VERSION "created by canmatrix"

NS_ :

BS_:

BU_: IPD

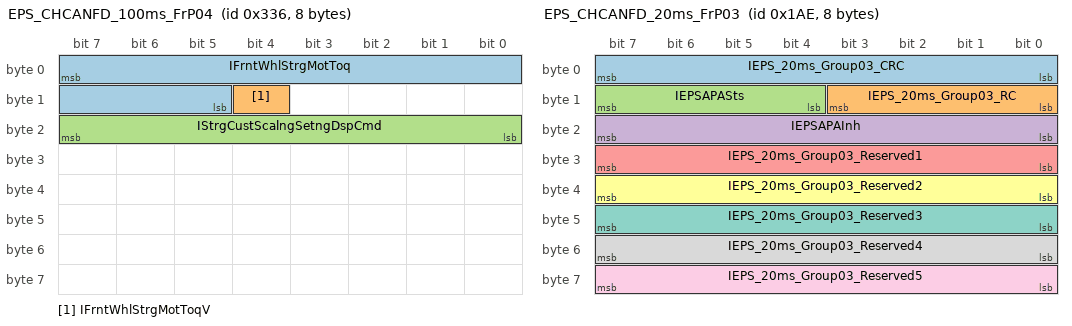
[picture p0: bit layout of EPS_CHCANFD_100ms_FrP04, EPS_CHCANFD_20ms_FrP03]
BO_ 822 EPS_CHCANFD_100ms_FrP04: 8 Vector__XXX
 SG_ IFrntWhlStrgMotToq : 7|11@0+ (0.01,-10.24) [-10.24|10.23] "Nm" IPD
 SG_ IFrntWhlStrgMotToqV : 12|1@0+ (1,0) [0|1] "null" IPD
 SG_ IStrgCustScalngSetngDspCmd : 23|8@0+ (1,0) [0|255] "percent" IPD

BO_ 430 EPS_CHCANFD_20ms_FrP03: 8 Vector__XXX
 SG_ IEPS_20ms_Group03_CRC : 7|8@0+ (1,0) [0|255] "null" IPD
 SG_ IEPS_20ms_Group03_RC : 11|4@0+ (1,0) [0|15] "null" IPD
 SG_ IEPSAPASts : 15|4@0+ (1,0) [0|15] "null" IPD
 SG_ IEPSAPAInh : 23|8@0+ (1,0) [0|255] "null" IPD
 SG_ IEPS_20ms_Group03_Reserved1 : 31|8@0+ (1,0) [0|255] "null" IPD
 SG_ IEPS_20ms_Group03_Reserved2 : 39|8@0+ (1,0) [0|255] "null" IPD
 SG_ IEPS_20ms_Group03_Reserved3 : 47|8@0+ (1,0) [0|255] "null" IPD
 SG_ IEPS_20ms_Group03_Reserved4 : 55|8@0+ (1,0) [0|255] "null" IPD
 SG_ IEPS_20ms_Group03_Reserved5 : 63|8@0+ (1,0) [0|255] "null" IPD

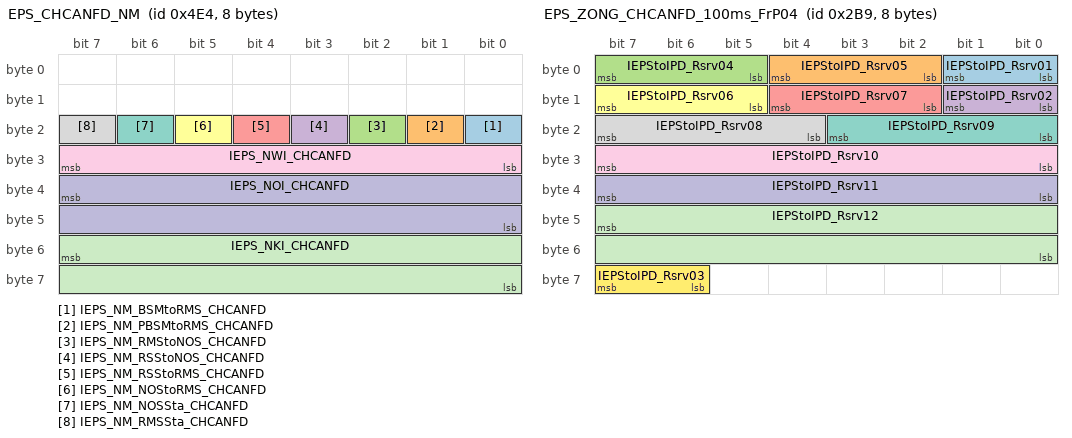
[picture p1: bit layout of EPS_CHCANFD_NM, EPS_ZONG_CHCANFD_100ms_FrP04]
BO_ 1252 EPS_CHCANFD_NM: 8 Vector__XXX
 SG_ IEPS_NM_BSMtoRMS_CHCANFD : 16|1@0+ (1,0) [0|1] "null" Vector__XXX
 SG_ IEPS_NM_PBSMtoRMS_CHCANFD : 17|1@0+ (1,0) [0|1] "null" Vector__XXX
 SG_ IEPS_NM_RMStoNOS_CHCANFD : 18|1@0+ (1,0) [0|1] "null" Vector__XXX
 SG_ IEPS_NM_RSStoNOS_CHCANFD : 19|1@0+ (1,0) [0|1] "null" Vector__XXX
 SG_ IEPS_NM_RSStoRMS_CHCANFD : 20|1@0+ (1,0) [0|1] "null" Vector__XXX
 SG_ IEPS_NM_NOStoRMS_CHCANFD : 21|1@0+ (1,0) [0|1] "null" Vector__XXX
 SG_ IEPS_NM_NOSSta_CHCANFD : 22|1@0+ (1,0) [0|1] "null" Vector__XXX
 SG_ IEPS_NM_RMSSta_CHCANFD : 23|1@0+ (1,0) [0|1] "null" Vector__XXX
 SG_ IEPS_NWI_CHCANFD : 31|8@0+ (1,0) [0|255] "null" Vector__XXX
 SG_ IEPS_NOI_CHCANFD : 39|16@0+ (1,0) [0|65535] "null" Vector__XXX
 SG_ IEPS_NKI_CHCANFD : 55|16@0+ (1,0) [0|65535] "null" IPD

BO_ 697 EPS_ZONG_CHCANFD_100ms_FrP04: 8 Vector__XXX
 SG_ IEPStoIPD_Rsrv01 : 1|2@0+ (1,0) [0|3] "null" IPD
 SG_ IEPStoIPD_Rsrv05 : 4|3@0+ (1,0) [0|7] "null" IPD
 SG_ IEPStoIPD_Rsrv04 : 7|3@0+ (1,0) [0|7] "null" IPD
 SG_ IEPStoIPD_Rsrv02 : 9|2@0+ (1,0) [0|3] "null" IPD
 SG_ IEPStoIPD_Rsrv07 : 12|3@0+ (1,0) [0|7] "null" IPD
 SG_ IEPStoIPD_Rsrv06 : 15|3@0+ (1,0) [0|7] "null" IPD
 SG_ IEPStoIPD_Rsrv09 : 19|4@0+ (1,0) [0|15] "null" IPD
 SG_ IEPStoIPD_Rsrv08 : 23|4@0+ (1,0) [0|15] "null" IPD
 SG_ IEPStoIPD_Rsrv10 : 31|8@0+ (1,0) [0|255] "null" IPD
 SG_ IEPStoIPD_Rsrv11 : 39|8@0+ (1,0) [0|255] "null" IPD
 SG_ IEPStoIPD_Rsrv12 : 47|16@0+ (1,0) [0|65535] "null" IPD
 SG_ IEPStoIPD_Rsrv03 : 63|2@0+ (1,0) [0|3] "null" IPD

BO_ 956 FVCM_BKPCANFD_100ms_FrP05: 64 IPD
 SG_ IPilotSysMsg : 15|4@0+ (1,0) [0|15] "null" Vector__XXX
 SG_ ILane0_C0 : 23|12@0+ (0.00390625,-8) [-8.00000000|7.99609375] "null" Vector__XXX
 SG_ ILane0_C1 : 27|12@0+ (0.00048828125,-1) [-1.00000000000|0.99951171875] "null" Vector__XXX
 SG_ ILane0_C2 : 47|12@0+ (0.000015259,-0.03124285) [-0.031242850|0.031242755] "null" Vector__XXX
 SG_ ILane0_C3 : 51|12@0+ (4.768E-007,-2.3842E-007) [-2.3842E-007|0.00195225758] "null" Vector__XXX
 SG_ ILane1_C0 : 71|12@0+ (0.00390625,-8) [-8.00000000|7.99609375] "null" Vector__XXX
 SG_ ILane1_C1 : 75|12@0+ (0.00048828125,-1) [-1.00000000000|0.99951171875] "null" Vector__XXX
 SG_ ILane1_C2 : 95|12@0+ (0.000015259,-0.03124285) [-0.031242850|0.031242755] "null" Vector__XXX
 SG_ ILane1_C3 : 99|12@0+ (4.768E-007,-2.3842E-007) [-2.3842E-007|0.00195225758] "null" Vector__XXX
 SG_ ILane0_ViewRangeStart : 215|8@0+ (0.25,0) [0.00|63.75] "null" Vector__XXX
 SG_ ILane1_ViewRangeStart : 223|8@0+ (0.25,0) [0.00|63.75] "null" Vector__XXX
 SG_ ILane0_ViewRangeEnd : 247|9@0+ (0.25,0) [0.00|127.75] "null" Vector__XXX
 SG_ ILane1_ViewRangeEnd : 248|9@0+ (0.25,0) [0.00|127.75] "null" Vector__XXX
 SG_ ILane0_ExistPrblty : 254|6@0+ (0.015625,0) [0.000000|0.984375] "null" Vector__XXX
 SG_ ILane1_ExistPrblty : 278|6@0+ (0.015625,0) [0.000000|0.984375] "null" Vector__XXX
 SG_ ILane0_ID : 295|4@0+ (1,0) [0|15] "null" Vector__XXX
 SG_ ILane1_ID : 303|4@0+ (1,0) [0|15] "null" Vector__XXX
 SG_ ITLRMsgReq : 321|2@0+ (1,0) [0|3] "null" Vector__XXX
 SG_ ILane0_location : 327|3@0+ (1,0) [0|7] "null" Vector__XXX
 SG_ ITLRSysSts : 329|2@0+ (1,0) [0|3] "null" Vector__XXX
 SG_ ILane1_location : 332|3@0+ (1,0) [0|7] "null" Vector__XXX
 SG_ ITrgtSpdSrcSts_IPD : 337|2@0+ (1,0) [0|3] "null" Vector__XXX
 SG_ ISLIFWrnngMdResp : 345|2@0+ (1,0) [0|3] "null" Vector__XXX
 SG_ ITLRWarning : 388|3@0+ (1,0) [0|7] "null" Vector__XXX
 SG_ ITLRMdSwDspCmd : 391|3@0+ (1,0) [0|7] "null" Vector__XXX
 SG_ ISpdLmtOfstSetResp : 399|6@0+ (1,-20) [-20|43] "null" Vector__XXX
 SG_ ISLIFAudWrnng_IPD : 472|1@0+ (1,0) [0|1] "null" Vector__XXX
 SG_ ISLIFUpdtIndResp_IPD : 473|1@0+ (1,0) [0|1] "null" Vector__XXX
 SG_ ISLIFUpdtInd_IPD : 500|1@0+ (1,0) [0|1] "null" Vector__XXX
 SG_ ICCSpdVcCmdCnfm : 503|3@0+ (1,0) [0|7] "null" Vector__XXX

BO_ 163 FVCM_BKPCANFD_10ms_FrP01: 12 IPD
 SG_ IFVCM_10ms_Group01_CRC : 7|8@0+ (1,0) [0|255] "null" Vector__XXX
 SG_ IFVCM_10ms_Group01_RC : 11|4@0+ (1,0) [0|15] "null" Vector__XXX
 SG_ ILKAReqToqSts : 13|2@0+ (1,0) [0|3] "null" Vector__XXX
 SG_ ILKAReqAngSts : 15|2@0+ (1,0) [0|3] "null" Vector__XXX
 SG_ ILKAReqAng : 23|16@0+ (0.005,-163) [-163.000|164.675] "Degree" Vector__XXX
 SG_ ILKAReqToq : 39|11@0+ (0.01,-10.24) [-10.24|10.23] "Nm" Vector__XXX
 SG_ IFVCM_10ms_Group01_Reserved1 : 44|5@0+ (1,0) [0|31] "null" Vector__XXX
 SG_ IFVCM_10ms_Group01_Reserved2 : 55|8@0+ (1,0) [0|255] "null" Vector__XXX
 SG_ IFVCM_10ms_Group01_Reserved3 : 63|8@0+ (1,0) [0|255] "null" Vector__XXX
 SG_ IFVCM_10ms_Group01_Reserved4 : 71|8@0+ (1,0) [0|255] "null" Vector__XXX
 SG_ IFVCM_10ms_Group01_Reserved5 : 79|8@0+ (1,0) [0|255] "null" Vector__XXX
 SG_ IFVCM_10ms_Group01_Reserved6 : 87|8@0+ (1,0) [0|255] "null" Vector__XXX
 SG_ IFVCM_10ms_Group01_Reserved7 : 95|8@0+ (1,0) [0|255] "null" Vector__XXX

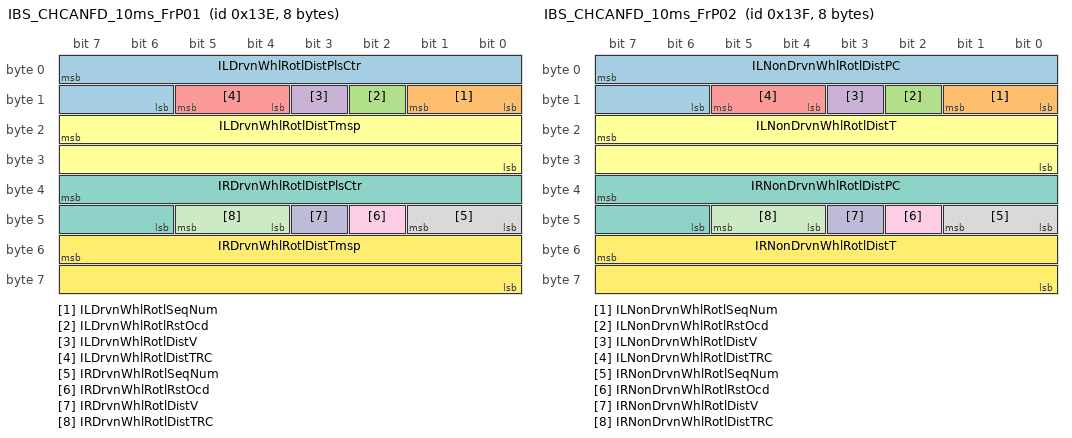
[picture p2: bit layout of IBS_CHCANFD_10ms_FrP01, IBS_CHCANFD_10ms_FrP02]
BO_ 318 IBS_CHCANFD_10ms_FrP01: 8 Vector__XXX
 SG_ ILDrvnWhlRotlDistPlsCtr : 7|10@0+ (1,0) [0|1023] "null" IPD
 SG_ ILDrvnWhlRotlSeqNum : 9|2@0+ (1,0) [0|3] "null" IPD
 SG_ ILDrvnWhlRotlRstOcd : 10|1@0+ (1,0) [0|1] "null" IPD
 SG_ ILDrvnWhlRotlDistV : 11|1@0+ (1,0) [0|1] "null" IPD
 SG_ ILDrvnWhlRotlDistTRC : 13|2@0+ (1,0) [0|3] "null" IPD
 SG_ ILDrvnWhlRotlDistTmsp : 23|16@0+ (1,0) [0|65535] "null" IPD
 SG_ IRDrvnWhlRotlDistPlsCtr : 39|10@0+ (1,0) [0|1023] "null" IPD
 SG_ IRDrvnWhlRotlSeqNum : 41|2@0+ (1,0) [0|3] "ms" IPD
 SG_ IRDrvnWhlRotlRstOcd : 42|1@0+ (1,0) [0|1] "null" IPD
 SG_ IRDrvnWhlRotlDistV : 43|1@0+ (1,0) [0|1] "null" IPD
 SG_ IRDrvnWhlRotlDistTRC : 45|2@0+ (1,0) [0|3] "ms" IPD
 SG_ IRDrvnWhlRotlDistTmsp : 55|16@0+ (1,0) [0|65535] "ms" IPD

BO_ 319 IBS_CHCANFD_10ms_FrP02: 8 Vector__XXX
 SG_ ILNonDrvnWhlRotlDistPC : 7|10@0+ (1,0) [0|1023] "null" IPD
 SG_ ILNonDrvnWhlRotlSeqNum : 9|2@0+ (1,0) [0|3] "null" IPD
 SG_ ILNonDrvnWhlRotlRstOcd : 10|1@0+ (1,0) [0|1] "null" IPD
 SG_ ILNonDrvnWhlRotlDistV : 11|1@0+ (1,0) [0|1] "null" IPD
 SG_ ILNonDrvnWhlRotlDistTRC : 13|2@0+ (1,0) [0|3] "null" IPD
 SG_ ILNonDrvnWhlRotlDistT : 23|16@0+ (1,0) [0|65535] "null" IPD
 SG_ IRNonDrvnWhlRotlDistPC : 39|10@0+ (1,0) [0|1023] "null" IPD
 SG_ IRNonDrvnWhlRotlSeqNum : 41|2@0+ (1,0) [0|3] "null" IPD
 SG_ IRNonDrvnWhlRotlRstOcd : 42|1@0+ (1,0) [0|1] "null" IPD
 SG_ IRNonDrvnWhlRotlDistV : 43|1@0+ (1,0) [0|1] "null" IPD
 SG_ IRNonDrvnWhlRotlDistTRC : 45|2@0+ (1,0) [0|3] "null" IPD
 SG_ IRNonDrvnWhlRotlDistT : 55|16@0+ (1,0) [0|65535] "null" IPD

BO_ 423 IBS_CHCANFD_20ms_FrP07: 8 Vector__XXX
 SG_ IIBS_20ms_Group07_CRC : 7|8@0+ (1,0) [0|255] "null" IPD
 SG_ IIBS_20ms_Group07_RC : 11|4@0+ (1,0) [0|15] "null" IPD
 SG_ IHDCSysSts : 14|3@0+ (1,0) [0|7] "null" IPD
 SG_ IABSIO : 15|1@0+ (1,0) [0|1] "null" IPD
 SG_ IVSESysA : 16|1@0+ (1,0) [0|1] "null" IPD
 SG_ IBrkSysYlwBrkTlltReq : 17|1@0+ (1,0) [0|1] "null" IPD
 SG_ IVSESts : 20|3@0+ (1,0) [0|7] "null" IPD
 SG_ IVSEMd : 23|3@0+ (1,0) [0|7] "null" IPD
 SG_ IMultColBrkEnbA : 24|1@0+ (1,0) [0|1] "null" IPD
 SG_ IEBDFaultSt : 25|1@0+ (1,0) [0|1] "null" IPD
 SG_ ITCSOpngSts : 28|3@0+ (1,0) [0|7] "null" IPD
 SG_ ITCSOpngMd : 31|3@0+ (1,0) [0|7] "null" IPD
 SG_ IBrkSysHillStAstAvlbl : 32|1@0+ (1,0) [0|1] "null" IPD
 SG_ IRgtvBrkFnFltSts : 33|1@0+ (1,0) [0|1] "null" IPD
 SG_ IMSRF : 34|1@0+ (1,0) [0|1] "null" IPD
 SG_ IAutoHoldSysSts : 36|2@0+ (1,0) [0|3] "null" IPD
 SG_ IAutoHoldMsg : 39|3@0+ (1,0) [0|7] "null" IPD
 SG_ IEBDA : 40|1@0+ (1,0) [0|1] "null" IPD
 SG_ IRgtvBrkFnSts : 41|1@0+ (1,0) [0|1] "null" IPD
 SG_ ITCSEnbd : 42|1@0+ (1,0) [0|1] "null" IPD
 SG_ IHBAActiveSt : 43|1@0+ (1,0) [0|1] "null" IPD
 SG_ ITCSA : 44|1@0+ (1,0) [0|1] "null" IPD
 SG_ IEnDragToqRducnA : 45|1@0+ (1,0) [0|1] "null" IPD
 SG_ IABSF : 46|1@0+ (1,0) [0|1] "null" IPD
 SG_ IABSA : 47|1@0+ (1,0) [0|1] "null" IPD
 SG_ IHBAValidSt : 48|1@0+ (1,0) [0|1] "null" IPD
 SG_ IMSRA : 49|1@0+ (1,0) [0|1] "null" IPD
 SG_ IEmgcBrkAV : 50|1@0+ (1,0) [0|1] "null" IPD
 SG_ IEmgcBrkA : 51|1@0+ (1,0) [0|1] "null" IPD
 SG_ IBrkSysRedBrkTlltReq : 52|1@0+ (1,0) [0|1] "null" IPD
 SG_ IBrkSysHillStAstSts : 55|3@0+ (1,0) [0|7] "null" IPD
 SG_ IAVHSigPdlSts : 57|2@0+ (1,0) [0|3] "null" IPD
 SG_ IAutoHoldMdSts : 59|2@0+ (1,0) [0|3] "null" IPD
 SG_ ISoftSpSysSts : 61|2@0+ (1,0) [0|3] "null" IPD
 SG_ IMulColBrkA : 62|1@0+ (1,0) [0|1] "null" IPD
 SG_ IMulColBrkAvlblySts : 63|1@0+ (1,0) [0|1] "null" IPD

BO_ 342 IBS_CHCANFD_20ms_FrP08: 8 Vector__XXX
 SG_ IIBS_20ms_Group08_CRC : 7|8@0+ (1,0) [0|255] "null" IPD
 SG_ IIBS_20ms_Group08_RC : 11|4@0+ (1,0) [0|15] "null" IPD
 SG_ IEPBSts : 13|2@0+ (1,0) [0|3] "null" IPD
 SG_ IEPBAppcnSts : 15|2@0+ (1,0) [0|3] "null" IPD
 SG_ IEPBCCCanclReqd : 16|1@0+ (1,0) [0|1] "null" IPD
 SG_ IEPBSysStsIndReq : 18|2@0+ (1,0) [0|3] "null" IPD
 SG_ IEPBSwSts : 20|2@0+ (1,0) [0|3] "null" IPD
 SG_ IEPBAvlblySts : 23|3@0+ (1,0) [0|7] "null" IPD
 SG_ IEPBSysAudWrnngReq : 25|2@0+ (1,0) [0|3] "null" IPD
 SG_ IEPBSwStsV : 26|1@0+ (1,0) [0|1] "null" IPD
 SG_ IEPBSysWrnngIndReq : 28|2@0+ (1,0) [0|3] "null" IPD
 SG_ IEPBSysDspMsgReq : 31|3@0+ (1,0) [0|7] "null" IPD
 SG_ IChSysTrBrkAxleToqVal : 37|14@0+ (2,0) [0|32766] "Nm" IPD
 SG_ IEPBAPAAvlbl : 38|1@0+ (1,0) [0|1] "null" IPD
 SG_ IEPBFlrSts : 39|1@0+ (1,0) [0|1] "null" IPD
 SG_ IChSysSecyBrkAxleToqVal : 53|14@0+ (2,0) [0|32766] "Nm" IPD
 SG_ IChSysSecyBrkAxleToqValV : 54|1@0+ (1,0) [0|1] "null" IPD
 SG_ IChSysTrBrkAxleToqValV : 55|1@0+ (1,0) [0|1] "null" IPD

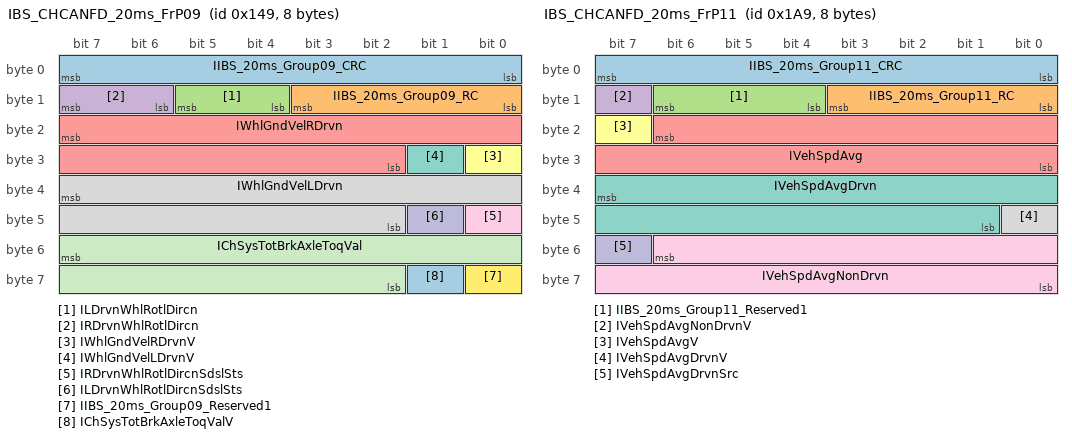
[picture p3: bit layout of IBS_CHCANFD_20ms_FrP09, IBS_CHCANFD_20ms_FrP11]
BO_ 329 IBS_CHCANFD_20ms_FrP09: 8 Vector__XXX
 SG_ IIBS_20ms_Group09_CRC : 7|8@0+ (1,0) [0|255] "ms" IPD
 SG_ IIBS_20ms_Group09_RC : 11|4@0+ (1,0) [0|15] "ms" IPD
 SG_ ILDrvnWhlRotlDircn : 13|2@0+ (1,0) [0|3] "null" IPD
 SG_ IRDrvnWhlRotlDircn : 15|2@0+ (1,0) [0|3] "null" IPD
 SG_ IWhlGndVelRDrvn : 23|14@0+ (0.03125,0) [0.00000|511.96875] "kph" IPD
 SG_ IWhlGndVelRDrvnV : 24|1@0+ (1,0) [0|1] "null" IPD
 SG_ IWhlGndVelLDrvnV : 25|1@0+ (1,0) [0|1] "null" IPD
 SG_ IWhlGndVelLDrvn : 39|14@0+ (0.03125,0) [0.00000|511.96875] "kph" IPD
 SG_ IRDrvnWhlRotlDircnSdslSts : 40|1@0+ (1,0) [0|1] "null" IPD
 SG_ ILDrvnWhlRotlDircnSdslSts : 41|1@0+ (1,0) [0|1] "null" IPD
 SG_ IChSysTotBrkAxleToqVal : 55|14@0+ (2,0) [0|32766] "Nm" IPD
 SG_ IIBS_20ms_Group09_Reserved1 : 56|1@0+ (1,0) [0|1] "null" IPD
 SG_ IChSysTotBrkAxleToqValV : 57|1@0+ (1,0) [0|1] "null" IPD

BO_ 425 IBS_CHCANFD_20ms_FrP11: 8 Vector__XXX
 SG_ IIBS_20ms_Group11_CRC : 7|8@0+ (1,0) [0|255] "null" IPD
 SG_ IIBS_20ms_Group11_RC : 11|4@0+ (1,0) [0|15] "null" IPD
 SG_ IIBS_20ms_Group11_Reserved1 : 14|3@0+ (1,0) [0|7] "null" IPD
 SG_ IVehSpdAvgNonDrvnV : 15|1@0+ (1,0) [0|1] "null" IPD
 SG_ IVehSpdAvg : 22|15@0+ (0.015625,0) [0.000000|511.984375] "km/h" IPD
 SG_ IVehSpdAvgV : 23|1@0+ (1,0) [0|1] "null" IPD
 SG_ IVehSpdAvgDrvn : 39|15@0+ (0.015625,0) [0.000000|511.984375] "km/h" IPD
 SG_ IVehSpdAvgDrvnV : 40|1@0+ (1,0) [0|1] "null" IPD
 SG_ IVehSpdAvgNonDrvn : 54|15@0+ (0.015625,0) [0.000000|511.984375] "km/h" IPD
 SG_ IVehSpdAvgDrvnSrc : 55|1@0+ (1,0) [0|1] "null" IPD

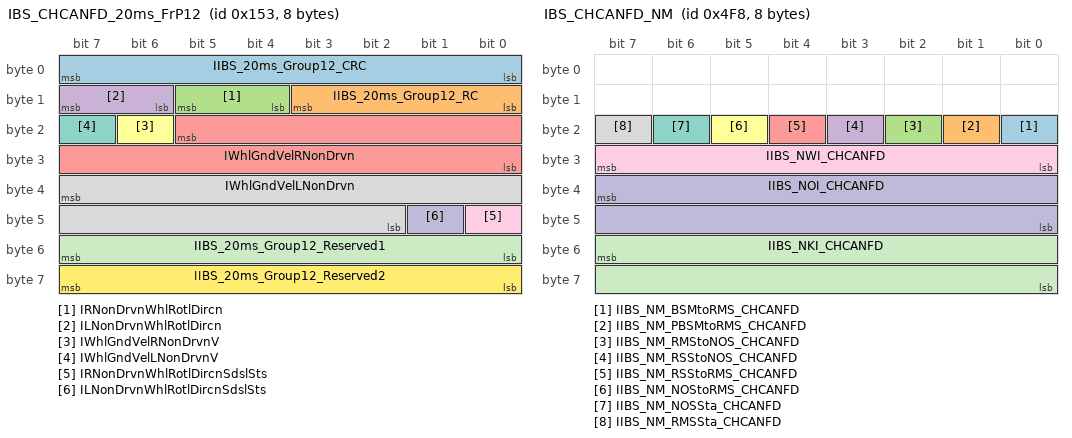
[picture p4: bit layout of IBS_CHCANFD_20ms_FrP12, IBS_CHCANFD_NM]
BO_ 339 IBS_CHCANFD_20ms_FrP12: 8 Vector__XXX
 SG_ IIBS_20ms_Group12_CRC : 7|8@0+ (1,0) [0|255] "ms" IPD
 SG_ IIBS_20ms_Group12_RC : 11|4@0+ (1,0) [0|15] "ms" IPD
 SG_ IRNonDrvnWhlRotlDircn : 13|2@0+ (1,0) [0|3] "null" IPD
 SG_ ILNonDrvnWhlRotlDircn : 15|2@0+ (1,0) [0|3] "null" IPD
 SG_ IWhlGndVelRNonDrvn : 21|14@0+ (0.03125,0) [0.00000|511.96875] "kph" IPD
 SG_ IWhlGndVelRNonDrvnV : 22|1@0+ (1,0) [0|1] "null" IPD
 SG_ IWhlGndVelLNonDrvnV : 23|1@0+ (1,0) [0|1] "null" IPD
 SG_ IWhlGndVelLNonDrvn : 39|14@0+ (0.03125,0) [0.00000|511.96875] "kph" IPD
 SG_ IRNonDrvnWhlRotlDircnSdslSts : 40|1@0+ (1,0) [0|1] "null" IPD
 SG_ ILNonDrvnWhlRotlDircnSdslSts : 41|1@0+ (1,0) [0|1] "null" IPD
 SG_ IIBS_20ms_Group12_Reserved1 : 55|8@0+ (1,0) [0|255] "null" IPD
 SG_ IIBS_20ms_Group12_Reserved2 : 63|8@0+ (1,0) [0|255] "null" IPD

BO_ 1688 IBS_CHCANFD_Event_FrS05: 8 Vector__XXX
 SG_ ISCSToIECUCtrlPotcl : 7|64@0+ (1,0) [0|18446744073709551615] "null" IPD

BO_ 1272 IBS_CHCANFD_NM: 8 Vector__XXX
 SG_ IIBS_NM_BSMtoRMS_CHCANFD : 16|1@0+ (1,0) [0|1] "null" Vector__XXX
 SG_ IIBS_NM_PBSMtoRMS_CHCANFD : 17|1@0+ (1,0) [0|1] "null" Vector__XXX
 SG_ IIBS_NM_RMStoNOS_CHCANFD : 18|1@0+ (1,0) [0|1] "null" Vector__XXX
 SG_ IIBS_NM_RSStoNOS_CHCANFD : 19|1@0+ (1,0) [0|1] "null" Vector__XXX
 SG_ IIBS_NM_RSStoRMS_CHCANFD : 20|1@0+ (1,0) [0|1] "null" Vector__XXX
 SG_ IIBS_NM_NOStoRMS_CHCANFD : 21|1@0+ (1,0) [0|1] "null" Vector__XXX
 SG_ IIBS_NM_NOSSta_CHCANFD : 22|1@0+ (1,0) [0|1] "null" Vector__XXX
 SG_ IIBS_NM_RMSSta_CHCANFD : 23|1@0+ (1,0) [0|1] "null" Vector__XXX
 SG_ IIBS_NWI_CHCANFD : 31|8@0+ (1,0) [0|255] "null" Vector__XXX
 SG_ IIBS_NOI_CHCANFD : 39|16@0+ (1,0) [0|65535] "null" Vector__XXX
 SG_ IIBS_NKI_CHCANFD : 55|16@0+ (1,0) [0|65535] "null" Vector__XXX

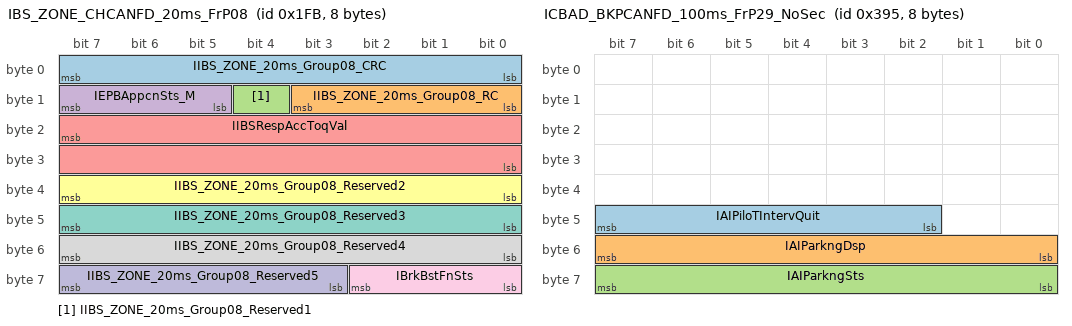
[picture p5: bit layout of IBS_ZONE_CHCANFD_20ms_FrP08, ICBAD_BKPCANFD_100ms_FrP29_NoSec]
BO_ 507 IBS_ZONE_CHCANFD_20ms_FrP08: 8 Vector__XXX
 SG_ IIBS_ZONE_20ms_Group08_CRC : 7|8@0+ (1,0) [0|255] "null" IPD
 SG_ IIBS_ZONE_20ms_Group08_RC : 11|4@0+ (1,0) [0|15] "null" IPD
 SG_ IIBS_ZONE_20ms_Group08_Reserved1 : 12|1@0+ (1,0) [0|1] "null" IPD
 SG_ IEPBAppcnSts_M : 15|3@0+ (1,0) [0|7] "null" IPD
 SG_ IIBSRespAccToqVal : 23|16@0+ (1,0) [0|65535] "Nm" IPD
 SG_ IIBS_ZONE_20ms_Group08_Reserved2 : 39|8@0+ (1,0) [0|255] "null" IPD
 SG_ IIBS_ZONE_20ms_Group08_Reserved3 : 47|8@0+ (1,0) [0|255] "null" IPD
 SG_ IIBS_ZONE_20ms_Group08_Reserved4 : 55|8@0+ (1,0) [0|255] "null" IPD
 SG_ IBrkBstFnSts : 58|3@0+ (1,0) [0|7] "null" IPD
 SG_ IIBS_ZONE_20ms_Group08_Reserved5 : 63|5@0+ (1,0) [0|31] "null" IPD

BO_ 917 ICBAD_BKPCANFD_100ms_FrP29_NoSec: 8 IPD
 SG_ IAIPiloTIntervQuit : 47|6@0+ (1,0) [0|63] "null" Vector__XXX
 SG_ IAIParkngDsp : 55|8@0+ (1,0) [0|255] "null" Vector__XXX
 SG_ IAIParkngSts : 63|8@0+ (1,0) [0|255] "null" Vector__XXX

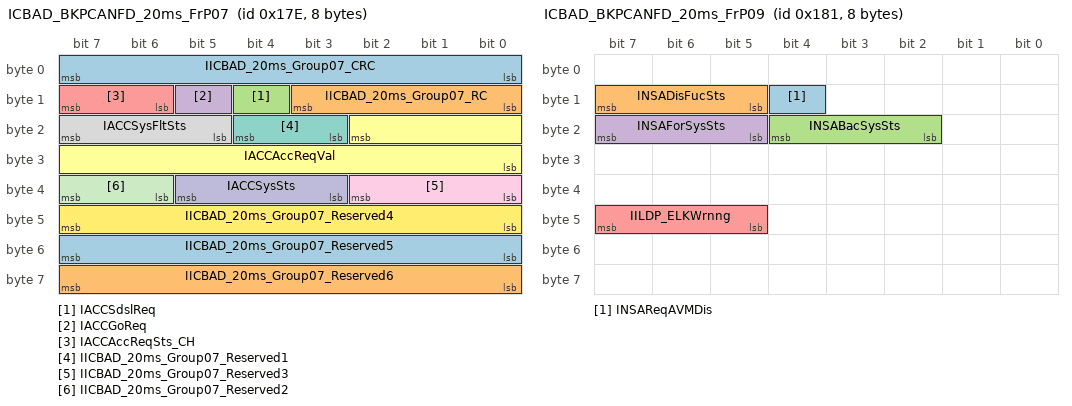
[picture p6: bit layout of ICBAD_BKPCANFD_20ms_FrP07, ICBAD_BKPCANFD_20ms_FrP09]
BO_ 382 ICBAD_BKPCANFD_20ms_FrP07: 8 IPD
 SG_ IICBAD_20ms_Group07_CRC : 7|8@0+ (1,0) [0|255] "null" Vector__XXX
 SG_ IICBAD_20ms_Group07_RC : 11|4@0+ (1,0) [0|15] "null" Vector__XXX
 SG_ IACCSdslReq : 12|1@0+ (1,0) [0|1] "null" Vector__XXX
 SG_ IACCGoReq : 13|1@0+ (1,0) [0|1] "null" Vector__XXX
 SG_ IACCAccReqSts_CH : 15|2@0+ (1,0) [0|3] "null" Vector__XXX
 SG_ IACCAccReqVal : 18|11@0+ (0.006,-10.278) [-10.278|2.004] "null" Vector__XXX
 SG_ IICBAD_20ms_Group07_Reserved1 : 20|2@0+ (1,0) [0|3] "null" Vector__XXX
 SG_ IACCSysFltSts : 23|3@0+ (1,0) [0|7] "null" Vector__XXX
 SG_ IICBAD_20ms_Group07_Reserved3 : 34|3@0+ (1,0) [0|7] "null" Vector__XXX
 SG_ IACCSysSts : 37|3@0+ (1,0) [0|7] "null" Vector__XXX
 SG_ IICBAD_20ms_Group07_Reserved2 : 39|2@0+ (1,0) [0|3] "null" Vector__XXX
 SG_ IICBAD_20ms_Group07_Reserved4 : 47|8@0+ (1,0) [0|255] "null" Vector__XXX
 SG_ IICBAD_20ms_Group07_Reserved5 : 55|8@0+ (1,0) [0|255] "null" Vector__XXX
 SG_ IICBAD_20ms_Group07_Reserved6 : 63|8@0+ (1,0) [0|255] "null" Vector__XXX

BO_ 385 ICBAD_BKPCANFD_20ms_FrP09: 8 IPD
 SG_ INSAReqAVMDis : 12|1@0+ (1,0) [0|1] "null" Vector__XXX
 SG_ INSADisFucSts : 15|3@0+ (1,0) [0|7] "null" Vector__XXX
 SG_ INSABacSysSts : 20|3@0+ (1,0) [0|7] "null" Vector__XXX
 SG_ INSAForSysSts : 23|3@0+ (1,0) [0|7] "null" Vector__XXX
 SG_ IILDP_ELKWrnng : 47|3@0+ (1,0) [0|7] "null" Vector__XXX

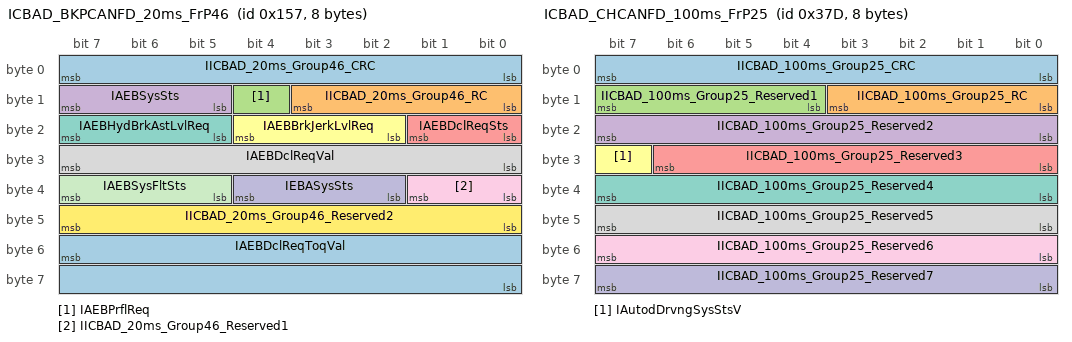
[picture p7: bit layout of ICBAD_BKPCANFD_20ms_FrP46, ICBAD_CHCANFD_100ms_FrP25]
BO_ 343 ICBAD_BKPCANFD_20ms_FrP46: 8 IPD
 SG_ IICBAD_20ms_Group46_CRC : 7|8@0+ (1,0) [0|255] "null" Vector__XXX
 SG_ IICBAD_20ms_Group46_RC : 11|4@0+ (1,0) [0|15] "null" Vector__XXX
 SG_ IAEBPrflReq : 12|1@0+ (1,0) [0|1] "null" Vector__XXX
 SG_ IAEBSysSts : 15|3@0+ (1,0) [0|7] "null" Vector__XXX
 SG_ IAEBDclReqSts : 17|2@0+ (1,0) [0|3] "null" Vector__XXX
 SG_ IAEBBrkJerkLvlReq : 20|3@0+ (1,0) [0|7] "null" Vector__XXX
 SG_ IAEBHydBrkAstLvlReq : 23|3@0+ (1,0) [0|7] "null" Vector__XXX
 SG_ IAEBDclReqVal : 31|8@0+ (0.1,-12.7) [-12.7|12.8] "m/s2" Vector__XXX
 SG_ IICBAD_20ms_Group46_Reserved1 : 33|2@0+ (1,0) [0|3] "null" Vector__XXX
 SG_ IEBASysSts : 36|3@0+ (1,0) [0|7] "null" Vector__XXX
 SG_ IAEBSysFltSts : 39|3@0+ (1,0) [0|7] "null" Vector__XXX
 SG_ IICBAD_20ms_Group46_Reserved2 : 47|8@0+ (1,0) [0|255] "null" Vector__XXX
 SG_ IAEBDclReqToqVal : 55|16@0+ (1,0) [0|65535] "Nm" Vector__XXX

BO_ 893 ICBAD_CHCANFD_100ms_FrP25: 8 IPD
 SG_ IICBAD_100ms_Group25_CRC : 7|8@0+ (1,0) [0|255] "null" Vector__XXX
 SG_ IICBAD_100ms_Group25_RC : 11|4@0+ (1,0) [0|15] "null" Vector__XXX
 SG_ IICBAD_100ms_Group25_Reserved1 : 15|4@0+ (1,0) [0|15] "null" Vector__XXX
 SG_ IICBAD_100ms_Group25_Reserved2 : 23|8@0+ (1,0) [0|255] "null" Vector__XXX
 SG_ IICBAD_100ms_Group25_Reserved3 : 30|7@0+ (1,0) [0|127] "null" Vector__XXX
 SG_ IAutodDrvngSysStsV : 31|1@0+ (1,0) [0|1] "null" Vector__XXX
 SG_ IICBAD_100ms_Group25_Reserved4 : 39|8@0+ (1,0) [0|255] "null" Vector__XXX
 SG_ IICBAD_100ms_Group25_Reserved5 : 47|8@0+ (1,0) [0|255] "null" Vector__XXX
 SG_ IICBAD_100ms_Group25_Reserved6 : 55|8@0+ (1,0) [0|255] "null" Vector__XXX
 SG_ IICBAD_100ms_Group25_Reserved7 : 63|8@0+ (1,0) [0|255] "null" Vector__XXX

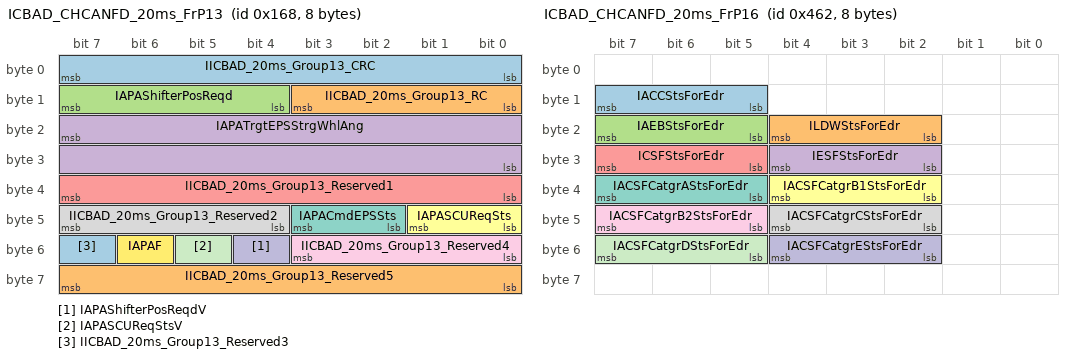
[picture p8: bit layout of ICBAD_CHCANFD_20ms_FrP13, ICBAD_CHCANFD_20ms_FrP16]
BO_ 360 ICBAD_CHCANFD_20ms_FrP13: 8 IPD
 SG_ IICBAD_20ms_Group13_CRC : 7|8@0+ (1,0) [0|255] "null" Vector__XXX
 SG_ IICBAD_20ms_Group13_RC : 11|4@0+ (1,0) [0|15] "null" Vector__XXX
 SG_ IAPAShifterPosReqd : 15|4@0+ (1,0) [0|15] "null" Vector__XXX
 SG_ IAPATrgtEPSStrgWhlAng : 23|16@0+ (0.0625,-2048) [-2048.0000|2047.9375] "null" Vector__XXX
 SG_ IICBAD_20ms_Group13_Reserved1 : 39|8@0+ (1,0) [0|255] "null" Vector__XXX
 SG_ IAPASCUReqSts : 41|2@0+ (1,0) [0|3] "null" Vector__XXX
 SG_ IAPACmdEPSSts : 43|2@0+ (1,0) [0|3] "null" Vector__XXX
 SG_ IICBAD_20ms_Group13_Reserved2 : 47|4@0+ (1,0) [0|15] "null" Vector__XXX
 SG_ IICBAD_20ms_Group13_Reserved4 : 51|4@0+ (1,0) [0|15] "null" Vector__XXX
 SG_ IAPAShifterPosReqdV : 52|1@0+ (1,0) [0|1] "null" Vector__XXX
 SG_ IAPASCUReqStsV : 53|1@0+ (1,0) [0|1] "null" Vector__XXX
 SG_ IAPAF : 54|1@0+ (1,0) [0|1] "null" Vector__XXX
 SG_ IICBAD_20ms_Group13_Reserved3 : 55|1@0+ (1,0) [0|1] "null" Vector__XXX
 SG_ IICBAD_20ms_Group13_Reserved5 : 63|8@0+ (1,0) [0|255] "null" Vector__XXX

BO_ 1122 ICBAD_CHCANFD_20ms_FrP16: 8 IPD
 SG_ IACCStsForEdr : 15|3@0+ (1,0) [0|7] "null" Vector__XXX
 SG_ ILDWStsForEdr : 20|3@0+ (1,0) [0|7] "null" Vector__XXX
 SG_ IAEBStsForEdr : 23|3@0+ (1,0) [0|7] "null" Vector__XXX
 SG_ IESFStsForEdr : 28|3@0+ (1,0) [0|7] "null" Vector__XXX
 SG_ ICSFStsForEdr : 31|3@0+ (1,0) [0|7] "null" Vector__XXX
 SG_ IACSFCatgrB1StsForEdr : 36|3@0+ (1,0) [0|7] "null" Vector__XXX
 SG_ IACSFCatgrAStsForEdr : 39|3@0+ (1,0) [0|7] "null" Vector__XXX
 SG_ IACSFCatgrCStsForEdr : 44|3@0+ (1,0) [0|7] "null" Vector__XXX
 SG_ IACSFCatgrB2StsForEdr : 47|3@0+ (1,0) [0|7] "null" Vector__XXX
 SG_ IACSFCatgrEStsForEdr : 52|3@0+ (1,0) [0|7] "null" Vector__XXX
 SG_ IACSFCatgrDStsForEdr : 55|3@0+ (1,0) [0|7] "null" Vector__XXX

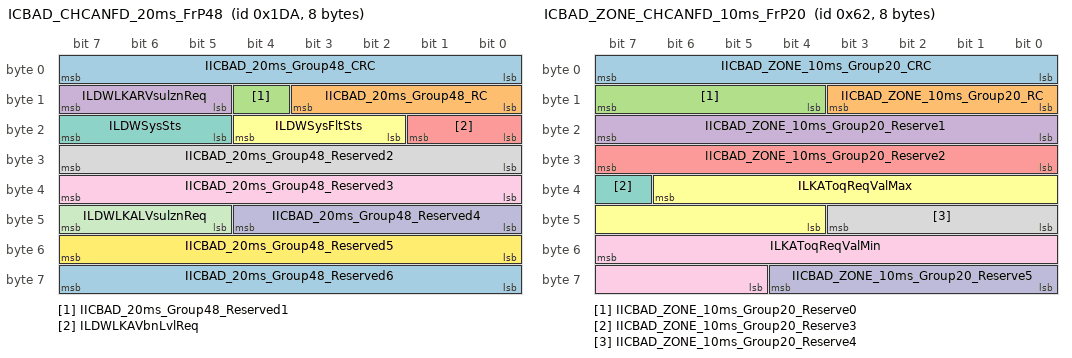
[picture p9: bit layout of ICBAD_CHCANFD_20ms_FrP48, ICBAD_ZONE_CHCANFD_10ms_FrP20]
BO_ 474 ICBAD_CHCANFD_20ms_FrP48: 8 IPD
 SG_ IICBAD_20ms_Group48_CRC : 7|8@0+ (1,0) [0|255] "null" Vector__XXX
 SG_ IICBAD_20ms_Group48_RC : 11|4@0+ (1,0) [0|15] "null" Vector__XXX
 SG_ IICBAD_20ms_Group48_Reserved1 : 12|1@0+ (1,0) [0|1] "null" Vector__XXX
 SG_ ILDWLKARVsulznReq : 15|3@0+ (1,0) [0|7] "null" Vector__XXX
 SG_ ILDWLKAVbnLvlReq : 17|2@0+ (1,0) [0|3] "null" Vector__XXX
 SG_ ILDWSysFltSts : 20|3@0+ (1,0) [0|7] "null" Vector__XXX
 SG_ ILDWSysSts : 23|3@0+ (1,0) [0|7] "null" Vector__XXX
 SG_ IICBAD_20ms_Group48_Reserved2 : 31|8@0+ (1,0) [0|255] "null" Vector__XXX
 SG_ IICBAD_20ms_Group48_Reserved3 : 39|8@0+ (1,0) [0|255] "null" Vector__XXX
 SG_ IICBAD_20ms_Group48_Reserved4 : 44|5@0+ (1,0) [0|31] "null" Vector__XXX
 SG_ ILDWLKALVsulznReq : 47|3@0+ (1,0) [0|7] "null" Vector__XXX
 SG_ IICBAD_20ms_Group48_Reserved5 : 55|8@0+ (1,0) [0|255] "null" Vector__XXX
 SG_ IICBAD_20ms_Group48_Reserved6 : 63|8@0+ (1,0) [0|255] "null" Vector__XXX

BO_ 520 ICBAD_RZCUCANFD_50ms_FrP21: 12 IPD
 SG_ IRPShockDistL : 23|10@0+ (0.02,0) [0.00|20.46] "null" Vector__XXX
 SG_ IRoadProfileShockLevelL : 29|4@0+ (1,0) [0|15] "null" Vector__XXX
 SG_ IRPShockDistR : 39|10@0+ (0.02,0) [0.00|20.46] "null" Vector__XXX
 SG_ IRoadProfileShockLevelR : 45|4@0+ (1,0) [0|15] "null" Vector__XXX
 SG_ IRoadProfileShockHeightL : 55|9@0- (0.002,0) [-0.512|0.510] "null" Vector__XXX
 SG_ IRoadProfileShockDetectedL : 62|1@0+ (1,0) [0|1] "null" Vector__XXX
 SG_ IRoadProfileShockHeightR : 71|9@0- (0.002,0) [-0.512|0.510] "null" Vector__XXX
 SG_ IRoadProfileShockDetectedR : 78|1@0+ (1,0) [0|1] "null" Vector__XXX
 SG_ IRoadProfileShockConfidenceL : 87|7@0+ (0.01,0) [0.00|1.27] "null" Vector__XXX
 SG_ IRoadProfileShockConfidenceR : 95|7@0+ (0.01,0) [0.00|1.27] "null" Vector__XXX

BO_ 98 ICBAD_ZONE_CHCANFD_10ms_FrP20: 8 IPD
 SG_ IICBAD_ZONE_10ms_Group20_CRC : 7|8@0+ (1,0) [0|255] "null" Vector__XXX
 SG_ IICBAD_ZONE_10ms_Group20_RC : 11|4@0+ (1,0) [0|15] "null" Vector__XXX
 SG_ IICBAD_ZONE_10ms_Group20_Reserve0 : 15|4@0+ (1,0) [0|15] "null" Vector__XXX
 SG_ IICBAD_ZONE_10ms_Group20_Reserve1 : 23|8@0+ (1,0) [0|255] "null" Vector__XXX
 SG_ IICBAD_ZONE_10ms_Group20_Reserve2 : 31|8@0+ (1,0) [0|255] "null" Vector__XXX
 SG_ ILKAToqReqValMax : 38|11@0+ (0.01,-10.24) [-10.24|10.23] "Nm" Vector__XXX
 SG_ IICBAD_ZONE_10ms_Group20_Reserve3 : 39|1@0+ (1,0) [0|1] "null" Vector__XXX
 SG_ IICBAD_ZONE_10ms_Group20_Reserve4 : 43|4@0+ (1,0) [0|15] "null" Vector__XXX
 SG_ ILKAToqReqValMin : 55|11@0+ (0.01,-10.24) [-10.24|10.23] "Nm" Vector__XXX
 SG_ IICBAD_ZONE_10ms_Group20_Reserve5 : 60|5@0+ (1,0) [0|31] "null" Vector__XXX

BO_ 502 IMCU_CHCANFD_20ms_FrP58: 16 Vector__XXX
 SG_ IIMCU_20ms_Group58_CRC : 7|8@0+ (1,0) [0|255] "null" IPD
 SG_ IIMCU_20ms_Group58_RC : 11|4@0+ (1,0) [0|15] "null" IPD
 SG_ ICldBdyAdjReq : 15|4@0+ (1,0) [0|15] "null" IPD
 SG_ IVMCExtrmOutSts : 17|2@0+ (1,0) [0|3] "null" IPD
 SG_ IVMCSusHghtLvlReqFA : 20|3@0+ (1,0) [0|7] "null" IPD
 SG_ IVMCASCActvnReq : 23|3@0+ (1,0) [0|7] "null" IPD
 SG_ IIMCU_20ms_Group58_Reserved11 : 24|1@0+ (1,0) [0|1] "null" IPD
 SG_ IVMCSusHghtLvlReqLSide : 28|4@0+ (1,0) [0|15] "null" IPD
 SG_ IVMCSusHghtLvlReqRA : 31|3@0+ (1,0) [0|7] "null" IPD
 SG_ IIMCU_20ms_Group58_Reserved2 : 32|1@0+ (1,0) [0|1] "null" IPD
 SG_ IVMCLvlCtrlReqdTrgtLvl : 36|4@0+ (1,0) [0|15] "null" IPD
 SG_ IIMCU_20ms_Group58_Reserved1 : 39|3@0+ (1,0) [0|7] "null" IPD
 SG_ IVMCSusHghtReqFR : 47|8@0+ (1,-127) [-127|128] "null" IPD
 SG_ IVMCSusHghtReqFL : 55|8@0+ (1,-127) [-127|128] "null" IPD
 SG_ IVMCSusHghtReqRR : 63|8@0+ (1,-127) [-127|128] "null" IPD
 SG_ IVMCSusHghtReqRL : 71|8@0+ (1,-127) [-127|128] "null" IPD
 SG_ IVMCSusHghtLvlReqRSide : 75|4@0+ (1,0) [0|15] "null" IPD
 SG_ IAddlVolmVlvReq : 79|4@0+ (1,0) [0|15] "null" IPD
 SG_ IIMCU_20ms_Group58_Reserved4 : 87|8@0+ (1,0) [0|255] "null" IPD
 SG_ IIMCU_20ms_Group58_Reserved5 : 95|8@0+ (1,0) [0|255] "null" IPD
 SG_ IIMCU_20ms_Group58_Reserved6 : 103|8@0+ (1,0) [0|255] "null" IPD
 SG_ IIMCU_20ms_Group58_Reserved7 : 111|8@0+ (1,0) [0|255] "null" IPD
 SG_ IIMCU_20ms_Group58_Reserved8 : 119|8@0+ (1,0) [0|255] "null" IPD
 SG_ IIMCU_20ms_Group58_Reserved9 : 127|8@0+ (1,0) [0|255] "null" IPD

CM_ BU_ IPD "Tbox->IBox->iCD->IAM(20200706)
DRE ->20200915->20201126
-";

BA_DEF_ BO_ "FrameTriggeringName" STRING;
BA_DEF_ BO_ "GenMsgCycleTime" INT 0 65535;
BA_DEF_ BO_ "GenMsgDelayTime" INT 0 65535;
BA_DEF_ BO_ "GenMsgSendType" ENUM  "cyclicX","spontanX","cyclicIfActiveX","spontanWithDelay","cyclicAndSpontanX","cyclicAndSpontanWithDelay","spontanWithRepitition","cyclicIfActiveAndSpontanWD","cyclicIfActiveFast","cyclicWithRepeatOnDemand","none";
BA_DEF_ BO_ "GenMsgStartValue" STRING;
BA_DEF_ BO_ "PduName" STRING;
BA_DEF_ BO_ "SystemMessageLongSymbol" STRING;
BA_DEF_ BO_ "VFrameFormat" ENUM  "StandardCAN","ExtendedCAN","reserved","reserved","reserved","reserved","reserved","reserved","reserved","reserved","reserved","reserved","reserved","reserved","StandardCAN_FD","ExtendedCAN_FD";
BA_DEF_ SG_ "CompuMethodName" STRING;
BA_DEF_ SG_ "GenSigStartValue" FLOAT 0 100000000000;
BA_DEF_ SG_ "ISignalName" STRING;
BA_DEF_ SG_ "LongName" STRING;
BA_DEF_ SG_ "SysSignalName" STRING;
BA_DEF_ SG_ "SystemSignalLongSymbol" STRING;
BA_DEF_ BU_ "NWM-Knoten" ENUM  "nein","ja";
BA_DEF_ BU_ "NWM-Stationsadresse" HEX 0 63;
BA_DEF_  "BusType" STRING;
BA_ "NWM-Knoten" BU_ IPD 0;
BA_ "NWM-Stationsadresse" BU_ IPD 0;

BA_ "BusType"   "CAN FD";

BA_ "FrameTriggeringName" BO_ 822 "EPS_CHCANFD_100ms_FrP04";
BA_ "GenMsgCycleTime" BO_ 822 100;
BA_ "GenMsgSendType" BO_ 822 0;
BA_ "GenMsgStartValue" BO_ 822 "8010000000000000";
BA_ "PduName" BO_ 822 "EPS_100ms_PDU04";
BA_ "VFrameFormat" BO_ 822 14;
BA_ "FrameTriggeringName" BO_ 430 "EPS_CHCANFD_20ms_FrP03";
BA_ "GenMsgCycleTime" BO_ 430 20;
BA_ "GenMsgSendType" BO_ 430 0;
BA_ "GenMsgStartValue" BO_ 430 "007000ffffffffff";
BA_ "PduName" BO_ 430 "EPS_20ms_PDU03";
BA_ "VFrameFormat" BO_ 430 14;
BA_ "FrameTriggeringName" BO_ 1252 "EPS_CHCANFD_NM";
BA_ "GenMsgSendType" BO_ 1252 1;
BA_ "GenMsgStartValue" BO_ 1252 "0000000000000000";
BA_ "PduName" BO_ 1252 "NmPDU_CHCANFD_EPS";
BA_ "VFrameFormat" BO_ 1252 14;
BA_ "FrameTriggeringName" BO_ 697 "EPS_ZONG_CHCANFD_100ms_FrP04";
BA_ "GenMsgCycleTime" BO_ 697 100;
BA_ "GenMsgSendType" BO_ 697 0;
BA_ "GenMsgStartValue" BO_ 697 "0000000000000000";
BA_ "PduName" BO_ 697 "EPS_ZONE_100ms_PDU04";
BA_ "VFrameFormat" BO_ 697 14;
BA_ "FrameTriggeringName" BO_ 956 "FVCM_BKPCANFD_100ms_FrP05";
BA_ "GenMsgCycleTime" BO_ 956 100;
BA_ "GenMsgSendType" BO_ 956 0;
BA_ "GenMsgStartValue" BO_ 956 "00000000000000000000000000000000000000000000000000000000000000000000000000000000000000000000000000500000000000000000000000000000";
BA_ "PduName" BO_ 956 "FVCM_100ms_PDU05";
BA_ "VFrameFormat" BO_ 956 14;
BA_ "FrameTriggeringName" BO_ 163 "FVCM_BKPCANFD_10ms_FrP01";
BA_ "GenMsgCycleTime" BO_ 163 10;
BA_ "GenMsgSendType" BO_ 163 0;
BA_ "GenMsgStartValue" BO_ 163 "00007f58801fffffffffffff";
BA_ "PduName" BO_ 163 "FVCM_10ms_PDU01";
BA_ "VFrameFormat" BO_ 163 14;
BA_ "FrameTriggeringName" BO_ 318 "IBS_CHCANFD_10ms_FrP01";
BA_ "GenMsgCycleTime" BO_ 318 10;
BA_ "GenMsgSendType" BO_ 318 0;
BA_ "GenMsgStartValue" BO_ 318 "0000000000000000";
BA_ "PduName" BO_ 318 "IBS_10ms_PDU01";
BA_ "VFrameFormat" BO_ 318 14;
BA_ "FrameTriggeringName" BO_ 319 "IBS_CHCANFD_10ms_FrP02";
BA_ "GenMsgCycleTime" BO_ 319 10;
BA_ "GenMsgSendType" BO_ 319 0;
BA_ "GenMsgStartValue" BO_ 319 "0000000000000000";
BA_ "PduName" BO_ 319 "IBS_10ms_PDU02";
BA_ "VFrameFormat" BO_ 319 14;
BA_ "FrameTriggeringName" BO_ 423 "IBS_CHCANFD_20ms_FrP07";
BA_ "GenMsgCycleTime" BO_ 423 20;
BA_ "GenMsgSendType" BO_ 423 0;
BA_ "GenMsgStartValue" BO_ 423 "0000000000010200";
BA_ "PduName" BO_ 423 "IBS_20ms_PDU07";
BA_ "VFrameFormat" BO_ 423 14;
BA_ "FrameTriggeringName" BO_ 342 "IBS_CHCANFD_20ms_FrP08";
BA_ "GenMsgCycleTime" BO_ 342 20;
BA_ "GenMsgSendType" BO_ 342 0;
BA_ "GenMsgStartValue" BO_ 342 "0000000000000000";
BA_ "PduName" BO_ 342 "IBS_20ms_PDU08";
BA_ "VFrameFormat" BO_ 342 14;
BA_ "FrameTriggeringName" BO_ 329 "IBS_CHCANFD_20ms_FrP09";
BA_ "GenMsgCycleTime" BO_ 329 20;
BA_ "GenMsgSendType" BO_ 329 0;
BA_ "GenMsgStartValue" BO_ 329 "00f0000300000001";
BA_ "PduName" BO_ 329 "IBS_20ms_PDU09";
BA_ "VFrameFormat" BO_ 329 14;
BA_ "FrameTriggeringName" BO_ 425 "IBS_CHCANFD_20ms_FrP11";
BA_ "GenMsgCycleTime" BO_ 425 20;
BA_ "GenMsgSendType" BO_ 425 0;
BA_ "GenMsgStartValue" BO_ 425 "0070000100000000";
BA_ "PduName" BO_ 425 "IBS_20ms_PDU11";
BA_ "VFrameFormat" BO_ 425 14;
BA_ "FrameTriggeringName" BO_ 339 "IBS_CHCANFD_20ms_FrP12";
BA_ "GenMsgCycleTime" BO_ 339 20;
BA_ "GenMsgSendType" BO_ 339 0;
BA_ "GenMsgStartValue" BO_ 339 "00f0c0000000ffff";
BA_ "PduName" BO_ 339 "IBS_20ms_PDU12";
BA_ "VFrameFormat" BO_ 339 14;
BA_ "FrameTriggeringName" BO_ 1688 "IBS_CHCANFD_Event_FrS05";
BA_ "GenMsgDelayTime" BO_ 1688 100;
BA_ "GenMsgSendType" BO_ 1688 1;
BA_ "GenMsgStartValue" BO_ 1688 "0000000000000000";
BA_ "PduName" BO_ 1688 "IBS_Sporadic_PDU05";
BA_ "VFrameFormat" BO_ 1688 14;
BA_ "FrameTriggeringName" BO_ 1272 "IBS_CHCANFD_NM";
BA_ "GenMsgSendType" BO_ 1272 1;
BA_ "GenMsgStartValue" BO_ 1272 "0000000000000000";
BA_ "PduName" BO_ 1272 "NmPDU_CHCANFD_IBS";
BA_ "VFrameFormat" BO_ 1272 14;
BA_ "FrameTriggeringName" BO_ 507 "IBS_ZONE_CHCANFD_20ms_FrP08";
BA_ "GenMsgCycleTime" BO_ 507 20;
BA_ "GenMsgSendType" BO_ 507 0;
BA_ "GenMsgStartValue" BO_ 507 "00500000fffffff8";
BA_ "PduName" BO_ 507 "IBS_ZONE_20ms_PDU08";
BA_ "VFrameFormat" BO_ 507 14;
BA_ "FrameTriggeringName" BO_ 917 "ICBAD_BKPCANFD_100ms_FrP29_NoSecOC";
BA_ "GenMsgCycleTime" BO_ 917 100;
BA_ "GenMsgSendType" BO_ 917 0;
BA_ "GenMsgStartValue" BO_ 917 "0000000000000000";
BA_ "PduName" BO_ 917 "ICBAD_100ms_PDU29";
BA_ "SystemMessageLongSymbol" BO_ 917 "ICBAD_BKPCANFD_100ms_FrP29_NoSecOC";
BA_ "VFrameFormat" BO_ 917 14;
BA_ "FrameTriggeringName" BO_ 382 "ICBAD_BKPCANFD_20ms_FrP07";
BA_ "GenMsgCycleTime" BO_ 382 20;
BA_ "GenMsgSendType" BO_ 382 0;
BA_ "GenMsgStartValue" BO_ 382 "00001eb1c7ffffff";
BA_ "PduName" BO_ 382 "ICBAD_20ms_PDU07";
BA_ "VFrameFormat" BO_ 382 14;
BA_ "FrameTriggeringName" BO_ 385 "ICBAD_BKPCANFD_20ms_FrP09";
BA_ "GenMsgCycleTime" BO_ 385 20;
BA_ "GenMsgSendType" BO_ 385 0;
BA_ "GenMsgStartValue" BO_ 385 "0000000000000000";
BA_ "PduName" BO_ 385 "ICBAD_20ms_PDU09";
BA_ "VFrameFormat" BO_ 385 14;
BA_ "FrameTriggeringName" BO_ 343 "ICBAD_BKPCANFD_20ms_FrP46";
BA_ "GenMsgCycleTime" BO_ 343 20;
BA_ "GenMsgSendType" BO_ 343 0;
BA_ "GenMsgStartValue" BO_ 343 "0020007f03ff0000";
BA_ "PduName" BO_ 343 "ICBAD_20ms_PDU46";
BA_ "VFrameFormat" BO_ 343 14;
BA_ "FrameTriggeringName" BO_ 893 "ICBAD_CHCANFD_100ms_FrP25";
BA_ "GenMsgCycleTime" BO_ 893 100;
BA_ "GenMsgSendType" BO_ 893 0;
BA_ "GenMsgStartValue" BO_ 893 "00f0ff7fffffffff";
BA_ "PduName" BO_ 893 "ICBAD_100ms_PDU25";
BA_ "VFrameFormat" BO_ 893 14;
BA_ "FrameTriggeringName" BO_ 360 "ICBAD_CHCANFD_20ms_FrP13";
BA_ "GenMsgCycleTime" BO_ 360 20;
BA_ "GenMsgSendType" BO_ 360 0;
BA_ "GenMsgStartValue" BO_ 360 "00008000fff08fff";
BA_ "PduName" BO_ 360 "ICBAD_20ms_PDU13";
BA_ "VFrameFormat" BO_ 360 14;
BA_ "FrameTriggeringName" BO_ 1122 "ICBAD_CHCANFD_20ms_FrP16";
BA_ "GenMsgCycleTime" BO_ 1122 20;
BA_ "GenMsgSendType" BO_ 1122 0;
BA_ "GenMsgStartValue" BO_ 1122 "0000000000000000";
BA_ "PduName" BO_ 1122 "ICBAD_20ms_PDU16";
BA_ "VFrameFormat" BO_ 1122 14;
BA_ "FrameTriggeringName" BO_ 474 "ICBAD_CHCANFD_20ms_FrP48";
BA_ "GenMsgCycleTime" BO_ 474 20;
BA_ "GenMsgSendType" BO_ 474 0;
BA_ "GenMsgStartValue" BO_ 474 "001000ffff1fffff";
BA_ "PduName" BO_ 474 "ICBAD_20ms_PDU48";
BA_ "VFrameFormat" BO_ 474 14;
BA_ "FrameTriggeringName" BO_ 520 "ICBAD_RZCUCANFD_50ms_FrP21";
BA_ "GenMsgCycleTime" BO_ 520 50;
BA_ "GenMsgSendType" BO_ 520 0;
BA_ "GenMsgStartValue" BO_ 520 "000000000000000000000000";
BA_ "PduName" BO_ 520 "ICBAD_50ms_PDU21";
BA_ "VFrameFormat" BO_ 520 14;
BA_ "FrameTriggeringName" BO_ 98 "ICBAD_ZONE_CHCANFD_10ms_FrP20";
BA_ "GenMsgCycleTime" BO_ 98 10;
BA_ "GenMsgSendType" BO_ 98 0;
BA_ "GenMsgStartValue" BO_ 98 "00f0ffffc00f801f";
BA_ "PduName" BO_ 98 "ICBAD_ZONE_10ms_PDU20";
BA_ "VFrameFormat" BO_ 98 14;
BA_ "FrameTriggeringName" BO_ 502 "IMCU_CHCANFD_20ms_FrP58";
BA_ "GenMsgCycleTime" BO_ 502 20;
BA_ "GenMsgSendType" BO_ 502 0;
BA_ "GenMsgStartValue" BO_ 502 "00000301e30000000000ffffffffffff";
BA_ "PduName" BO_ 502 "IMCU_20ms_PDU58";
BA_ "VFrameFormat" BO_ 502 14;

BA_ "CompuMethodName" SG_ 822 IFrntWhlStrgMotToq "FrntWhlStrgMotToq";
BA_ "ISignalName" SG_ 822 IFrntWhlStrgMotToq "IFrntWhlStrgMotToq";
BA_ "LongName" SG_ 822 IFrntWhlStrgMotToq "Front Wheel Steering Motor Torque";
BA_ "SysSignalName" SG_ 822 IFrntWhlStrgMotToq "FrntWhlStrgMotToq";
BA_ "CompuMethodName" SG_ 822 IFrntWhlStrgMotToqV "FrntWhlStrgMotToqV";
BA_ "GenSigStartValue" SG_ 822 IFrntWhlStrgMotToqV 1;
BA_ "ISignalName" SG_ 822 IFrntWhlStrgMotToqV "IFrntWhlStrgMotToqV";
BA_ "LongName" SG_ 822 IFrntWhlStrgMotToqV "Front Wheel Steering Motor Torque Validity";
BA_ "SysSignalName" SG_ 822 IFrntWhlStrgMotToqV "FrntWhlStrgMotToqV";
BA_ "CompuMethodName" SG_ 822 IStrgCustScalngSetngDspCmd "StrgCustScalngSetngDspCmd";
BA_ "ISignalName" SG_ 822 IStrgCustScalngSetngDspCmd "IStrgCustScalngSetngDspCmd";
BA_ "LongName" SG_ 822 IStrgCustScalngSetngDspCmd "Steering Custom Scaling Setting Display Command";
BA_ "SysSignalName" SG_ 822 IStrgCustScalngSetngDspCmd "StrgCustScalngSetngDspCmd";
BA_ "CompuMethodName" SG_ 430 IEPS_20ms_Group03_CRC "EPS_20ms_Group03_CRC";
BA_ "ISignalName" SG_ 430 IEPS_20ms_Group03_CRC "IEPS_20ms_Group03_CRC";
BA_ "SysSignalName" SG_ 430 IEPS_20ms_Group03_CRC "EPS_20ms_Group03_CRC";
BA_ "CompuMethodName" SG_ 430 IEPS_20ms_Group03_RC "EPS_20ms_Group03_RC";
BA_ "ISignalName" SG_ 430 IEPS_20ms_Group03_RC "IEPS_20ms_Group03_RC";
BA_ "SysSignalName" SG_ 430 IEPS_20ms_Group03_RC "EPS_20ms_Group03_RC";
BA_ "CompuMethodName" SG_ 430 IEPSAPASts "EPSAPASts";
BA_ "GenSigStartValue" SG_ 430 IEPSAPASts 7;
BA_ "ISignalName" SG_ 430 IEPSAPASts "IEPSAPASts";
BA_ "LongName" SG_ 430 IEPSAPASts "Electric Power Steering Advanced Park Assist Status";
BA_ "SysSignalName" SG_ 430 IEPSAPASts "EPSAPASts";
BA_ "CompuMethodName" SG_ 430 IEPSAPAInh "EPSAPAInh";
BA_ "ISignalName" SG_ 430 IEPSAPAInh "IEPSAPAInh";
BA_ "LongName" SG_ 430 IEPSAPAInh "Electric Power Steering Advanced Park Assist Inhibit";
BA_ "SysSignalName" SG_ 430 IEPSAPAInh "EPSAPAInh";
BA_ "CompuMethodName" SG_ 430 IEPS_20ms_Group03_Reserved1 "EPS_20ms_Group03_Reserved1";
BA_ "GenSigStartValue" SG_ 430 IEPS_20ms_Group03_Reserved1 255;
BA_ "ISignalName" SG_ 430 IEPS_20ms_Group03_Reserved1 "IEPS_20ms_Group03_Reserved1";
BA_ "SysSignalName" SG_ 430 IEPS_20ms_Group03_Reserved1 "EPS_20ms_Group03_Reserved1";
BA_ "CompuMethodName" SG_ 430 IEPS_20ms_Group03_Reserved2 "EPS_20ms_Group03_Reserved2";
BA_ "GenSigStartValue" SG_ 430 IEPS_20ms_Group03_Reserved2 255;
BA_ "ISignalName" SG_ 430 IEPS_20ms_Group03_Reserved2 "IEPS_20ms_Group03_Reserved2";
BA_ "SysSignalName" SG_ 430 IEPS_20ms_Group03_Reserved2 "EPS_20ms_Group03_Reserved2";
BA_ "CompuMethodName" SG_ 430 IEPS_20ms_Group03_Reserved3 "EPS_20ms_Group03_Reserved3";
BA_ "GenSigStartValue" SG_ 430 IEPS_20ms_Group03_Reserved3 255;
BA_ "ISignalName" SG_ 430 IEPS_20ms_Group03_Reserved3 "IEPS_20ms_Group03_Reserved3";
BA_ "SysSignalName" SG_ 430 IEPS_20ms_Group03_Reserved3 "EPS_20ms_Group03_Reserved3";
BA_ "CompuMethodName" SG_ 430 IEPS_20ms_Group03_Reserved4 "EPS_20ms_Group03_Reserved4";
BA_ "GenSigStartValue" SG_ 430 IEPS_20ms_Group03_Reserved4 255;
BA_ "ISignalName" SG_ 430 IEPS_20ms_Group03_Reserved4 "IEPS_20ms_Group03_Reserved4";
BA_ "SysSignalName" SG_ 430 IEPS_20ms_Group03_Reserved4 "EPS_20ms_Group03_Reserved4";
BA_ "CompuMethodName" SG_ 430 IEPS_20ms_Group03_Reserved5 "EPS_20ms_Group03_Reserved5";
BA_ "GenSigStartValue" SG_ 430 IEPS_20ms_Group03_Reserved5 255;
BA_ "ISignalName" SG_ 430 IEPS_20ms_Group03_Reserved5 "IEPS_20ms_Group03_Reserved5";
BA_ "SysSignalName" SG_ 430 IEPS_20ms_Group03_Reserved5 "EPS_20ms_Group03_Reserved5";
BA_ "CompuMethodName" SG_ 1252 IEPS_NM_BSMtoRMS_CHCANFD "EPS_NM_BSMtoRMS_CHCANFD";
BA_ "ISignalName" SG_ 1252 IEPS_NM_BSMtoRMS_CHCANFD "IEPS_NM_BSMtoRMS_CHCANFD";
BA_ "LongName" SG_ 1252 IEPS_NM_BSMtoRMS_CHCANFD "EPS NM BSMtoRMS CHCANFD";
BA_ "SysSignalName" SG_ 1252 IEPS_NM_BSMtoRMS_CHCANFD "EPS_NM_BSMtoRMS_CHCANFD";
BA_ "CompuMethodName" SG_ 1252 IEPS_NM_PBSMtoRMS_CHCANFD "EPS_NM_PBSMtoRMS_CHCANFD";
BA_ "ISignalName" SG_ 1252 IEPS_NM_PBSMtoRMS_CHCANFD "IEPS_NM_PBSMtoRMS_CHCANFD";
BA_ "LongName" SG_ 1252 IEPS_NM_PBSMtoRMS_CHCANFD "EPS NM PBSMtoRMS CHCANFD";
BA_ "SysSignalName" SG_ 1252 IEPS_NM_PBSMtoRMS_CHCANFD "EPS_NM_PBSMtoRMS_CHCANFD";
BA_ "CompuMethodName" SG_ 1252 IEPS_NM_RMStoNOS_CHCANFD "EPS_NM_RMStoNOS_CHCANFD";
BA_ "ISignalName" SG_ 1252 IEPS_NM_RMStoNOS_CHCANFD "IEPS_NM_RMStoNOS_CHCANFD";
BA_ "LongName" SG_ 1252 IEPS_NM_RMStoNOS_CHCANFD "EPS NM RMStoNOS CHCANFD";
BA_ "SysSignalName" SG_ 1252 IEPS_NM_RMStoNOS_CHCANFD "EPS_NM_RMStoNOS_CHCANFD";
BA_ "CompuMethodName" SG_ 1252 IEPS_NM_RSStoNOS_CHCANFD "EPS_NM_RSStoNOS_CHCANFD";
BA_ "ISignalName" SG_ 1252 IEPS_NM_RSStoNOS_CHCANFD "IEPS_NM_RSStoNOS_CHCANFD";
BA_ "LongName" SG_ 1252 IEPS_NM_RSStoNOS_CHCANFD "EPS NM RSStoNOS CHCANFD";
BA_ "SysSignalName" SG_ 1252 IEPS_NM_RSStoNOS_CHCANFD "EPS_NM_RSStoNOS_CHCANFD";
BA_ "CompuMethodName" SG_ 1252 IEPS_NM_RSStoRMS_CHCANFD "EPS_NM_RSStoRMS_CHCANFD";
BA_ "ISignalName" SG_ 1252 IEPS_NM_RSStoRMS_CHCANFD "IEPS_NM_RSStoRMS_CHCANFD";
BA_ "LongName" SG_ 1252 IEPS_NM_RSStoRMS_CHCANFD "EPS NM RSStoRMS CHCANFD";
BA_ "SysSignalName" SG_ 1252 IEPS_NM_RSStoRMS_CHCANFD "EPS_NM_RSStoRMS_CHCANFD";
BA_ "CompuMethodName" SG_ 1252 IEPS_NM_NOStoRMS_CHCANFD "EPS_NM_NOStoRMS_CHCANFD";
BA_ "ISignalName" SG_ 1252 IEPS_NM_NOStoRMS_CHCANFD "IEPS_NM_NOStoRMS_CHCANFD";
BA_ "LongName" SG_ 1252 IEPS_NM_NOStoRMS_CHCANFD "EPS NM NOStoRMS CHCANFD";
BA_ "SysSignalName" SG_ 1252 IEPS_NM_NOStoRMS_CHCANFD "EPS_NM_NOStoRMS_CHCANFD";
BA_ "CompuMethodName" SG_ 1252 IEPS_NM_NOSSta_CHCANFD "EPS_NM_NOSSta_CHCANFD";
BA_ "ISignalName" SG_ 1252 IEPS_NM_NOSSta_CHCANFD "IEPS_NM_NOSSta_CHCANFD";
BA_ "LongName" SG_ 1252 IEPS_NM_NOSSta_CHCANFD "EPS NM NOSSta CHCANFD";
BA_ "SysSignalName" SG_ 1252 IEPS_NM_NOSSta_CHCANFD "EPS_NM_NOSSta_CHCANFD";
BA_ "CompuMethodName" SG_ 1252 IEPS_NM_RMSSta_CHCANFD "EPS_NM_RMSSta_CHCANFD";
BA_ "ISignalName" SG_ 1252 IEPS_NM_RMSSta_CHCANFD "IEPS_NM_RMSSta_CHCANFD";
BA_ "LongName" SG_ 1252 IEPS_NM_RMSSta_CHCANFD "EPS NM RMSSta CHCANFD";
BA_ "SysSignalName" SG_ 1252 IEPS_NM_RMSSta_CHCANFD "EPS_NM_RMSSta_CHCANFD";
BA_ "CompuMethodName" SG_ 1252 IEPS_NWI_CHCANFD "EPS_NWI_CHCANFD";
BA_ "ISignalName" SG_ 1252 IEPS_NWI_CHCANFD "IEPS_NWI_CHCANFD";
BA_ "LongName" SG_ 1252 IEPS_NWI_CHCANFD "EPS CHCANFD Network Wakeup Indication";
BA_ "SysSignalName" SG_ 1252 IEPS_NWI_CHCANFD "EPS_NWI_CHCANFD";
BA_ "CompuMethodName" SG_ 1252 IEPS_NOI_CHCANFD "EPS_NOI_CHCANFD";
BA_ "ISignalName" SG_ 1252 IEPS_NOI_CHCANFD "IEPS_NOI_CHCANFD";
BA_ "LongName" SG_ 1252 IEPS_NOI_CHCANFD "EPS CHCANFD Network Operation Indication";
BA_ "SysSignalName" SG_ 1252 IEPS_NOI_CHCANFD "EPS_NOI_CHCANFD";
BA_ "CompuMethodName" SG_ 1252 IEPS_NKI_CHCANFD "EPS_NKI_CHCANFD";
BA_ "ISignalName" SG_ 1252 IEPS_NKI_CHCANFD "IEPS_NKI_CHCANFD";
BA_ "LongName" SG_ 1252 IEPS_NKI_CHCANFD "EPS CHCANFD Network Keep Indication";
BA_ "SysSignalName" SG_ 1252 IEPS_NKI_CHCANFD "EPS_NKI_CHCANFD";
BA_ "CompuMethodName" SG_ 697 IEPStoIPD_Rsrv01 "EPStoIPD_Rsrv01";
BA_ "ISignalName" SG_ 697 IEPStoIPD_Rsrv01 "IEPStoIPD_Rsrv01";
BA_ "LongName" SG_ 697 IEPStoIPD_Rsrv01 "EPS_to_IPD_Reserved01";
BA_ "SysSignalName" SG_ 697 IEPStoIPD_Rsrv01 "EPStoIPD_Rsrv01";
BA_ "CompuMethodName" SG_ 697 IEPStoIPD_Rsrv05 "EPStoIPD_Rsrv05";
BA_ "ISignalName" SG_ 697 IEPStoIPD_Rsrv05 "IEPStoIPD_Rsrv05";
BA_ "LongName" SG_ 697 IEPStoIPD_Rsrv05 "EPS_to_IPD_Reserved05";
BA_ "SysSignalName" SG_ 697 IEPStoIPD_Rsrv05 "EPStoIPD_Rsrv05";
BA_ "CompuMethodName" SG_ 697 IEPStoIPD_Rsrv04 "EPStoIPD_Rsrv04";
BA_ "ISignalName" SG_ 697 IEPStoIPD_Rsrv04 "IEPStoIPD_Rsrv04";
BA_ "LongName" SG_ 697 IEPStoIPD_Rsrv04 "EPS_to_IPD_Reserved04";
BA_ "SysSignalName" SG_ 697 IEPStoIPD_Rsrv04 "EPStoIPD_Rsrv04";
BA_ "CompuMethodName" SG_ 697 IEPStoIPD_Rsrv02 "EPStoIPD_Rsrv02";
BA_ "ISignalName" SG_ 697 IEPStoIPD_Rsrv02 "IEPStoIPD_Rsrv02";
BA_ "LongName" SG_ 697 IEPStoIPD_Rsrv02 "EPS_to_IPD_Reserved02";
BA_ "SysSignalName" SG_ 697 IEPStoIPD_Rsrv02 "EPStoIPD_Rsrv02";
BA_ "CompuMethodName" SG_ 697 IEPStoIPD_Rsrv07 "EPStoIPD_Rsrv07";
BA_ "ISignalName" SG_ 697 IEPStoIPD_Rsrv07 "IEPStoIPD_Rsrv07";
BA_ "LongName" SG_ 697 IEPStoIPD_Rsrv07 "EPS_to_IPD_Reserved07";
BA_ "SysSignalName" SG_ 697 IEPStoIPD_Rsrv07 "EPStoIPD_Rsrv07";
BA_ "CompuMethodName" SG_ 697 IEPStoIPD_Rsrv06 "EPStoIPD_Rsrv06";
BA_ "ISignalName" SG_ 697 IEPStoIPD_Rsrv06 "IEPStoIPD_Rsrv06";
BA_ "LongName" SG_ 697 IEPStoIPD_Rsrv06 "EPS_to_IPD_Reserved06";
BA_ "SysSignalName" SG_ 697 IEPStoIPD_Rsrv06 "EPStoIPD_Rsrv06";
BA_ "CompuMethodName" SG_ 697 IEPStoIPD_Rsrv09 "EPStoIPD_Rsrv09";
BA_ "ISignalName" SG_ 697 IEPStoIPD_Rsrv09 "IEPStoIPD_Rsrv09";
BA_ "LongName" SG_ 697 IEPStoIPD_Rsrv09 "EPS_to_IPD_Reserved09";
BA_ "SysSignalName" SG_ 697 IEPStoIPD_Rsrv09 "EPStoIPD_Rsrv09";
BA_ "CompuMethodName" SG_ 697 IEPStoIPD_Rsrv08 "EPStoIPD_Rsrv08";
BA_ "ISignalName" SG_ 697 IEPStoIPD_Rsrv08 "IEPStoIPD_Rsrv08";
BA_ "LongName" SG_ 697 IEPStoIPD_Rsrv08 "EPS_to_IPD_Reserved08";
BA_ "SysSignalName" SG_ 697 IEPStoIPD_Rsrv08 "EPStoIPD_Rsrv08";
BA_ "CompuMethodName" SG_ 697 IEPStoIPD_Rsrv10 "EPStoIPD_Rsrv10";
BA_ "ISignalName" SG_ 697 IEPStoIPD_Rsrv10 "IEPStoIPD_Rsrv10";
BA_ "LongName" SG_ 697 IEPStoIPD_Rsrv10 "EPS_to_IPD_Reserved10";
BA_ "SysSignalName" SG_ 697 IEPStoIPD_Rsrv10 "EPStoIPD_Rsrv10";
BA_ "CompuMethodName" SG_ 697 IEPStoIPD_Rsrv11 "EPStoIPD_Rsrv11";
BA_ "ISignalName" SG_ 697 IEPStoIPD_Rsrv11 "IEPStoIPD_Rsrv11";
BA_ "LongName" SG_ 697 IEPStoIPD_Rsrv11 "EPS_to_IPD_Reserved11";
BA_ "SysSignalName" SG_ 697 IEPStoIPD_Rsrv11 "EPStoIPD_Rsrv11";
BA_ "CompuMethodName" SG_ 697 IEPStoIPD_Rsrv12 "EPStoIPD_Rsrv12";
BA_ "ISignalName" SG_ 697 IEPStoIPD_Rsrv12 "IEPStoIPD_Rsrv12";
BA_ "LongName" SG_ 697 IEPStoIPD_Rsrv12 "EPS_to_IPD_Reserved12";
BA_ "SysSignalName" SG_ 697 IEPStoIPD_Rsrv12 "EPStoIPD_Rsrv12";
BA_ "CompuMethodName" SG_ 697 IEPStoIPD_Rsrv03 "EPStoIPD_Rsrv03";
BA_ "ISignalName" SG_ 697 IEPStoIPD_Rsrv03 "IEPStoIPD_Rsrv03";
BA_ "LongName" SG_ 697 IEPStoIPD_Rsrv03 "EPS_to_IPD_Reserved03";
BA_ "SysSignalName" SG_ 697 IEPStoIPD_Rsrv03 "EPStoIPD_Rsrv03";
BA_ "CompuMethodName" SG_ 956 IPilotSysMsg "PilotSysMsg";
BA_ "ISignalName" SG_ 956 IPilotSysMsg "IPilotSysMsg";
BA_ "LongName" SG_ 956 IPilotSysMsg "Pilot System Message";
BA_ "SysSignalName" SG_ 956 IPilotSysMsg "PilotSysMsg";
BA_ "CompuMethodName" SG_ 956 ILane0_C0 "Lane0_C0";
BA_ "ISignalName" SG_ 956 ILane0_C0 "ILane0_C0";
BA_ "LongName" SG_ 956 ILane0_C0 "Lane_0_Curve_Parameter_C0";
BA_ "SysSignalName" SG_ 956 ILane0_C0 "Lane0_C0";
BA_ "CompuMethodName" SG_ 956 ILane0_C1 "Lane0_C1";
BA_ "ISignalName" SG_ 956 ILane0_C1 "ILane0_C1";
BA_ "LongName" SG_ 956 ILane0_C1 "Lane_0_Curve_Parameter_C1";
BA_ "SysSignalName" SG_ 956 ILane0_C1 "Lane0_C1";
BA_ "CompuMethodName" SG_ 956 ILane0_C2 "Lane0_C2";
BA_ "ISignalName" SG_ 956 ILane0_C2 "ILane0_C2";
BA_ "LongName" SG_ 956 ILane0_C2 "Lane_0_Curve_Parameter_C2";
BA_ "SysSignalName" SG_ 956 ILane0_C2 "Lane0_C2";
BA_ "CompuMethodName" SG_ 956 ILane0_C3 "Lane0_C3";
BA_ "ISignalName" SG_ 956 ILane0_C3 "ILane0_C3";
BA_ "LongName" SG_ 956 ILane0_C3 "Lane_0_Curve_Parameter_C3";
BA_ "SysSignalName" SG_ 956 ILane0_C3 "Lane0_C3";
BA_ "CompuMethodName" SG_ 956 ILane1_C0 "Lane1_C0";
BA_ "ISignalName" SG_ 956 ILane1_C0 "ILane1_C0";
BA_ "LongName" SG_ 956 ILane1_C0 "Lane_1_Curve_Parameter_C0";
BA_ "SysSignalName" SG_ 956 ILane1_C0 "Lane1_C0";
BA_ "CompuMethodName" SG_ 956 ILane1_C1 "Lane1_C1";
BA_ "ISignalName" SG_ 956 ILane1_C1 "ILane1_C1";
BA_ "LongName" SG_ 956 ILane1_C1 "Lane_1_Curve_Parameter_C1";
BA_ "SysSignalName" SG_ 956 ILane1_C1 "Lane1_C1";
BA_ "CompuMethodName" SG_ 956 ILane1_C2 "Lane1_C2";
BA_ "ISignalName" SG_ 956 ILane1_C2 "ILane1_C2";
BA_ "LongName" SG_ 956 ILane1_C2 "Lane_1_Curve_Parameter_C2";
BA_ "SysSignalName" SG_ 956 ILane1_C2 "Lane1_C2";
BA_ "CompuMethodName" SG_ 956 ILane1_C3 "Lane1_C3";
BA_ "ISignalName" SG_ 956 ILane1_C3 "ILane1_C3";
BA_ "LongName" SG_ 956 ILane1_C3 "Lane_1_Curve_Parameter_C3";
BA_ "SysSignalName" SG_ 956 ILane1_C3 "Lane1_C3";
BA_ "CompuMethodName" SG_ 956 ILane0_ViewRangeStart "Lane0_ViewRangeStart";
BA_ "ISignalName" SG_ 956 ILane0_ViewRangeStart "ILane0_ViewRangeStart";
BA_ "LongName" SG_ 956 ILane0_ViewRangeStart "Lane_0_Curve_Longitudinal_Distance_Start";
BA_ "SysSignalName" SG_ 956 ILane0_ViewRangeStart "Lane0_ViewRangeStart";
BA_ "CompuMethodName" SG_ 956 ILane1_ViewRangeStart "Lane1_ViewRangeStart";
BA_ "ISignalName" SG_ 956 ILane1_ViewRangeStart "ILane1_ViewRangeStart";
BA_ "LongName" SG_ 956 ILane1_ViewRangeStart "Lane_1_Curve_Longitudinal_Distance_Start";
BA_ "SysSignalName" SG_ 956 ILane1_ViewRangeStart "Lane1_ViewRangeStart";
BA_ "CompuMethodName" SG_ 956 ILane0_ViewRangeEnd "Lane0_ViewRangeEnd";
BA_ "ISignalName" SG_ 956 ILane0_ViewRangeEnd "ILane0_ViewRangeEnd";
BA_ "LongName" SG_ 956 ILane0_ViewRangeEnd "Lane_0_Curve_Longitudinal_Distance_Stop";
BA_ "SysSignalName" SG_ 956 ILane0_ViewRangeEnd "Lane0_ViewRangeEnd";
BA_ "CompuMethodName" SG_ 956 ILane1_ViewRangeEnd "Lane1_ViewRangeEnd";
BA_ "ISignalName" SG_ 956 ILane1_ViewRangeEnd "ILane1_ViewRangeEnd";
BA_ "LongName" SG_ 956 ILane1_ViewRangeEnd "Lane_1_Curve_Longitudinal_Distance_Stop";
BA_ "SysSignalName" SG_ 956 ILane1_ViewRangeEnd "Lane1_ViewRangeEnd";
BA_ "CompuMethodName" SG_ 956 ILane0_ExistPrblty "Lane0_ExistPrblty";
BA_ "ISignalName" SG_ 956 ILane0_ExistPrblty "ILane0_ExistPrblty";
BA_ "LongName" SG_ 956 ILane0_ExistPrblty "Lane_0_Exist_Probability";
BA_ "SysSignalName" SG_ 956 ILane0_ExistPrblty "Lane0_ExistPrblty";
BA_ "CompuMethodName" SG_ 956 ILane1_ExistPrblty "Lane1_ExistPrblty";
BA_ "ISignalName" SG_ 956 ILane1_ExistPrblty "ILane1_ExistPrblty";
BA_ "LongName" SG_ 956 ILane1_ExistPrblty "Lane_1_Exist_Probability";
BA_ "SysSignalName" SG_ 956 ILane1_ExistPrblty "Lane1_ExistPrblty";
BA_ "CompuMethodName" SG_ 956 ILane0_ID "Lane0_ID";
BA_ "ISignalName" SG_ 956 ILane0_ID "ILane0_ID";
BA_ "LongName" SG_ 956 ILane0_ID "Lane_0_Identifier";
BA_ "SysSignalName" SG_ 956 ILane0_ID "Lane0_ID";
BA_ "CompuMethodName" SG_ 956 ILane1_ID "Lane1_ID";
BA_ "ISignalName" SG_ 956 ILane1_ID "ILane1_ID";
BA_ "LongName" SG_ 956 ILane1_ID "Lane_1_Identifier";
BA_ "SysSignalName" SG_ 956 ILane1_ID "Lane1_ID";
BA_ "CompuMethodName" SG_ 956 ITLRMsgReq "TLRMsgReq";
BA_ "ISignalName" SG_ 956 ITLRMsgReq "ITLRMsgReq";
BA_ "LongName" SG_ 956 ITLRMsgReq "Traffic_lights_recognition_Message_Request";
BA_ "SysSignalName" SG_ 956 ITLRMsgReq "TLRMsgReq";
BA_ "CompuMethodName" SG_ 956 ILane0_location "Lane0_location";
BA_ "ISignalName" SG_ 956 ILane0_location "ILane0_location";
BA_ "LongName" SG_ 956 ILane0_location "Lane_0_Position";
BA_ "SysSignalName" SG_ 956 ILane0_location "Lane0_location";
BA_ "CompuMethodName" SG_ 956 ITLRSysSts "TLRSysSts";
BA_ "ISignalName" SG_ 956 ITLRSysSts "ITLRSysSts";
BA_ "LongName" SG_ 956 ITLRSysSts "Traffic_lights_recognition_System_Status";
BA_ "SysSignalName" SG_ 956 ITLRSysSts "TLRSysSts";
BA_ "CompuMethodName" SG_ 956 ILane1_location "Lane1_location";
BA_ "ISignalName" SG_ 956 ILane1_location "ILane1_location";
BA_ "LongName" SG_ 956 ILane1_location "Lane_1_Position";
BA_ "SysSignalName" SG_ 956 ILane1_location "Lane1_location";
BA_ "CompuMethodName" SG_ 956 ITrgtSpdSrcSts_IPD "TrgtSpdSrcSts_IPD";
BA_ "ISignalName" SG_ 956 ITrgtSpdSrcSts_IPD "ITrgtSpdSrcSts_IPD";
BA_ "LongName" SG_ 956 ITrgtSpdSrcSts_IPD "Target Speed Source Status";
BA_ "SysSignalName" SG_ 956 ITrgtSpdSrcSts_IPD "TrgtSpdSrcSts_IPD";
BA_ "CompuMethodName" SG_ 956 ISLIFWrnngMdResp "SLIFWrnngMdResp";
BA_ "ISignalName" SG_ 956 ISLIFWrnngMdResp "ISLIFWrnngMdResp";
BA_ "LongName" SG_ 956 ISLIFWrnngMdResp "Speed Limit Information Function Warning Mode Response";
BA_ "SysSignalName" SG_ 956 ISLIFWrnngMdResp "SLIFWrnngMdResp";
BA_ "CompuMethodName" SG_ 956 ITLRWarning "TLRWarning";
BA_ "ISignalName" SG_ 956 ITLRWarning "ITLRWarning";
BA_ "LongName" SG_ 956 ITLRWarning "Traffic_lights_recognition_Warning";
BA_ "SysSignalName" SG_ 956 ITLRWarning "TLRWarning";
BA_ "CompuMethodName" SG_ 956 ITLRMdSwDspCmd "TLRMdSwDspCmd";
BA_ "ISignalName" SG_ 956 ITLRMdSwDspCmd "ITLRMdSwDspCmd";
BA_ "LongName" SG_ 956 ITLRMdSwDspCmd "Traffic_lights_recognition_Mode_Switch_Display_Command";
BA_ "SysSignalName" SG_ 956 ITLRMdSwDspCmd "TLRMdSwDspCmd";
BA_ "CompuMethodName" SG_ 956 ISpdLmtOfstSetResp "SpdLmtOfstSetResp";
BA_ "GenSigStartValue" SG_ 956 ISpdLmtOfstSetResp 20;
BA_ "ISignalName" SG_ 956 ISpdLmtOfstSetResp "ISpdLmtOfstSetResp";
BA_ "LongName" SG_ 956 ISpdLmtOfstSetResp "Speed Limit Offset Set Response";
BA_ "SysSignalName" SG_ 956 ISpdLmtOfstSetResp "SpdLmtOfstSetResp";
BA_ "CompuMethodName" SG_ 956 ISLIFAudWrnng_IPD "SLIFAudWrnng_IPD";
BA_ "ISignalName" SG_ 956 ISLIFAudWrnng_IPD "ISLIFAudWrnng_IPD";
BA_ "LongName" SG_ 956 ISLIFAudWrnng_IPD "Speed Limit Information Function Audible Warning";
BA_ "SysSignalName" SG_ 956 ISLIFAudWrnng_IPD "SLIFAudWrnng_IPD";
BA_ "CompuMethodName" SG_ 956 ISLIFUpdtIndResp_IPD "SLIFUpdtIndResp_IPD";
BA_ "ISignalName" SG_ 956 ISLIFUpdtIndResp_IPD "ISLIFUpdtIndResp_IPD";
BA_ "LongName" SG_ 956 ISLIFUpdtIndResp_IPD "Speed Limit Information Function Update Indication Response";
BA_ "SysSignalName" SG_ 956 ISLIFUpdtIndResp_IPD "SLIFUpdtIndResp_IPD";
BA_ "CompuMethodName" SG_ 956 ISLIFUpdtInd_IPD "SLIFUpdtInd_IPD";
BA_ "ISignalName" SG_ 956 ISLIFUpdtInd_IPD "ISLIFUpdtInd_IPD";
BA_ "LongName" SG_ 956 ISLIFUpdtInd_IPD "Speed Limit Information Function Update Indication";
BA_ "SysSignalName" SG_ 956 ISLIFUpdtInd_IPD "SLIFUpdtInd_IPD";
BA_ "CompuMethodName" SG_ 956 ICCSpdVcCmdCnfm "CCSpdVcCmdCnfm";
BA_ "ISignalName" SG_ 956 ICCSpdVcCmdCnfm "ICCSpdVcCmdCnfm";
BA_ "LongName" SG_ 956 ICCSpdVcCmdCnfm "Cruise_Control_Speed_Voice_Command_Confirm";
BA_ "SysSignalName" SG_ 956 ICCSpdVcCmdCnfm "CCSpdVcCmdCnfm";
BA_ "CompuMethodName" SG_ 163 IFVCM_10ms_Group01_CRC "FVCM_10ms_Group01_CRC";
BA_ "ISignalName" SG_ 163 IFVCM_10ms_Group01_CRC "IFVCM_10ms_Group01_CRC";
BA_ "SysSignalName" SG_ 163 IFVCM_10ms_Group01_CRC "FVCM_10ms_Group01_CRC";
BA_ "CompuMethodName" SG_ 163 IFVCM_10ms_Group01_RC "FVCM_10ms_Group01_RC";
BA_ "ISignalName" SG_ 163 IFVCM_10ms_Group01_RC "IFVCM_10ms_Group01_RC";
BA_ "SysSignalName" SG_ 163 IFVCM_10ms_Group01_RC "FVCM_10ms_Group01_RC";
BA_ "CompuMethodName" SG_ 163 ILKAReqToqSts "LKAReqToqSts";
BA_ "ISignalName" SG_ 163 ILKAReqToqSts "ILKAReqToqSts";
BA_ "LongName" SG_ 163 ILKAReqToqSts "Lane_Keeping_Assist_Required_Torque_Status";
BA_ "SysSignalName" SG_ 163 ILKAReqToqSts "LKAReqToqSts";
BA_ "CompuMethodName" SG_ 163 ILKAReqAngSts "LKAReqAngSts";
BA_ "ISignalName" SG_ 163 ILKAReqAngSts "ILKAReqAngSts";
BA_ "LongName" SG_ 163 ILKAReqAngSts "Lane_Keeping_Assist_Required_Angle_Status";
BA_ "SysSignalName" SG_ 163 ILKAReqAngSts "LKAReqAngSts";
BA_ "CompuMethodName" SG_ 163 ILKAReqAng "LKAReqAng";
BA_ "GenSigStartValue" SG_ 163 ILKAReqAng 32600;
BA_ "ISignalName" SG_ 163 ILKAReqAng "ILKAReqAng";
BA_ "LongName" SG_ 163 ILKAReqAng "Lane_Keeping_Assist_Required_Angle";
BA_ "SysSignalName" SG_ 163 ILKAReqAng "LKAReqAng";
BA_ "CompuMethodName" SG_ 163 ILKAReqToq "LKAReqToq";
BA_ "GenSigStartValue" SG_ 163 ILKAReqToq 1024;
BA_ "ISignalName" SG_ 163 ILKAReqToq "ILKAReqToq";
BA_ "LongName" SG_ 163 ILKAReqToq "Lane_Keeping_Assist_Required_Torque";
BA_ "SysSignalName" SG_ 163 ILKAReqToq "LKAReqToq";
BA_ "CompuMethodName" SG_ 163 IFVCM_10ms_Group01_Reserved1 "FVCM_10ms_Group01_Reserved1";
BA_ "GenSigStartValue" SG_ 163 IFVCM_10ms_Group01_Reserved1 31;
BA_ "ISignalName" SG_ 163 IFVCM_10ms_Group01_Reserved1 "IFVCM_10ms_Group01_Reserved1";
BA_ "SysSignalName" SG_ 163 IFVCM_10ms_Group01_Reserved1 "FVCM_10ms_Group01_Reserved1";
BA_ "CompuMethodName" SG_ 163 IFVCM_10ms_Group01_Reserved2 "FVCM_10ms_Group01_Reserved2";
BA_ "GenSigStartValue" SG_ 163 IFVCM_10ms_Group01_Reserved2 255;
BA_ "ISignalName" SG_ 163 IFVCM_10ms_Group01_Reserved2 "IFVCM_10ms_Group01_Reserved2";
BA_ "SysSignalName" SG_ 163 IFVCM_10ms_Group01_Reserved2 "FVCM_10ms_Group01_Reserved2";
BA_ "CompuMethodName" SG_ 163 IFVCM_10ms_Group01_Reserved3 "FVCM_10ms_Group01_Reserved3";
BA_ "GenSigStartValue" SG_ 163 IFVCM_10ms_Group01_Reserved3 255;
BA_ "ISignalName" SG_ 163 IFVCM_10ms_Group01_Reserved3 "IFVCM_10ms_Group01_Reserved3";
BA_ "SysSignalName" SG_ 163 IFVCM_10ms_Group01_Reserved3 "FVCM_10ms_Group01_Reserved3";
BA_ "CompuMethodName" SG_ 163 IFVCM_10ms_Group01_Reserved4 "FVCM_10ms_Group01_Reserved4";
BA_ "GenSigStartValue" SG_ 163 IFVCM_10ms_Group01_Reserved4 255;
BA_ "ISignalName" SG_ 163 IFVCM_10ms_Group01_Reserved4 "IFVCM_10ms_Group01_Reserved4";
BA_ "SysSignalName" SG_ 163 IFVCM_10ms_Group01_Reserved4 "FVCM_10ms_Group01_Reserved4";
BA_ "CompuMethodName" SG_ 163 IFVCM_10ms_Group01_Reserved5 "FVCM_10ms_Group01_Reserved5";
BA_ "GenSigStartValue" SG_ 163 IFVCM_10ms_Group01_Reserved5 255;
BA_ "ISignalName" SG_ 163 IFVCM_10ms_Group01_Reserved5 "IFVCM_10ms_Group01_Reserved5";
BA_ "SysSignalName" SG_ 163 IFVCM_10ms_Group01_Reserved5 "FVCM_10ms_Group01_Reserved5";
BA_ "CompuMethodName" SG_ 163 IFVCM_10ms_Group01_Reserved6 "FVCM_10ms_Group01_Reserved6";
BA_ "GenSigStartValue" SG_ 163 IFVCM_10ms_Group01_Reserved6 255;
BA_ "ISignalName" SG_ 163 IFVCM_10ms_Group01_Reserved6 "IFVCM_10ms_Group01_Reserved6";
BA_ "SysSignalName" SG_ 163 IFVCM_10ms_Group01_Reserved6 "FVCM_10ms_Group01_Reserved6";
BA_ "CompuMethodName" SG_ 163 IFVCM_10ms_Group01_Reserved7 "FVCM_10ms_Group01_Reserved7";
BA_ "GenSigStartValue" SG_ 163 IFVCM_10ms_Group01_Reserved7 255;
BA_ "ISignalName" SG_ 163 IFVCM_10ms_Group01_Reserved7 "IFVCM_10ms_Group01_Reserved7";
BA_ "SysSignalName" SG_ 163 IFVCM_10ms_Group01_Reserved7 "FVCM_10ms_Group01_Reserved7";
BA_ "CompuMethodName" SG_ 318 ILDrvnWhlRotlDistPlsCtr "LDrvnWhlRotlDistPlsCtr";
BA_ "ISignalName" SG_ 318 ILDrvnWhlRotlDistPlsCtr "ILDrvnWhlRotlDistPlsCtr";
BA_ "LongName" SG_ 318 ILDrvnWhlRotlDistPlsCtr "Left Driven Wheel Rotational Distance Pulse Counter";
BA_ "SysSignalName" SG_ 318 ILDrvnWhlRotlDistPlsCtr "LDrvnWhlRotlDistPlsCtr";
BA_ "CompuMethodName" SG_ 318 ILDrvnWhlRotlSeqNum "LDrvnWhlRotlSeqNum";
BA_ "ISignalName" SG_ 318 ILDrvnWhlRotlSeqNum "ILDrvnWhlRotlSeqNum";
BA_ "LongName" SG_ 318 ILDrvnWhlRotlSeqNum "Left Driven Wheel Rotational Sequence Number";
BA_ "SysSignalName" SG_ 318 ILDrvnWhlRotlSeqNum "LDrvnWhlRotlSeqNum";
BA_ "CompuMethodName" SG_ 318 ILDrvnWhlRotlRstOcd "LDrvnWhlRotlRstOcd";
BA_ "ISignalName" SG_ 318 ILDrvnWhlRotlRstOcd "ILDrvnWhlRotlRstOcd";
BA_ "LongName" SG_ 318 ILDrvnWhlRotlRstOcd "Left Driven Wheel Rotational Reset Occurred";
BA_ "SysSignalName" SG_ 318 ILDrvnWhlRotlRstOcd "LDrvnWhlRotlRstOcd";
BA_ "CompuMethodName" SG_ 318 ILDrvnWhlRotlDistV "LDrvnWhlRotlDistV";
BA_ "ISignalName" SG_ 318 ILDrvnWhlRotlDistV "ILDrvnWhlRotlDistV";
BA_ "LongName" SG_ 318 ILDrvnWhlRotlDistV "Left Driven Wheel Rotational Distance Validity";
BA_ "SysSignalName" SG_ 318 ILDrvnWhlRotlDistV "LDrvnWhlRotlDistV";
BA_ "CompuMethodName" SG_ 318 ILDrvnWhlRotlDistTRC "LDrvnWhlRotlDistTRC";
BA_ "ISignalName" SG_ 318 ILDrvnWhlRotlDistTRC "ILDrvnWhlRotlDistTRC";
BA_ "LongName" SG_ 318 ILDrvnWhlRotlDistTRC "Left Driven Wheel Rotational Distance Timestamp Rollover Counter";
BA_ "SysSignalName" SG_ 318 ILDrvnWhlRotlDistTRC "LDrvnWhlRotlDistTRC";
BA_ "CompuMethodName" SG_ 318 ILDrvnWhlRotlDistTmsp "LDrvnWhlRotlDistTmsp";
BA_ "ISignalName" SG_ 318 ILDrvnWhlRotlDistTmsp "ILDrvnWhlRotlDistTmsp";
BA_ "LongName" SG_ 318 ILDrvnWhlRotlDistTmsp "Left Driven Wheel Rotational Distance Timestamp";
BA_ "SysSignalName" SG_ 318 ILDrvnWhlRotlDistTmsp "LDrvnWhlRotlDistTmsp";
BA_ "CompuMethodName" SG_ 318 IRDrvnWhlRotlDistPlsCtr "RDrvnWhlRotlDistPlsCtr";
BA_ "ISignalName" SG_ 318 IRDrvnWhlRotlDistPlsCtr "IRDrvnWhlRotlDistPlsCtr";
BA_ "LongName" SG_ 318 IRDrvnWhlRotlDistPlsCtr "Right Driven Wheel Rotational Distance Pulse Counter";
BA_ "SysSignalName" SG_ 318 IRDrvnWhlRotlDistPlsCtr "RDrvnWhlRotlDistPlsCtr";
BA_ "CompuMethodName" SG_ 318 IRDrvnWhlRotlSeqNum "RDrvnWhlRotlSeqNum";
BA_ "ISignalName" SG_ 318 IRDrvnWhlRotlSeqNum "IRDrvnWhlRotlSeqNum";
BA_ "LongName" SG_ 318 IRDrvnWhlRotlSeqNum "Right Driven Wheel Rotational Sequence Number";
BA_ "SysSignalName" SG_ 318 IRDrvnWhlRotlSeqNum "RDrvnWhlRotlSeqNum";
BA_ "CompuMethodName" SG_ 318 IRDrvnWhlRotlRstOcd "RDrvnWhlRotlRstOcd";
BA_ "ISignalName" SG_ 318 IRDrvnWhlRotlRstOcd "IRDrvnWhlRotlRstOcd";
BA_ "LongName" SG_ 318 IRDrvnWhlRotlRstOcd "Right Driven Wheel Rotational Reset Occurred";
BA_ "SysSignalName" SG_ 318 IRDrvnWhlRotlRstOcd "RDrvnWhlRotlRstOcd";
BA_ "CompuMethodName" SG_ 318 IRDrvnWhlRotlDistV "RDrvnWhlRotlDistV";
BA_ "ISignalName" SG_ 318 IRDrvnWhlRotlDistV "IRDrvnWhlRotlDistV";
BA_ "LongName" SG_ 318 IRDrvnWhlRotlDistV "Right Driven Wheel Rotational Distance Validity";
BA_ "SysSignalName" SG_ 318 IRDrvnWhlRotlDistV "RDrvnWhlRotlDistV";
BA_ "CompuMethodName" SG_ 318 IRDrvnWhlRotlDistTRC "RDrvnWhlRotlDistTRC";
BA_ "ISignalName" SG_ 318 IRDrvnWhlRotlDistTRC "IRDrvnWhlRotlDistTRC";
BA_ "LongName" SG_ 318 IRDrvnWhlRotlDistTRC "Right Driven Wheel Rotational Distance Timestamp Rollover Counter";
BA_ "SysSignalName" SG_ 318 IRDrvnWhlRotlDistTRC "RDrvnWhlRotlDistTRC";
BA_ "CompuMethodName" SG_ 318 IRDrvnWhlRotlDistTmsp "RDrvnWhlRotlDistTmsp";
BA_ "ISignalName" SG_ 318 IRDrvnWhlRotlDistTmsp "IRDrvnWhlRotlDistTmsp";
BA_ "LongName" SG_ 318 IRDrvnWhlRotlDistTmsp "Right Driven Wheel Rotational Distance Timestamp";
BA_ "SysSignalName" SG_ 318 IRDrvnWhlRotlDistTmsp "RDrvnWhlRotlDistTmsp";
BA_ "CompuMethodName" SG_ 319 ILNonDrvnWhlRotlDistPC "LNonDrvnWhlRotlDistPC";
BA_ "ISignalName" SG_ 319 ILNonDrvnWhlRotlDistPC "ILNonDrvnWhlRotlDistPC";
BA_ "LongName" SG_ 319 ILNonDrvnWhlRotlDistPC "Left Non Driven Wheel Rotational Distance Pulse Counter";
BA_ "SysSignalName" SG_ 319 ILNonDrvnWhlRotlDistPC "LNonDrvnWhlRotlDistPC";
BA_ "CompuMethodName" SG_ 319 ILNonDrvnWhlRotlSeqNum "LNonDrvnWhlRotlSeqNum";
BA_ "ISignalName" SG_ 319 ILNonDrvnWhlRotlSeqNum "ILNonDrvnWhlRotlSeqNum";
BA_ "LongName" SG_ 319 ILNonDrvnWhlRotlSeqNum "Left Non Driven Wheel Rotational Sequence Number";
BA_ "SysSignalName" SG_ 319 ILNonDrvnWhlRotlSeqNum "LNonDrvnWhlRotlSeqNum";
BA_ "CompuMethodName" SG_ 319 ILNonDrvnWhlRotlRstOcd "LNonDrvnWhlRotlRstOcd";
BA_ "ISignalName" SG_ 319 ILNonDrvnWhlRotlRstOcd "ILNonDrvnWhlRotlRstOcd";
BA_ "LongName" SG_ 319 ILNonDrvnWhlRotlRstOcd "Left Non Driven Wheel Rotational Reset Occurred";
BA_ "SysSignalName" SG_ 319 ILNonDrvnWhlRotlRstOcd "LNonDrvnWhlRotlRstOcd";
BA_ "CompuMethodName" SG_ 319 ILNonDrvnWhlRotlDistV "LNonDrvnWhlRotlDistV";
BA_ "ISignalName" SG_ 319 ILNonDrvnWhlRotlDistV "ILNonDrvnWhlRotlDistV";
BA_ "LongName" SG_ 319 ILNonDrvnWhlRotlDistV "Left Non Driven Wheel Rotational Distance Validity";
BA_ "SysSignalName" SG_ 319 ILNonDrvnWhlRotlDistV "LNonDrvnWhlRotlDistV";
BA_ "CompuMethodName" SG_ 319 ILNonDrvnWhlRotlDistTRC "LNonDrvnWhlRotlDistTRC";
BA_ "ISignalName" SG_ 319 ILNonDrvnWhlRotlDistTRC "ILNonDrvnWhlRotlDistTRC";
BA_ "LongName" SG_ 319 ILNonDrvnWhlRotlDistTRC "Left Non Driven Wheel Rotational Distance Timestamp Rollover Counter";
BA_ "SysSignalName" SG_ 319 ILNonDrvnWhlRotlDistTRC "LNonDrvnWhlRotlDistTRC";
BA_ "CompuMethodName" SG_ 319 ILNonDrvnWhlRotlDistT "LNonDrvnWhlRotlDistT";
BA_ "ISignalName" SG_ 319 ILNonDrvnWhlRotlDistT "ILNonDrvnWhlRotlDistT";
BA_ "LongName" SG_ 319 ILNonDrvnWhlRotlDistT "Left Non Driven Wheel Rotational Distance Timestamp";
BA_ "SysSignalName" SG_ 319 ILNonDrvnWhlRotlDistT "LNonDrvnWhlRotlDistT";
BA_ "CompuMethodName" SG_ 319 IRNonDrvnWhlRotlDistPC "RNonDrvnWhlRotlDistPC";
BA_ "ISignalName" SG_ 319 IRNonDrvnWhlRotlDistPC "IRNonDrvnWhlRotlDistPC";
BA_ "LongName" SG_ 319 IRNonDrvnWhlRotlDistPC "Right Non Driven Wheel Rotational Distance Pulse Counter";
BA_ "SysSignalName" SG_ 319 IRNonDrvnWhlRotlDistPC "RNonDrvnWhlRotlDistPC";
BA_ "CompuMethodName" SG_ 319 IRNonDrvnWhlRotlSeqNum "RNonDrvnWhlRotlSeqNum";
BA_ "ISignalName" SG_ 319 IRNonDrvnWhlRotlSeqNum "IRNonDrvnWhlRotlSeqNum";
BA_ "LongName" SG_ 319 IRNonDrvnWhlRotlSeqNum "Right Non Driven Wheel Rotational Sequence Number";
BA_ "SysSignalName" SG_ 319 IRNonDrvnWhlRotlSeqNum "RNonDrvnWhlRotlSeqNum";
BA_ "CompuMethodName" SG_ 319 IRNonDrvnWhlRotlRstOcd "RNonDrvnWhlRotlRstOcd";
BA_ "ISignalName" SG_ 319 IRNonDrvnWhlRotlRstOcd "IRNonDrvnWhlRotlRstOcd";
BA_ "LongName" SG_ 319 IRNonDrvnWhlRotlRstOcd "Right Non Driven Wheel Rotational Reset Occurred";
BA_ "SysSignalName" SG_ 319 IRNonDrvnWhlRotlRstOcd "RNonDrvnWhlRotlRstOcd";
BA_ "CompuMethodName" SG_ 319 IRNonDrvnWhlRotlDistV "RNonDrvnWhlRotlDistV";
BA_ "ISignalName" SG_ 319 IRNonDrvnWhlRotlDistV "IRNonDrvnWhlRotlDistV";
BA_ "LongName" SG_ 319 IRNonDrvnWhlRotlDistV "Right Non Driven Wheel Rotational Distance Validity";
BA_ "SysSignalName" SG_ 319 IRNonDrvnWhlRotlDistV "RNonDrvnWhlRotlDistV";
BA_ "CompuMethodName" SG_ 319 IRNonDrvnWhlRotlDistTRC "RNonDrvnWhlRotlDistTRC";
BA_ "ISignalName" SG_ 319 IRNonDrvnWhlRotlDistTRC "IRNonDrvnWhlRotlDistTRC";
BA_ "LongName" SG_ 319 IRNonDrvnWhlRotlDistTRC "Right Non Driven Wheel Rotational Distance Timestamp Rollover Counter";
BA_ "SysSignalName" SG_ 319 IRNonDrvnWhlRotlDistTRC "RNonDrvnWhlRotlDistTRC";
BA_ "CompuMethodName" SG_ 319 IRNonDrvnWhlRotlDistT "RNonDrvnWhlRotlDistT";
BA_ "ISignalName" SG_ 319 IRNonDrvnWhlRotlDistT "IRNonDrvnWhlRotlDistT";
BA_ "LongName" SG_ 319 IRNonDrvnWhlRotlDistT "Right Non Driven Wheel Rotational Distance Timestamp";
BA_ "SysSignalName" SG_ 319 IRNonDrvnWhlRotlDistT "RNonDrvnWhlRotlDistT";
BA_ "CompuMethodName" SG_ 423 IIBS_20ms_Group07_CRC "IBS_20ms_Group07_CRC";
BA_ "ISignalName" SG_ 423 IIBS_20ms_Group07_CRC "IIBS_20ms_Group07_CRC";
BA_ "LongName" SG_ 423 IIBS_20ms_Group07_CRC "IBS_20ms_Group07 Checksum";
BA_ "SysSignalName" SG_ 423 IIBS_20ms_Group07_CRC "IBS_20ms_Group07_CRC";
BA_ "CompuMethodName" SG_ 423 IIBS_20ms_Group07_RC "IBS_20ms_Group07_RC";
BA_ "ISignalName" SG_ 423 IIBS_20ms_Group07_RC "IIBS_20ms_Group07_RC";
BA_ "LongName" SG_ 423 IIBS_20ms_Group07_RC "IBS_20ms_Group07 Alive Rolling Counter";
BA_ "SysSignalName" SG_ 423 IIBS_20ms_Group07_RC "IBS_20ms_Group07_RC";
BA_ "CompuMethodName" SG_ 423 IHDCSysSts "HDCSysSts";
BA_ "ISignalName" SG_ 423 IHDCSysSts "IHDCSysSts";
BA_ "LongName" SG_ 423 IHDCSysSts "Hill Descent Control System Status";
BA_ "SysSignalName" SG_ 423 IHDCSysSts "HDCSysSts";
BA_ "CompuMethodName" SG_ 423 IABSIO "ABSIO";
BA_ "ISignalName" SG_ 423 IABSIO "IABSIO";
BA_ "LongName" SG_ 423 IABSIO "Antilock Brake System Indication On";
BA_ "SysSignalName" SG_ 423 IABSIO "ABSIO";
BA_ "CompuMethodName" SG_ 423 IVSESysA "VSESysA";
BA_ "ISignalName" SG_ 423 IVSESysA "IVSESysA";
BA_ "LongName" SG_ 423 IVSESysA "Vehicle Stability Enhancement System Active";
BA_ "SysSignalName" SG_ 423 IVSESysA "VSESysA";
BA_ "CompuMethodName" SG_ 423 IBrkSysYlwBrkTlltReq "BrkSysYlwBrkTlltReq";
BA_ "ISignalName" SG_ 423 IBrkSysYlwBrkTlltReq "IBrkSysYlwBrkTlltReq";
BA_ "LongName" SG_ 423 IBrkSysYlwBrkTlltReq "Brake System Yellow Brake Telltale Request";
BA_ "SysSignalName" SG_ 423 IBrkSysYlwBrkTlltReq "BrkSysYlwBrkTlltReq";
BA_ "CompuMethodName" SG_ 423 IVSESts "VSESts";
BA_ "ISignalName" SG_ 423 IVSESts "IVSESts";
BA_ "LongName" SG_ 423 IVSESts "Vehicle Stability Enhancement Status";
BA_ "SysSignalName" SG_ 423 IVSESts "VSESts";
BA_ "CompuMethodName" SG_ 423 IVSEMd "VSEMd";
BA_ "ISignalName" SG_ 423 IVSEMd "IVSEMd";
BA_ "LongName" SG_ 423 IVSEMd "Vehicle Stability Enhancement Mode";
BA_ "SysSignalName" SG_ 423 IVSEMd "VSEMd";
BA_ "CompuMethodName" SG_ 423 IMultColBrkEnbA "MultColBrkEnbA";
BA_ "ISignalName" SG_ 423 IMultColBrkEnbA "IMultColBrkEnbA";
BA_ "LongName" SG_ 423 IMultColBrkEnbA "Multiturn Collision Brake Enable Active";
BA_ "SysSignalName" SG_ 423 IMultColBrkEnbA "MultColBrkEnbA";
BA_ "CompuMethodName" SG_ 423 IEBDFaultSt "EBDFaultSt";
BA_ "ISignalName" SG_ 423 IEBDFaultSt "IEBDFaultSt";
BA_ "LongName" SG_ 423 IEBDFaultSt "Electronic Brake Distribution Fault Status";
BA_ "SysSignalName" SG_ 423 IEBDFaultSt "EBDFaultSt";
BA_ "CompuMethodName" SG_ 423 ITCSOpngSts "TCSOpngSts";
BA_ "ISignalName" SG_ 423 ITCSOpngSts "ITCSOpngSts";
BA_ "LongName" SG_ 423 ITCSOpngSts "Traction Control System Operating Status";
BA_ "SysSignalName" SG_ 423 ITCSOpngSts "TCSOpngSts";
BA_ "CompuMethodName" SG_ 423 ITCSOpngMd "TCSOpngMd";
BA_ "ISignalName" SG_ 423 ITCSOpngMd "ITCSOpngMd";
BA_ "LongName" SG_ 423 ITCSOpngMd "Traction Control System Operating Mode";
BA_ "SysSignalName" SG_ 423 ITCSOpngMd "TCSOpngMd";
BA_ "CompuMethodName" SG_ 423 IBrkSysHillStAstAvlbl "BrkSysHillStAstAvlbl";
BA_ "ISignalName" SG_ 423 IBrkSysHillStAstAvlbl "IBrkSysHillStAstAvlbl";
BA_ "LongName" SG_ 423 IBrkSysHillStAstAvlbl "Brake System Hill Start Assist Available";
BA_ "SysSignalName" SG_ 423 IBrkSysHillStAstAvlbl "BrkSysHillStAstAvlbl";
BA_ "CompuMethodName" SG_ 423 IRgtvBrkFnFltSts "RgtvBrkFnFltSts";
BA_ "ISignalName" SG_ 423 IRgtvBrkFnFltSts "IRgtvBrkFnFltSts";
BA_ "LongName" SG_ 423 IRgtvBrkFnFltSts "Regenerative Brake Function Fault Status";
BA_ "SysSignalName" SG_ 423 IRgtvBrkFnFltSts "RgtvBrkFnFltSts";
BA_ "CompuMethodName" SG_ 423 IMSRF "MSRF";
BA_ "ISignalName" SG_ 423 IMSRF "IMSRF";
BA_ "LongName" SG_ 423 IMSRF "Motor Slide Retainer Fault";
BA_ "SysSignalName" SG_ 423 IMSRF "MSRF";
BA_ "CompuMethodName" SG_ 423 IAutoHoldSysSts "AutoHoldSysSts";
BA_ "ISignalName" SG_ 423 IAutoHoldSysSts "IAutoHoldSysSts";
BA_ "LongName" SG_ 423 IAutoHoldSysSts "Auto Hold System Status";
BA_ "SysSignalName" SG_ 423 IAutoHoldSysSts "AutoHoldSysSts";
BA_ "CompuMethodName" SG_ 423 IAutoHoldMsg "AutoHoldMsg";
BA_ "ISignalName" SG_ 423 IAutoHoldMsg "IAutoHoldMsg";
BA_ "LongName" SG_ 423 IAutoHoldMsg "Auto Hold Message";
BA_ "SysSignalName" SG_ 423 IAutoHoldMsg "AutoHoldMsg";
BA_ "CompuMethodName" SG_ 423 IEBDA "EBDA";
BA_ "GenSigStartValue" SG_ 423 IEBDA 1;
BA_ "ISignalName" SG_ 423 IEBDA "IEBDA";
BA_ "LongName" SG_ 423 IEBDA "Electronic Brake Distribution Active";
BA_ "SysSignalName" SG_ 423 IEBDA "EBDA";
BA_ "CompuMethodName" SG_ 423 IRgtvBrkFnSts "RgtvBrkFnSts";
BA_ "ISignalName" SG_ 423 IRgtvBrkFnSts "IRgtvBrkFnSts";
BA_ "LongName" SG_ 423 IRgtvBrkFnSts "Regenerative Brake Function Status";
BA_ "SysSignalName" SG_ 423 IRgtvBrkFnSts "RgtvBrkFnSts";
BA_ "CompuMethodName" SG_ 423 ITCSEnbd "TCSEnbd";
BA_ "ISignalName" SG_ 423 ITCSEnbd "ITCSEnbd";
BA_ "LongName" SG_ 423 ITCSEnbd "Traction Control System Enabled";
BA_ "SysSignalName" SG_ 423 ITCSEnbd "TCSEnbd";
BA_ "CompuMethodName" SG_ 423 IHBAActiveSt "HBAActiveSt";
BA_ "ISignalName" SG_ 423 IHBAActiveSt "IHBAActiveSt";
BA_ "LongName" SG_ 423 IHBAActiveSt "Hydraulic Brake Assist Active Status";
BA_ "SysSignalName" SG_ 423 IHBAActiveSt "HBAActiveSt";
BA_ "CompuMethodName" SG_ 423 ITCSA "TCSA";
BA_ "ISignalName" SG_ 423 ITCSA "ITCSA";
BA_ "LongName" SG_ 423 ITCSA "Traction Control System Active";
BA_ "SysSignalName" SG_ 423 ITCSA "TCSA";
BA_ "CompuMethodName" SG_ 423 IEnDragToqRducnA "EnDragToqRducnA";
BA_ "ISignalName" SG_ 423 IEnDragToqRducnA "IEnDragToqRducnA";
BA_ "LongName" SG_ 423 IEnDragToqRducnA "Engine Drag Torque Reduction Active";
BA_ "SysSignalName" SG_ 423 IEnDragToqRducnA "EnDragToqRducnA";
BA_ "CompuMethodName" SG_ 423 IABSF "ABSF";
BA_ "ISignalName" SG_ 423 IABSF "IABSF";
BA_ "LongName" SG_ 423 IABSF "Antilock Brake System Fault";
BA_ "SysSignalName" SG_ 423 IABSF "ABSF";
BA_ "CompuMethodName" SG_ 423 IABSA "ABSA";
BA_ "ISignalName" SG_ 423 IABSA "IABSA";
BA_ "LongName" SG_ 423 IABSA "Antilock Brake System Active";
BA_ "SysSignalName" SG_ 423 IABSA "ABSA";
BA_ "CompuMethodName" SG_ 423 IHBAValidSt "HBAValidSt";
BA_ "ISignalName" SG_ 423 IHBAValidSt "IHBAValidSt";
BA_ "LongName" SG_ 423 IHBAValidSt "Hydraulic Brake Assist Validity Status";
BA_ "SysSignalName" SG_ 423 IHBAValidSt "HBAValidSt";
BA_ "CompuMethodName" SG_ 423 IMSRA "MSRA";
BA_ "GenSigStartValue" SG_ 423 IMSRA 1;
BA_ "ISignalName" SG_ 423 IMSRA "IMSRA";
BA_ "LongName" SG_ 423 IMSRA "Motor Slide Retainer Active";
BA_ "SysSignalName" SG_ 423 IMSRA "MSRA";
BA_ "CompuMethodName" SG_ 423 IEmgcBrkAV "EmgcBrkAV";
BA_ "ISignalName" SG_ 423 IEmgcBrkAV "IEmgcBrkAV";
BA_ "LongName" SG_ 423 IEmgcBrkAV "Emergency Brake Active Validity";
BA_ "SysSignalName" SG_ 423 IEmgcBrkAV "EmgcBrkAV";
BA_ "CompuMethodName" SG_ 423 IEmgcBrkA "EmgcBrkA";
BA_ "ISignalName" SG_ 423 IEmgcBrkA "IEmgcBrkA";
BA_ "LongName" SG_ 423 IEmgcBrkA "Emergency Brake Active";
BA_ "SysSignalName" SG_ 423 IEmgcBrkA "EmgcBrkA";
BA_ "CompuMethodName" SG_ 423 IBrkSysRedBrkTlltReq "BrkSysRedBrkTlltReq";
BA_ "ISignalName" SG_ 423 IBrkSysRedBrkTlltReq "IBrkSysRedBrkTlltReq";
BA_ "LongName" SG_ 423 IBrkSysRedBrkTlltReq "Brake System Red Brake Telltale Request";
BA_ "SysSignalName" SG_ 423 IBrkSysRedBrkTlltReq "BrkSysRedBrkTlltReq";
BA_ "CompuMethodName" SG_ 423 IBrkSysHillStAstSts "BrkSysHillStAstSts";
BA_ "ISignalName" SG_ 423 IBrkSysHillStAstSts "IBrkSysHillStAstSts";
BA_ "LongName" SG_ 423 IBrkSysHillStAstSts "Brake System Hill Start Assist Status";
BA_ "SysSignalName" SG_ 423 IBrkSysHillStAstSts "BrkSysHillStAstSts";
BA_ "CompuMethodName" SG_ 423 IAVHSigPdlSts "AVHSigPdlSts";
BA_ "ISignalName" SG_ 423 IAVHSigPdlSts "IAVHSigPdlSts";
BA_ "LongName" SG_ 423 IAVHSigPdlSts "AVH Signal Pedal Status";
BA_ "SysSignalName" SG_ 423 IAVHSigPdlSts "AVHSigPdlSts";
BA_ "CompuMethodName" SG_ 423 IAutoHoldMdSts "AutoHoldMdSts";
BA_ "ISignalName" SG_ 423 IAutoHoldMdSts "IAutoHoldMdSts";
BA_ "LongName" SG_ 423 IAutoHoldMdSts "Auto Hold Mode Status";
BA_ "SysSignalName" SG_ 423 IAutoHoldMdSts "AutoHoldMdSts";
BA_ "CompuMethodName" SG_ 423 ISoftSpSysSts "SoftSpSysSts";
BA_ "ISignalName" SG_ 423 ISoftSpSysSts "ISoftSpSysSts";
BA_ "LongName" SG_ 423 ISoftSpSysSts "Soft Stop System Status";
BA_ "SysSignalName" SG_ 423 ISoftSpSysSts "SoftSpSysSts";
BA_ "CompuMethodName" SG_ 423 IMulColBrkA "MulColBrkA";
BA_ "ISignalName" SG_ 423 IMulColBrkA "IMulColBrkA";
BA_ "LongName" SG_ 423 IMulColBrkA "Multi Collision Brake Active";
BA_ "SysSignalName" SG_ 423 IMulColBrkA "MulColBrkA";
BA_ "CompuMethodName" SG_ 423 IMulColBrkAvlblySts "MulColBrkAvlblySts";
BA_ "ISignalName" SG_ 423 IMulColBrkAvlblySts "IMulColBrkAvlblySts";
BA_ "LongName" SG_ 423 IMulColBrkAvlblySts "Multi Collision Brake Availability Status";
BA_ "SysSignalName" SG_ 423 IMulColBrkAvlblySts "MulColBrkAvlblySts";
BA_ "CompuMethodName" SG_ 342 IIBS_20ms_Group08_CRC "IBS_20ms_Group08_CRC";
BA_ "ISignalName" SG_ 342 IIBS_20ms_Group08_CRC "IIBS_20ms_Group08_CRC";
BA_ "LongName" SG_ 342 IIBS_20ms_Group08_CRC "Electric Park Brake Application Status Cyclic Redundancy Check";
BA_ "SysSignalName" SG_ 342 IIBS_20ms_Group08_CRC "IBS_20ms_Group08_CRC";
BA_ "CompuMethodName" SG_ 342 IIBS_20ms_Group08_RC "IBS_20ms_Group08_RC";
BA_ "ISignalName" SG_ 342 IIBS_20ms_Group08_RC "IIBS_20ms_Group08_RC";
BA_ "LongName" SG_ 342 IIBS_20ms_Group08_RC "Electric Park Brake Application Status Rolling Count";
BA_ "SysSignalName" SG_ 342 IIBS_20ms_Group08_RC "IBS_20ms_Group08_RC";
BA_ "CompuMethodName" SG_ 342 IEPBSts "EPBSts";
BA_ "ISignalName" SG_ 342 IEPBSts "IEPBSts";
BA_ "LongName" SG_ 342 IEPBSts "Electric Park Brake Status";
BA_ "SysSignalName" SG_ 342 IEPBSts "EPBSts";
BA_ "CompuMethodName" SG_ 342 IEPBAppcnSts "EPBAppcnSts";
BA_ "ISignalName" SG_ 342 IEPBAppcnSts "IEPBAppcnSts";
BA_ "LongName" SG_ 342 IEPBAppcnSts "Electric Park Brake Application Status";
BA_ "SysSignalName" SG_ 342 IEPBAppcnSts "EPBAppcnSts";
BA_ "CompuMethodName" SG_ 342 IEPBCCCanclReqd "EPBCCCanclReqd";
BA_ "ISignalName" SG_ 342 IEPBCCCanclReqd "IEPBCCCanclReqd";
BA_ "LongName" SG_ 342 IEPBCCCanclReqd "Electric Park Brake Cruise Control Cancel Requested";
BA_ "SysSignalName" SG_ 342 IEPBCCCanclReqd "EPBCCCanclReqd";
BA_ "CompuMethodName" SG_ 342 IEPBSysStsIndReq "EPBSysStsIndReq";
BA_ "ISignalName" SG_ 342 IEPBSysStsIndReq "IEPBSysStsIndReq";
BA_ "LongName" SG_ 342 IEPBSysStsIndReq "Electric Park Brake System Status Indication Request";
BA_ "SysSignalName" SG_ 342 IEPBSysStsIndReq "EPBSysStsIndReq";
BA_ "CompuMethodName" SG_ 342 IEPBSwSts "EPBSwSts";
BA_ "ISignalName" SG_ 342 IEPBSwSts "IEPBSwSts";
BA_ "LongName" SG_ 342 IEPBSwSts "Electric Park Brake Switch Status";
BA_ "SysSignalName" SG_ 342 IEPBSwSts "EPBSwSts";
BA_ "CompuMethodName" SG_ 342 IEPBAvlblySts "EPBAvlblySts";
BA_ "ISignalName" SG_ 342 IEPBAvlblySts "IEPBAvlblySts";
BA_ "LongName" SG_ 342 IEPBAvlblySts "Electric Park Brake Availability Status";
BA_ "SysSignalName" SG_ 342 IEPBAvlblySts "EPBAvlblySts";
BA_ "CompuMethodName" SG_ 342 IEPBSysAudWrnngReq "EPBSysAudWrnngReq";
BA_ "ISignalName" SG_ 342 IEPBSysAudWrnngReq "IEPBSysAudWrnngReq";
BA_ "LongName" SG_ 342 IEPBSysAudWrnngReq "Electric Park Brake System Audible Warning Request";
BA_ "SysSignalName" SG_ 342 IEPBSysAudWrnngReq "EPBSysAudWrnngReq";
BA_ "CompuMethodName" SG_ 342 IEPBSwStsV "EPBSwStsV";
BA_ "ISignalName" SG_ 342 IEPBSwStsV "IEPBSwStsV";
BA_ "LongName" SG_ 342 IEPBSwStsV "Electric Park Brake Switch Status Validity";
BA_ "SysSignalName" SG_ 342 IEPBSwStsV "EPBSwStsV";
BA_ "CompuMethodName" SG_ 342 IEPBSysWrnngIndReq "EPBSysWrnngIndReq";
BA_ "ISignalName" SG_ 342 IEPBSysWrnngIndReq "IEPBSysWrnngIndReq";
BA_ "LongName" SG_ 342 IEPBSysWrnngIndReq "Electric Park Brake System Warning Indication Request";
BA_ "SysSignalName" SG_ 342 IEPBSysWrnngIndReq "EPBSysWrnngIndReq";
BA_ "CompuMethodName" SG_ 342 IEPBSysDspMsgReq "EPBSysDspMsgReq";
BA_ "ISignalName" SG_ 342 IEPBSysDspMsgReq "IEPBSysDspMsgReq";
BA_ "LongName" SG_ 342 IEPBSysDspMsgReq "Electric Park Brake System Display Message Request";
BA_ "SysSignalName" SG_ 342 IEPBSysDspMsgReq "EPBSysDspMsgReq";
BA_ "CompuMethodName" SG_ 342 IChSysTrBrkAxleToqVal "ChSysTrBrkAxleToqVal";
BA_ "ISignalName" SG_ 342 IChSysTrBrkAxleToqVal "IChSysTrBrkAxleToqVal";
BA_ "LongName" SG_ 342 IChSysTrBrkAxleToqVal "Chassis System transmission Brake Axle Torque Value";
BA_ "SysSignalName" SG_ 342 IChSysTrBrkAxleToqVal "ChSysTrBrkAxleToqVal";
BA_ "CompuMethodName" SG_ 342 IEPBAPAAvlbl "EPBAPAAvlbl";
BA_ "ISignalName" SG_ 342 IEPBAPAAvlbl "IEPBAPAAvlbl";
BA_ "LongName" SG_ 342 IEPBAPAAvlbl "Electric Park Brake Auto Parking Assist Available";
BA_ "SysSignalName" SG_ 342 IEPBAPAAvlbl "EPBAPAAvlbl";
BA_ "CompuMethodName" SG_ 342 IEPBFlrSts "EPBFlrSts";
BA_ "ISignalName" SG_ 342 IEPBFlrSts "IEPBFlrSts";
BA_ "LongName" SG_ 342 IEPBFlrSts "Electric Park Brake Failure Status";
BA_ "SysSignalName" SG_ 342 IEPBFlrSts "EPBFlrSts";
BA_ "CompuMethodName" SG_ 342 IChSysSecyBrkAxleToqVal "ChSysSecyBrkAxleToqVal";
BA_ "ISignalName" SG_ 342 IChSysSecyBrkAxleToqVal "IChSysSecyBrkAxleToqVal";
BA_ "LongName" SG_ 342 IChSysSecyBrkAxleToqVal "Chassis System Secondly Brake Axle Torque Value";
BA_ "SysSignalName" SG_ 342 IChSysSecyBrkAxleToqVal "ChSysSecyBrkAxleToqVal";
BA_ "CompuMethodName" SG_ 342 IChSysSecyBrkAxleToqValV "ChSysSecyBrkAxleToqValV";
BA_ "ISignalName" SG_ 342 IChSysSecyBrkAxleToqValV "IChSysSecyBrkAxleToqValV";
BA_ "LongName" SG_ 342 IChSysSecyBrkAxleToqValV "Chassis System Secondly Brake Axle Torque Value Valid";
BA_ "SysSignalName" SG_ 342 IChSysSecyBrkAxleToqValV "ChSysSecyBrkAxleToqValV";
BA_ "CompuMethodName" SG_ 342 IChSysTrBrkAxleToqValV "ChSysTrBrkAxleToqValV";
BA_ "ISignalName" SG_ 342 IChSysTrBrkAxleToqValV "IChSysTrBrkAxleToqValV";
BA_ "LongName" SG_ 342 IChSysTrBrkAxleToqValV "Chassis System transmission Brake Axle Torque Value Valid";
BA_ "SysSignalName" SG_ 342 IChSysTrBrkAxleToqValV "ChSysTrBrkAxleToqValV";
BA_ "CompuMethodName" SG_ 329 IIBS_20ms_Group09_CRC "IBS_20ms_Group09_CRC";
BA_ "ISignalName" SG_ 329 IIBS_20ms_Group09_CRC "IIBS_20ms_Group09_CRC";
BA_ "LongName" SG_ 329 IIBS_20ms_Group09_CRC "Wheel Ground Velocity Right Driven Cyclic Redundancy Check";
BA_ "SysSignalName" SG_ 329 IIBS_20ms_Group09_CRC "IBS_20ms_Group09_CRC";
BA_ "CompuMethodName" SG_ 329 IIBS_20ms_Group09_RC "IBS_20ms_Group09_RC";
BA_ "ISignalName" SG_ 329 IIBS_20ms_Group09_RC "IIBS_20ms_Group09_RC";
BA_ "LongName" SG_ 329 IIBS_20ms_Group09_RC "Wheel Ground Velocity Right Driven Rolling Count";
BA_ "SysSignalName" SG_ 329 IIBS_20ms_Group09_RC "IBS_20ms_Group09_RC";
BA_ "CompuMethodName" SG_ 329 ILDrvnWhlRotlDircn "LDrvnWhlRotlDircn";
BA_ "GenSigStartValue" SG_ 329 ILDrvnWhlRotlDircn 3;
BA_ "ISignalName" SG_ 329 ILDrvnWhlRotlDircn "ILDrvnWhlRotlDircn";
BA_ "LongName" SG_ 329 ILDrvnWhlRotlDircn "Left Driven Wheel Rotational Direction";
BA_ "SysSignalName" SG_ 329 ILDrvnWhlRotlDircn "LDrvnWhlRotlDircn";
BA_ "CompuMethodName" SG_ 329 IRDrvnWhlRotlDircn "RDrvnWhlRotlDircn";
BA_ "GenSigStartValue" SG_ 329 IRDrvnWhlRotlDircn 3;
BA_ "ISignalName" SG_ 329 IRDrvnWhlRotlDircn "IRDrvnWhlRotlDircn";
BA_ "LongName" SG_ 329 IRDrvnWhlRotlDircn "Right Driven Wheel Rotational Direction";
BA_ "SysSignalName" SG_ 329 IRDrvnWhlRotlDircn "RDrvnWhlRotlDircn";
BA_ "CompuMethodName" SG_ 329 IWhlGndVelRDrvn "WhlGndVelRDrvn";
BA_ "ISignalName" SG_ 329 IWhlGndVelRDrvn "IWhlGndVelRDrvn";
BA_ "LongName" SG_ 329 IWhlGndVelRDrvn "Wheel Ground Velocity Right Driven";
BA_ "SysSignalName" SG_ 329 IWhlGndVelRDrvn "WhlGndVelRDrvn";
BA_ "CompuMethodName" SG_ 329 IWhlGndVelRDrvnV "WhlGndVelRDrvnV";
BA_ "GenSigStartValue" SG_ 329 IWhlGndVelRDrvnV 1;
BA_ "ISignalName" SG_ 329 IWhlGndVelRDrvnV "IWhlGndVelRDrvnV";
BA_ "LongName" SG_ 329 IWhlGndVelRDrvnV "Wheel Ground Velocity Right Driven Validity";
BA_ "SysSignalName" SG_ 329 IWhlGndVelRDrvnV "WhlGndVelRDrvnV";
BA_ "CompuMethodName" SG_ 329 IWhlGndVelLDrvnV "WhlGndVelLDrvnV";
BA_ "GenSigStartValue" SG_ 329 IWhlGndVelLDrvnV 1;
BA_ "ISignalName" SG_ 329 IWhlGndVelLDrvnV "IWhlGndVelLDrvnV";
BA_ "LongName" SG_ 329 IWhlGndVelLDrvnV "Wheel Ground Velocity Left Driven Validity";
BA_ "SysSignalName" SG_ 329 IWhlGndVelLDrvnV "WhlGndVelLDrvnV";
BA_ "CompuMethodName" SG_ 329 IWhlGndVelLDrvn "WhlGndVelLDrvn";
BA_ "ISignalName" SG_ 329 IWhlGndVelLDrvn "IWhlGndVelLDrvn";
BA_ "LongName" SG_ 329 IWhlGndVelLDrvn "Wheel Ground Velocity Left Driven";
BA_ "SysSignalName" SG_ 329 IWhlGndVelLDrvn "WhlGndVelLDrvn";
BA_ "CompuMethodName" SG_ 329 IRDrvnWhlRotlDircnSdslSts "RDrvnWhlRotlDircnSdslSts";
BA_ "ISignalName" SG_ 329 IRDrvnWhlRotlDircnSdslSts "IRDrvnWhlRotlDircnSdslSts";
BA_ "LongName" SG_ 329 IRDrvnWhlRotlDircnSdslSts "Right Driven Wheel Rotational Direction Standstill Status";
BA_ "SysSignalName" SG_ 329 IRDrvnWhlRotlDircnSdslSts "RDrvnWhlRotlDircnSdslSts";
BA_ "CompuMethodName" SG_ 329 ILDrvnWhlRotlDircnSdslSts "LDrvnWhlRotlDircnSdslSts";
BA_ "ISignalName" SG_ 329 ILDrvnWhlRotlDircnSdslSts "ILDrvnWhlRotlDircnSdslSts";
BA_ "LongName" SG_ 329 ILDrvnWhlRotlDircnSdslSts "Left Driven Wheel Rotational Direction Standstill Status";
BA_ "SysSignalName" SG_ 329 ILDrvnWhlRotlDircnSdslSts "LDrvnWhlRotlDircnSdslSts";
BA_ "CompuMethodName" SG_ 329 IChSysTotBrkAxleToqVal "ChSysTotBrkAxleToqVal";
BA_ "ISignalName" SG_ 329 IChSysTotBrkAxleToqVal "IChSysTotBrkAxleToqVal";
BA_ "LongName" SG_ 329 IChSysTotBrkAxleToqVal "Chassis System Total Brake Axle Torque Value";
BA_ "SysSignalName" SG_ 329 IChSysTotBrkAxleToqVal "ChSysTotBrkAxleToqVal";
BA_ "CompuMethodName" SG_ 329 IIBS_20ms_Group09_Reserved1 "IBS_20ms_Group09_Reserved1";
BA_ "GenSigStartValue" SG_ 329 IIBS_20ms_Group09_Reserved1 1;
BA_ "ISignalName" SG_ 329 IIBS_20ms_Group09_Reserved1 "IIBS_20ms_Group09_Reserved1";
BA_ "SysSignalName" SG_ 329 IIBS_20ms_Group09_Reserved1 "IBS_20ms_Group09_Reserved1";
BA_ "CompuMethodName" SG_ 329 IChSysTotBrkAxleToqValV "ChSysTotBrkAxleToqValV";
BA_ "ISignalName" SG_ 329 IChSysTotBrkAxleToqValV "IChSysTotBrkAxleToqValV";
BA_ "LongName" SG_ 329 IChSysTotBrkAxleToqValV "Chassis System Total Brake Axle Torque Value Valid";
BA_ "SysSignalName" SG_ 329 IChSysTotBrkAxleToqValV "ChSysTotBrkAxleToqValV";
BA_ "CompuMethodName" SG_ 425 IIBS_20ms_Group11_CRC "IBS_20ms_Group11_CRC";
BA_ "ISignalName" SG_ 425 IIBS_20ms_Group11_CRC "IIBS_20ms_Group11_CRC";
BA_ "LongName" SG_ 425 IIBS_20ms_Group11_CRC "Vehicle Speed Average Cyclic Redundancy Check";
BA_ "SysSignalName" SG_ 425 IIBS_20ms_Group11_CRC "IBS_20ms_Group11_CRC";
BA_ "CompuMethodName" SG_ 425 IIBS_20ms_Group11_RC "IBS_20ms_Group11_RC";
BA_ "ISignalName" SG_ 425 IIBS_20ms_Group11_RC "IIBS_20ms_Group11_RC";
BA_ "LongName" SG_ 425 IIBS_20ms_Group11_RC "Vehicle Speed Average Alive Rolling Count";
BA_ "SysSignalName" SG_ 425 IIBS_20ms_Group11_RC "IBS_20ms_Group11_RC";
BA_ "CompuMethodName" SG_ 425 IIBS_20ms_Group11_Reserved1 "IBS_20ms_Group11_Reserved1";
BA_ "GenSigStartValue" SG_ 425 IIBS_20ms_Group11_Reserved1 7;
BA_ "ISignalName" SG_ 425 IIBS_20ms_Group11_Reserved1 "IIBS_20ms_Group11_Reserved1";
BA_ "SysSignalName" SG_ 425 IIBS_20ms_Group11_Reserved1 "IBS_20ms_Group11_Reserved1";
BA_ "CompuMethodName" SG_ 425 IVehSpdAvgNonDrvnV "VehSpdAvgNonDrvnV";
BA_ "ISignalName" SG_ 425 IVehSpdAvgNonDrvnV "IVehSpdAvgNonDrvnV";
BA_ "LongName" SG_ 425 IVehSpdAvgNonDrvnV "Vehicle Speed Average Non Driven Validity";
BA_ "SysSignalName" SG_ 425 IVehSpdAvgNonDrvnV "VehSpdAvgNonDrvnV";
BA_ "CompuMethodName" SG_ 425 IVehSpdAvg "VehSpdAvg";
BA_ "GenSigStartValue" SG_ 425 IVehSpdAvg 1;
BA_ "ISignalName" SG_ 425 IVehSpdAvg "IVehSpdAvg";
BA_ "LongName" SG_ 425 IVehSpdAvg "Vehicle Speed Average";
BA_ "SysSignalName" SG_ 425 IVehSpdAvg "VehSpdAvg";
BA_ "CompuMethodName" SG_ 425 IVehSpdAvgV "VehSpdAvgV";
BA_ "ISignalName" SG_ 425 IVehSpdAvgV "IVehSpdAvgV";
BA_ "LongName" SG_ 425 IVehSpdAvgV "Vehicle Speed Average Validity";
BA_ "SysSignalName" SG_ 425 IVehSpdAvgV "VehSpdAvgV";
BA_ "CompuMethodName" SG_ 425 IVehSpdAvgDrvn "VehSpdAvgDrvn";
BA_ "ISignalName" SG_ 425 IVehSpdAvgDrvn "IVehSpdAvgDrvn";
BA_ "LongName" SG_ 425 IVehSpdAvgDrvn "Vehicle Speed Average Driven";
BA_ "SysSignalName" SG_ 425 IVehSpdAvgDrvn "VehSpdAvgDrvn";
BA_ "CompuMethodName" SG_ 425 IVehSpdAvgDrvnV "VehSpdAvgDrvnV";
BA_ "ISignalName" SG_ 425 IVehSpdAvgDrvnV "IVehSpdAvgDrvnV";
BA_ "LongName" SG_ 425 IVehSpdAvgDrvnV "Vehicle Speed Average Driven Validity";
BA_ "SysSignalName" SG_ 425 IVehSpdAvgDrvnV "VehSpdAvgDrvnV";
BA_ "CompuMethodName" SG_ 425 IVehSpdAvgNonDrvn "VehSpdAvgNonDrvn";
BA_ "ISignalName" SG_ 425 IVehSpdAvgNonDrvn "IVehSpdAvgNonDrvn";
BA_ "LongName" SG_ 425 IVehSpdAvgNonDrvn "Vehicle Speed Average Non Driven";
BA_ "SysSignalName" SG_ 425 IVehSpdAvgNonDrvn "VehSpdAvgNonDrvn";
BA_ "CompuMethodName" SG_ 425 IVehSpdAvgDrvnSrc "VehSpdAvgDrvnSrc";
BA_ "ISignalName" SG_ 425 IVehSpdAvgDrvnSrc "IVehSpdAvgDrvnSrc";
BA_ "LongName" SG_ 425 IVehSpdAvgDrvnSrc "Vehicle Speed Average Driven Source";
BA_ "SysSignalName" SG_ 425 IVehSpdAvgDrvnSrc "VehSpdAvgDrvnSrc";
BA_ "CompuMethodName" SG_ 339 IIBS_20ms_Group12_CRC "IBS_20ms_Group12_CRC";
BA_ "ISignalName" SG_ 339 IIBS_20ms_Group12_CRC "IIBS_20ms_Group12_CRC";
BA_ "LongName" SG_ 339 IIBS_20ms_Group12_CRC "Wheel Ground Velocity Left Non Driven Cyclic Redundancy Check";
BA_ "SysSignalName" SG_ 339 IIBS_20ms_Group12_CRC "IBS_20ms_Group12_CRC";
BA_ "CompuMethodName" SG_ 339 IIBS_20ms_Group12_RC "IBS_20ms_Group12_RC";
BA_ "ISignalName" SG_ 339 IIBS_20ms_Group12_RC "IIBS_20ms_Group12_RC";
BA_ "LongName" SG_ 339 IIBS_20ms_Group12_RC "Wheel Ground Velocity Left Non Driven Rolling Count";
BA_ "SysSignalName" SG_ 339 IIBS_20ms_Group12_RC "IBS_20ms_Group12_RC";
BA_ "CompuMethodName" SG_ 339 IRNonDrvnWhlRotlDircn "RNonDrvnWhlRotlDircn";
BA_ "GenSigStartValue" SG_ 339 IRNonDrvnWhlRotlDircn 3;
BA_ "ISignalName" SG_ 339 IRNonDrvnWhlRotlDircn "IRNonDrvnWhlRotlDircn";
BA_ "LongName" SG_ 339 IRNonDrvnWhlRotlDircn "Right Non Driven Wheel Rotational Direction";
BA_ "SysSignalName" SG_ 339 IRNonDrvnWhlRotlDircn "RNonDrvnWhlRotlDircn";
BA_ "CompuMethodName" SG_ 339 ILNonDrvnWhlRotlDircn "LNonDrvnWhlRotlDircn";
BA_ "GenSigStartValue" SG_ 339 ILNonDrvnWhlRotlDircn 3;
BA_ "ISignalName" SG_ 339 ILNonDrvnWhlRotlDircn "ILNonDrvnWhlRotlDircn";
BA_ "LongName" SG_ 339 ILNonDrvnWhlRotlDircn "Left Non Driven Wheel Rotational Direction";
BA_ "SysSignalName" SG_ 339 ILNonDrvnWhlRotlDircn "LNonDrvnWhlRotlDircn";
BA_ "CompuMethodName" SG_ 339 IWhlGndVelRNonDrvn "WhlGndVelRNonDrvn";
BA_ "ISignalName" SG_ 339 IWhlGndVelRNonDrvn "IWhlGndVelRNonDrvn";
BA_ "LongName" SG_ 339 IWhlGndVelRNonDrvn "Wheel Ground Velocity Right Non Driven";
BA_ "SysSignalName" SG_ 339 IWhlGndVelRNonDrvn "WhlGndVelRNonDrvn";
BA_ "CompuMethodName" SG_ 339 IWhlGndVelRNonDrvnV "WhlGndVelRNonDrvnV";
BA_ "GenSigStartValue" SG_ 339 IWhlGndVelRNonDrvnV 1;
BA_ "ISignalName" SG_ 339 IWhlGndVelRNonDrvnV "IWhlGndVelRNonDrvnV";
BA_ "LongName" SG_ 339 IWhlGndVelRNonDrvnV "Wheel Ground Velocity Right Non Driven Validity";
BA_ "SysSignalName" SG_ 339 IWhlGndVelRNonDrvnV "WhlGndVelRNonDrvnV";
BA_ "CompuMethodName" SG_ 339 IWhlGndVelLNonDrvnV "WhlGndVelLNonDrvnV";
BA_ "GenSigStartValue" SG_ 339 IWhlGndVelLNonDrvnV 1;
BA_ "ISignalName" SG_ 339 IWhlGndVelLNonDrvnV "IWhlGndVelLNonDrvnV";
BA_ "LongName" SG_ 339 IWhlGndVelLNonDrvnV "Wheel Ground Velocity Left Non Driven Validity";
BA_ "SysSignalName" SG_ 339 IWhlGndVelLNonDrvnV "WhlGndVelLNonDrvnV";
BA_ "CompuMethodName" SG_ 339 IWhlGndVelLNonDrvn "WhlGndVelLNonDrvn";
BA_ "ISignalName" SG_ 339 IWhlGndVelLNonDrvn "IWhlGndVelLNonDrvn";
BA_ "LongName" SG_ 339 IWhlGndVelLNonDrvn "Wheel Ground Velocity Left Non Driven";
BA_ "SysSignalName" SG_ 339 IWhlGndVelLNonDrvn "WhlGndVelLNonDrvn";
BA_ "CompuMethodName" SG_ 339 IRNonDrvnWhlRotlDircnSdslSts "RNonDrvnWhlRotlDircnSdslSts";
BA_ "ISignalName" SG_ 339 IRNonDrvnWhlRotlDircnSdslSts "IRNonDrvnWhlRotlDircnSdslSts";
BA_ "LongName" SG_ 339 IRNonDrvnWhlRotlDircnSdslSts "Right Non Driven Wheel Rotational Direction Standstill Status";
BA_ "SysSignalName" SG_ 339 IRNonDrvnWhlRotlDircnSdslSts "RNonDrvnWhlRotlDircnSdslSts";
BA_ "CompuMethodName" SG_ 339 ILNonDrvnWhlRotlDircnSdslSts "LNonDrvnWhlRotlDircnSdslSts";
BA_ "ISignalName" SG_ 339 ILNonDrvnWhlRotlDircnSdslSts "ILNonDrvnWhlRotlDircnSdslSts";
BA_ "LongName" SG_ 339 ILNonDrvnWhlRotlDircnSdslSts "Left Non Driven Wheel Rotational Direction Standstill Status";
BA_ "SysSignalName" SG_ 339 ILNonDrvnWhlRotlDircnSdslSts "LNonDrvnWhlRotlDircnSdslSts";
BA_ "CompuMethodName" SG_ 339 IIBS_20ms_Group12_Reserved1 "IBS_20ms_Group12_Reserved1";
BA_ "GenSigStartValue" SG_ 339 IIBS_20ms_Group12_Reserved1 255;
BA_ "ISignalName" SG_ 339 IIBS_20ms_Group12_Reserved1 "IIBS_20ms_Group12_Reserved1";
BA_ "SysSignalName" SG_ 339 IIBS_20ms_Group12_Reserved1 "IBS_20ms_Group12_Reserved1";
BA_ "CompuMethodName" SG_ 339 IIBS_20ms_Group12_Reserved2 "IBS_20ms_Group12_Reserved2";
BA_ "GenSigStartValue" SG_ 339 IIBS_20ms_Group12_Reserved2 255;
BA_ "ISignalName" SG_ 339 IIBS_20ms_Group12_Reserved2 "IIBS_20ms_Group12_Reserved2";
BA_ "SysSignalName" SG_ 339 IIBS_20ms_Group12_Reserved2 "IBS_20ms_Group12_Reserved2";
BA_ "CompuMethodName" SG_ 1688 ISCSToIECUCtrlPotcl "SCSToIECUCtrlPotcl";
BA_ "ISignalName" SG_ 1688 ISCSToIECUCtrlPotcl "ISCSToIECUCtrlPotcl";
BA_ "LongName" SG_ 1688 ISCSToIECUCtrlPotcl "Stability_Control_System_To_Intelligent_Electric_Control_Unit_Control_Protocol";
BA_ "SysSignalName" SG_ 1688 ISCSToIECUCtrlPotcl "SCSToIECUCtrlPotcl";
BA_ "CompuMethodName" SG_ 1272 IIBS_NM_BSMtoRMS_CHCANFD "IBS_NM_BSMtoRMS_CHCANFD";
BA_ "ISignalName" SG_ 1272 IIBS_NM_BSMtoRMS_CHCANFD "IIBS_NM_BSMtoRMS_CHCANFD";
BA_ "LongName" SG_ 1272 IIBS_NM_BSMtoRMS_CHCANFD "IBS NM BSMtoRMS CHCANFD";
BA_ "SysSignalName" SG_ 1272 IIBS_NM_BSMtoRMS_CHCANFD "IBS_NM_BSMtoRMS_CHCANFD";
BA_ "CompuMethodName" SG_ 1272 IIBS_NM_PBSMtoRMS_CHCANFD "IBS_NM_PBSMtoRMS_CHCANFD";
BA_ "ISignalName" SG_ 1272 IIBS_NM_PBSMtoRMS_CHCANFD "IIBS_NM_PBSMtoRMS_CHCANFD";
BA_ "LongName" SG_ 1272 IIBS_NM_PBSMtoRMS_CHCANFD "IBS NM PBSMtoRMS CHCANFD";
BA_ "SysSignalName" SG_ 1272 IIBS_NM_PBSMtoRMS_CHCANFD "IBS_NM_PBSMtoRMS_CHCANFD";
BA_ "CompuMethodName" SG_ 1272 IIBS_NM_RMStoNOS_CHCANFD "IBS_NM_RMStoNOS_CHCANFD";
BA_ "ISignalName" SG_ 1272 IIBS_NM_RMStoNOS_CHCANFD "IIBS_NM_RMStoNOS_CHCANFD";
BA_ "LongName" SG_ 1272 IIBS_NM_RMStoNOS_CHCANFD "IBS NM RMStoNOS CHCANFD";
BA_ "SysSignalName" SG_ 1272 IIBS_NM_RMStoNOS_CHCANFD "IBS_NM_RMStoNOS_CHCANFD";
BA_ "CompuMethodName" SG_ 1272 IIBS_NM_RSStoNOS_CHCANFD "IBS_NM_RSStoNOS_CHCANFD";
BA_ "ISignalName" SG_ 1272 IIBS_NM_RSStoNOS_CHCANFD "IIBS_NM_RSStoNOS_CHCANFD";
BA_ "LongName" SG_ 1272 IIBS_NM_RSStoNOS_CHCANFD "IBS NM RSStoNOS CHCANFD";
BA_ "SysSignalName" SG_ 1272 IIBS_NM_RSStoNOS_CHCANFD "IBS_NM_RSStoNOS_CHCANFD";
BA_ "CompuMethodName" SG_ 1272 IIBS_NM_RSStoRMS_CHCANFD "IBS_NM_RSStoRMS_CHCANFD";
BA_ "ISignalName" SG_ 1272 IIBS_NM_RSStoRMS_CHCANFD "IIBS_NM_RSStoRMS_CHCANFD";
BA_ "LongName" SG_ 1272 IIBS_NM_RSStoRMS_CHCANFD "IBS NM RSStoRMS CHCANFD";
BA_ "SysSignalName" SG_ 1272 IIBS_NM_RSStoRMS_CHCANFD "IBS_NM_RSStoRMS_CHCANFD";
BA_ "CompuMethodName" SG_ 1272 IIBS_NM_NOStoRMS_CHCANFD "IBS_NM_NOStoRMS_CHCANFD";
BA_ "ISignalName" SG_ 1272 IIBS_NM_NOStoRMS_CHCANFD "IIBS_NM_NOStoRMS_CHCANFD";
BA_ "LongName" SG_ 1272 IIBS_NM_NOStoRMS_CHCANFD "IBS NM NOStoRMS CHCANFD";
BA_ "SysSignalName" SG_ 1272 IIBS_NM_NOStoRMS_CHCANFD "IBS_NM_NOStoRMS_CHCANFD";
BA_ "CompuMethodName" SG_ 1272 IIBS_NM_NOSSta_CHCANFD "IBS_NM_NOSSta_CHCANFD";
BA_ "ISignalName" SG_ 1272 IIBS_NM_NOSSta_CHCANFD "IIBS_NM_NOSSta_CHCANFD";
BA_ "LongName" SG_ 1272 IIBS_NM_NOSSta_CHCANFD "IBS NM NOSSta CHCANFD";
BA_ "SysSignalName" SG_ 1272 IIBS_NM_NOSSta_CHCANFD "IBS_NM_NOSSta_CHCANFD";
BA_ "CompuMethodName" SG_ 1272 IIBS_NM_RMSSta_CHCANFD "IBS_NM_RMSSta_CHCANFD";
BA_ "ISignalName" SG_ 1272 IIBS_NM_RMSSta_CHCANFD "IIBS_NM_RMSSta_CHCANFD";
BA_ "LongName" SG_ 1272 IIBS_NM_RMSSta_CHCANFD "IBS NM RMSSta CHCANFD";
BA_ "SysSignalName" SG_ 1272 IIBS_NM_RMSSta_CHCANFD "IBS_NM_RMSSta_CHCANFD";
BA_ "CompuMethodName" SG_ 1272 IIBS_NWI_CHCANFD "IBS_NWI_CHCANFD";
BA_ "ISignalName" SG_ 1272 IIBS_NWI_CHCANFD "IIBS_NWI_CHCANFD";
BA_ "LongName" SG_ 1272 IIBS_NWI_CHCANFD "IBS CHCANFD Network Wakeup Indication";
BA_ "SysSignalName" SG_ 1272 IIBS_NWI_CHCANFD "IBS_NWI_CHCANFD";
BA_ "CompuMethodName" SG_ 1272 IIBS_NOI_CHCANFD "IBS_NOI_CHCANFD";
BA_ "ISignalName" SG_ 1272 IIBS_NOI_CHCANFD "IIBS_NOI_CHCANFD";
BA_ "LongName" SG_ 1272 IIBS_NOI_CHCANFD "IBS CHCANFD Network Operation Indication";
BA_ "SysSignalName" SG_ 1272 IIBS_NOI_CHCANFD "IBS_NOI_CHCANFD";
BA_ "CompuMethodName" SG_ 1272 IIBS_NKI_CHCANFD "IBS_NKI_CHCANFD";
BA_ "ISignalName" SG_ 1272 IIBS_NKI_CHCANFD "IIBS_NKI_CHCANFD";
BA_ "LongName" SG_ 1272 IIBS_NKI_CHCANFD "IBS CHCANFD Network Keep Indication";
BA_ "SysSignalName" SG_ 1272 IIBS_NKI_CHCANFD "IBS_NKI_CHCANFD";
BA_ "CompuMethodName" SG_ 507 IIBS_ZONE_20ms_Group08_CRC "IBS_ZONE_20ms_Group08_CRC";
BA_ "ISignalName" SG_ 507 IIBS_ZONE_20ms_Group08_CRC "IIBS_ZONE_20ms_Group08_CRC";
BA_ "SysSignalName" SG_ 507 IIBS_ZONE_20ms_Group08_CRC "IBS_ZONE_20ms_Group08_CRC";
BA_ "CompuMethodName" SG_ 507 IIBS_ZONE_20ms_Group08_RC "IBS_ZONE_20ms_Group08_RC";
BA_ "ISignalName" SG_ 507 IIBS_ZONE_20ms_Group08_RC "IIBS_ZONE_20ms_Group08_RC";
BA_ "SysSignalName" SG_ 507 IIBS_ZONE_20ms_Group08_RC "IBS_ZONE_20ms_Group08_RC";
BA_ "CompuMethodName" SG_ 507 IIBS_ZONE_20ms_Group08_Reserved1 "IBS_ZONE_20ms_Group08_Reserved1";
BA_ "GenSigStartValue" SG_ 507 IIBS_ZONE_20ms_Group08_Reserved1 1;
BA_ "ISignalName" SG_ 507 IIBS_ZONE_20ms_Group08_Reserved1 "IIBS_ZONE_20ms_Group08_Reserved1";
BA_ "SysSignalName" SG_ 507 IIBS_ZONE_20ms_Group08_Reserved1 "IBS_ZONE_20ms_Group08_Reserved1";
BA_ "CompuMethodName" SG_ 507 IEPBAppcnSts_M "EPBAppcnSts_M";
BA_ "GenSigStartValue" SG_ 507 IEPBAppcnSts_M 2;
BA_ "ISignalName" SG_ 507 IEPBAppcnSts_M "IEPBAppcnSts_M";
BA_ "LongName" SG_ 507 IEPBAppcnSts_M "Electric Park Brake Application Status Master";
BA_ "SysSignalName" SG_ 507 IEPBAppcnSts_M "EPBAppcnSts_M";
BA_ "CompuMethodName" SG_ 507 IIBSRespAccToqVal "IBSRespAccToqVal";
BA_ "ISignalName" SG_ 507 IIBSRespAccToqVal "IIBSRespAccToqVal";
BA_ "LongName" SG_ 507 IIBSRespAccToqVal "IBS Response Acceleration Request Torque Value";
BA_ "SysSignalName" SG_ 507 IIBSRespAccToqVal "IBSRespAccToqVal";
BA_ "CompuMethodName" SG_ 507 IIBS_ZONE_20ms_Group08_Reserved2 "IBS_ZONE_20ms_Group08_Reserved2";
BA_ "GenSigStartValue" SG_ 507 IIBS_ZONE_20ms_Group08_Reserved2 255;
BA_ "ISignalName" SG_ 507 IIBS_ZONE_20ms_Group08_Reserved2 "IIBS_ZONE_20ms_Group08_Reserved2";
BA_ "SysSignalName" SG_ 507 IIBS_ZONE_20ms_Group08_Reserved2 "IBS_ZONE_20ms_Group08_Reserved2";
BA_ "CompuMethodName" SG_ 507 IIBS_ZONE_20ms_Group08_Reserved3 "IBS_ZONE_20ms_Group08_Reserved3";
BA_ "GenSigStartValue" SG_ 507 IIBS_ZONE_20ms_Group08_Reserved3 255;
BA_ "ISignalName" SG_ 507 IIBS_ZONE_20ms_Group08_Reserved3 "IIBS_ZONE_20ms_Group08_Reserved3";
BA_ "SysSignalName" SG_ 507 IIBS_ZONE_20ms_Group08_Reserved3 "IBS_ZONE_20ms_Group08_Reserved3";
BA_ "CompuMethodName" SG_ 507 IIBS_ZONE_20ms_Group08_Reserved4 "IBS_ZONE_20ms_Group08_Reserved4";
BA_ "GenSigStartValue" SG_ 507 IIBS_ZONE_20ms_Group08_Reserved4 255;
BA_ "ISignalName" SG_ 507 IIBS_ZONE_20ms_Group08_Reserved4 "IIBS_ZONE_20ms_Group08_Reserved4";
BA_ "SysSignalName" SG_ 507 IIBS_ZONE_20ms_Group08_Reserved4 "IBS_ZONE_20ms_Group08_Reserved4";
BA_ "CompuMethodName" SG_ 507 IBrkBstFnSts "BrkBstFnSts";
BA_ "ISignalName" SG_ 507 IBrkBstFnSts "IBrkBstFnSts";
BA_ "LongName" SG_ 507 IBrkBstFnSts "Brake Boost Function Status";
BA_ "SysSignalName" SG_ 507 IBrkBstFnSts "BrkBstFnSts";
BA_ "CompuMethodName" SG_ 507 IIBS_ZONE_20ms_Group08_Reserved5 "IBS_ZONE_20ms_Group08_Reserved5";
BA_ "GenSigStartValue" SG_ 507 IIBS_ZONE_20ms_Group08_Reserved5 31;
BA_ "ISignalName" SG_ 507 IIBS_ZONE_20ms_Group08_Reserved5 "IIBS_ZONE_20ms_Group08_Reserved5";
BA_ "SysSignalName" SG_ 507 IIBS_ZONE_20ms_Group08_Reserved5 "IBS_ZONE_20ms_Group08_Reserved5";
BA_ "CompuMethodName" SG_ 917 IAIPiloTIntervQuit "AIPiloTIntervQuit";
BA_ "ISignalName" SG_ 917 IAIPiloTIntervQuit "IAIPiloTIntervQuit";
BA_ "LongName" SG_ 917 IAIPiloTIntervQuit "Ai Pilot Intervene Quit";
BA_ "SysSignalName" SG_ 917 IAIPiloTIntervQuit "AIPiloTIntervQuit";
BA_ "CompuMethodName" SG_ 917 IAIParkngDsp "AIParkngDsp";
BA_ "ISignalName" SG_ 917 IAIParkngDsp "IAIParkngDsp";
BA_ "LongName" SG_ 917 IAIParkngDsp "Ai Parking Display";
BA_ "SysSignalName" SG_ 917 IAIParkngDsp "AIParkngDsp";
BA_ "CompuMethodName" SG_ 917 IAIParkngSts "AIParkngSts";
BA_ "ISignalName" SG_ 917 IAIParkngSts "IAIParkngSts";
BA_ "LongName" SG_ 917 IAIParkngSts "Ai Parking Status";
BA_ "SysSignalName" SG_ 917 IAIParkngSts "AIParkngSts";
BA_ "CompuMethodName" SG_ 382 IICBAD_20ms_Group07_CRC "ICBAD_20ms_Group07_CRC";
BA_ "ISignalName" SG_ 382 IICBAD_20ms_Group07_CRC "IICBAD_20ms_Group07_CRC";
BA_ "SysSignalName" SG_ 382 IICBAD_20ms_Group07_CRC "ICBAD_20ms_Group07_CRC";
BA_ "CompuMethodName" SG_ 382 IICBAD_20ms_Group07_RC "ICBAD_20ms_Group07_RC";
BA_ "ISignalName" SG_ 382 IICBAD_20ms_Group07_RC "IICBAD_20ms_Group07_RC";
BA_ "SysSignalName" SG_ 382 IICBAD_20ms_Group07_RC "ICBAD_20ms_Group07_RC";
BA_ "CompuMethodName" SG_ 382 IACCSdslReq "ACCSdslReq";
BA_ "ISignalName" SG_ 382 IACCSdslReq "IACCSdslReq";
BA_ "LongName" SG_ 382 IACCSdslReq "Adaptive Cruise Control Standstill Request";
BA_ "SysSignalName" SG_ 382 IACCSdslReq "ACCSdslReq";
BA_ "CompuMethodName" SG_ 382 IACCGoReq "ACCGoReq";
BA_ "ISignalName" SG_ 382 IACCGoReq "IACCGoReq";
BA_ "LongName" SG_ 382 IACCGoReq "Adaptive Cruise Control Go Request";
BA_ "SysSignalName" SG_ 382 IACCGoReq "ACCGoReq";
BA_ "CompuMethodName" SG_ 382 IACCAccReqSts_CH "ACCAccReqSts_CH";
BA_ "ISignalName" SG_ 382 IACCAccReqSts_CH "IACCAccReqSts_CH";
BA_ "LongName" SG_ 382 IACCAccReqSts_CH "Adaptive Cruise Control Acceleration Request Status";
BA_ "SysSignalName" SG_ 382 IACCAccReqSts_CH "ACCAccReqSts_CH";
BA_ "CompuMethodName" SG_ 382 IACCAccReqVal "ACCAccReqVal";
BA_ "GenSigStartValue" SG_ 382 IACCAccReqVal 1713;
BA_ "ISignalName" SG_ 382 IACCAccReqVal "IACCAccReqVal";
BA_ "LongName" SG_ 382 IACCAccReqVal "Adaptive Cruise Control Acceleration Request Value";
BA_ "SysSignalName" SG_ 382 IACCAccReqVal "ACCAccReqVal";
BA_ "CompuMethodName" SG_ 382 IICBAD_20ms_Group07_Reserved1 "ICBAD_20ms_Group07_Reserved1";
BA_ "GenSigStartValue" SG_ 382 IICBAD_20ms_Group07_Reserved1 3;
BA_ "ISignalName" SG_ 382 IICBAD_20ms_Group07_Reserved1 "IICBAD_20ms_Group07_Reserved1";
BA_ "SysSignalName" SG_ 382 IICBAD_20ms_Group07_Reserved1 "ICBAD_20ms_Group07_Reserved1";
BA_ "CompuMethodName" SG_ 382 IACCSysFltSts "ACCSysFltSts";
BA_ "ISignalName" SG_ 382 IACCSysFltSts "IACCSysFltSts";
BA_ "LongName" SG_ 382 IACCSysFltSts "Adaptive Cruise Control System Fault Status";
BA_ "SysSignalName" SG_ 382 IACCSysFltSts "ACCSysFltSts";
BA_ "CompuMethodName" SG_ 382 IICBAD_20ms_Group07_Reserved3 "ICBAD_20ms_Group07_Reserved3";
BA_ "GenSigStartValue" SG_ 382 IICBAD_20ms_Group07_Reserved3 7;
BA_ "ISignalName" SG_ 382 IICBAD_20ms_Group07_Reserved3 "IICBAD_20ms_Group07_Reserved3";
BA_ "SysSignalName" SG_ 382 IICBAD_20ms_Group07_Reserved3 "ICBAD_20ms_Group07_Reserved3";
BA_ "CompuMethodName" SG_ 382 IACCSysSts "ACCSysSts";
BA_ "ISignalName" SG_ 382 IACCSysSts "IACCSysSts";
BA_ "LongName" SG_ 382 IACCSysSts "Adaptive Cruise Control System Status";
BA_ "SysSignalName" SG_ 382 IACCSysSts "ACCSysSts";
BA_ "CompuMethodName" SG_ 382 IICBAD_20ms_Group07_Reserved2 "ICBAD_20ms_Group07_Reserved2";
BA_ "GenSigStartValue" SG_ 382 IICBAD_20ms_Group07_Reserved2 3;
BA_ "ISignalName" SG_ 382 IICBAD_20ms_Group07_Reserved2 "IICBAD_20ms_Group07_Reserved2";
BA_ "SysSignalName" SG_ 382 IICBAD_20ms_Group07_Reserved2 "ICBAD_20ms_Group07_Reserved2";
BA_ "CompuMethodName" SG_ 382 IICBAD_20ms_Group07_Reserved4 "ICBAD_20ms_Group07_Reserved4";
BA_ "GenSigStartValue" SG_ 382 IICBAD_20ms_Group07_Reserved4 255;
BA_ "ISignalName" SG_ 382 IICBAD_20ms_Group07_Reserved4 "IICBAD_20ms_Group07_Reserved4";
BA_ "SysSignalName" SG_ 382 IICBAD_20ms_Group07_Reserved4 "ICBAD_20ms_Group07_Reserved4";
BA_ "CompuMethodName" SG_ 382 IICBAD_20ms_Group07_Reserved5 "ICBAD_20ms_Group07_Reserved5";
BA_ "GenSigStartValue" SG_ 382 IICBAD_20ms_Group07_Reserved5 255;
BA_ "ISignalName" SG_ 382 IICBAD_20ms_Group07_Reserved5 "IICBAD_20ms_Group07_Reserved5";
BA_ "SysSignalName" SG_ 382 IICBAD_20ms_Group07_Reserved5 "ICBAD_20ms_Group07_Reserved5";
BA_ "CompuMethodName" SG_ 382 IICBAD_20ms_Group07_Reserved6 "ICBAD_20ms_Group07_Reserved6";
BA_ "GenSigStartValue" SG_ 382 IICBAD_20ms_Group07_Reserved6 255;
BA_ "ISignalName" SG_ 382 IICBAD_20ms_Group07_Reserved6 "IICBAD_20ms_Group07_Reserved6";
BA_ "SysSignalName" SG_ 382 IICBAD_20ms_Group07_Reserved6 "ICBAD_20ms_Group07_Reserved6";
BA_ "CompuMethodName" SG_ 385 INSAReqAVMDis "NSAReqAVMDis";
BA_ "ISignalName" SG_ 385 INSAReqAVMDis "INSAReqAVMDis";
BA_ "LongName" SG_ 385 INSAReqAVMDis "NSA Request AVM Display";
BA_ "SysSignalName" SG_ 385 INSAReqAVMDis "NSAReqAVMDis";
BA_ "CompuMethodName" SG_ 385 INSADisFucSts "NSADisFucSts";
BA_ "ISignalName" SG_ 385 INSADisFucSts "INSADisFucSts";
BA_ "LongName" SG_ 385 INSADisFucSts "NSA Display Function Status";
BA_ "SysSignalName" SG_ 385 INSADisFucSts "NSADisFucSts";
BA_ "CompuMethodName" SG_ 385 INSABacSysSts "NSABacSysSts";
BA_ "ISignalName" SG_ 385 INSABacSysSts "INSABacSysSts";
BA_ "LongName" SG_ 385 INSABacSysSts "NSA Backward Systerm Status";
BA_ "SysSignalName" SG_ 385 INSABacSysSts "NSABacSysSts";
BA_ "CompuMethodName" SG_ 385 INSAForSysSts "NSAForSysSts";
BA_ "ISignalName" SG_ 385 INSAForSysSts "INSAForSysSts";
BA_ "LongName" SG_ 385 INSAForSysSts "NSA Forward Systerm Status";
BA_ "SysSignalName" SG_ 385 INSAForSysSts "NSAForSysSts";
BA_ "CompuMethodName" SG_ 385 IILDP_ELKWrnng "ILDP_ELKWrnng";
BA_ "ISignalName" SG_ 385 IILDP_ELKWrnng "IILDP_ELKWrnng";
BA_ "LongName" SG_ 385 IILDP_ELKWrnng "LDP ELK Warning Status";
BA_ "SysSignalName" SG_ 385 IILDP_ELKWrnng "ILDP_ELKWrnng";
BA_ "CompuMethodName" SG_ 343 IICBAD_20ms_Group46_CRC "ICBAD_20ms_Group46_CRC";
BA_ "ISignalName" SG_ 343 IICBAD_20ms_Group46_CRC "IICBAD_20ms_Group46_CRC";
BA_ "SysSignalName" SG_ 343 IICBAD_20ms_Group46_CRC "ICBAD_20ms_Group46_CRC";
BA_ "CompuMethodName" SG_ 343 IICBAD_20ms_Group46_RC "ICBAD_20ms_Group46_RC";
BA_ "ISignalName" SG_ 343 IICBAD_20ms_Group46_RC "IICBAD_20ms_Group46_RC";
BA_ "SysSignalName" SG_ 343 IICBAD_20ms_Group46_RC "ICBAD_20ms_Group46_RC";
BA_ "CompuMethodName" SG_ 343 IAEBPrflReq "AEBPrflReq";
BA_ "ISignalName" SG_ 343 IAEBPrflReq "IAEBPrflReq";
BA_ "LongName" SG_ 343 IAEBPrflReq "Autonomous Emergency Braking Prefill Request";
BA_ "SysSignalName" SG_ 343 IAEBPrflReq "AEBPrflReq";
BA_ "CompuMethodName" SG_ 343 IAEBSysSts "AEBSysSts";
BA_ "GenSigStartValue" SG_ 343 IAEBSysSts 1;
BA_ "ISignalName" SG_ 343 IAEBSysSts "IAEBSysSts";
BA_ "LongName" SG_ 343 IAEBSysSts "Autonomous Emergency Braking System Status";
BA_ "SysSignalName" SG_ 343 IAEBSysSts "AEBSysSts";
BA_ "CompuMethodName" SG_ 343 IAEBDclReqSts "AEBDclReqSts";
BA_ "ISignalName" SG_ 343 IAEBDclReqSts "IAEBDclReqSts";
BA_ "LongName" SG_ 343 IAEBDclReqSts "Autonomous Emergency Braking Deceleration Request Status";
BA_ "SysSignalName" SG_ 343 IAEBDclReqSts "AEBDclReqSts";
BA_ "CompuMethodName" SG_ 343 IAEBBrkJerkLvlReq "AEBBrkJerkLvlReq";
BA_ "ISignalName" SG_ 343 IAEBBrkJerkLvlReq "IAEBBrkJerkLvlReq";
BA_ "LongName" SG_ 343 IAEBBrkJerkLvlReq "Autonomous Emergency Braking Brake Jerk Level Request";
BA_ "SysSignalName" SG_ 343 IAEBBrkJerkLvlReq "AEBBrkJerkLvlReq";
BA_ "CompuMethodName" SG_ 343 IAEBHydBrkAstLvlReq "AEBHydBrkAstLvlReq";
BA_ "ISignalName" SG_ 343 IAEBHydBrkAstLvlReq "IAEBHydBrkAstLvlReq";
BA_ "LongName" SG_ 343 IAEBHydBrkAstLvlReq "Autonomous Emergency Braking Hydraulic Brake Assist Level Request";
BA_ "SysSignalName" SG_ 343 IAEBHydBrkAstLvlReq "AEBHydBrkAstLvlReq";
BA_ "CompuMethodName" SG_ 343 IAEBDclReqVal "AEBDclReqVal";
BA_ "GenSigStartValue" SG_ 343 IAEBDclReqVal 127;
BA_ "ISignalName" SG_ 343 IAEBDclReqVal "IAEBDclReqVal";
BA_ "LongName" SG_ 343 IAEBDclReqVal "Autonomous Emergency Braking Deceleration Request Value";
BA_ "SysSignalName" SG_ 343 IAEBDclReqVal "AEBDclReqVal";
BA_ "CompuMethodName" SG_ 343 IICBAD_20ms_Group46_Reserved1 "ICBAD_20ms_Group46_Reserved1";
BA_ "GenSigStartValue" SG_ 343 IICBAD_20ms_Group46_Reserved1 3;
BA_ "ISignalName" SG_ 343 IICBAD_20ms_Group46_Reserved1 "IICBAD_20ms_Group46_Reserved1";
BA_ "SysSignalName" SG_ 343 IICBAD_20ms_Group46_Reserved1 "ICBAD_20ms_Group46_Reserved1";
BA_ "CompuMethodName" SG_ 343 IEBASysSts "EBASysSts";
BA_ "ISignalName" SG_ 343 IEBASysSts "IEBASysSts";
BA_ "SysSignalName" SG_ 343 IEBASysSts "EBASysSts";
BA_ "CompuMethodName" SG_ 343 IAEBSysFltSts "AEBSysFltSts";
BA_ "ISignalName" SG_ 343 IAEBSysFltSts "IAEBSysFltSts";
BA_ "LongName" SG_ 343 IAEBSysFltSts "Autonomous Emergency Braking System Fault Status";
BA_ "SysSignalName" SG_ 343 IAEBSysFltSts "AEBSysFltSts";
BA_ "CompuMethodName" SG_ 343 IICBAD_20ms_Group46_Reserved2 "ICBAD_20ms_Group46_Reserved2";
BA_ "GenSigStartValue" SG_ 343 IICBAD_20ms_Group46_Reserved2 255;
BA_ "ISignalName" SG_ 343 IICBAD_20ms_Group46_Reserved2 "IICBAD_20ms_Group46_Reserved2";
BA_ "SysSignalName" SG_ 343 IICBAD_20ms_Group46_Reserved2 "ICBAD_20ms_Group46_Reserved2";
BA_ "CompuMethodName" SG_ 343 IAEBDclReqToqVal "AEBDclReqToqVal";
BA_ "ISignalName" SG_ 343 IAEBDclReqToqVal "IAEBDclReqToqVal";
BA_ "LongName" SG_ 343 IAEBDclReqToqVal "Autonomous Emergency Braking Deceleration Request Torque Value";
BA_ "SysSignalName" SG_ 343 IAEBDclReqToqVal "AEBDclReqToqVal";
BA_ "CompuMethodName" SG_ 893 IICBAD_100ms_Group25_CRC "ICBAD_100ms_Group25_CRC";
BA_ "ISignalName" SG_ 893 IICBAD_100ms_Group25_CRC "IICBAD_100ms_Group25_CRC";
BA_ "SysSignalName" SG_ 893 IICBAD_100ms_Group25_CRC "ICBAD_100ms_Group25_CRC";
BA_ "CompuMethodName" SG_ 893 IICBAD_100ms_Group25_RC "ICBAD_100ms_Group25_RC";
BA_ "ISignalName" SG_ 893 IICBAD_100ms_Group25_RC "IICBAD_100ms_Group25_RC";
BA_ "SysSignalName" SG_ 893 IICBAD_100ms_Group25_RC "ICBAD_100ms_Group25_RC";
BA_ "CompuMethodName" SG_ 893 IICBAD_100ms_Group25_Reserved1 "ICBAD_100ms_Group25_Reserved1";
BA_ "GenSigStartValue" SG_ 893 IICBAD_100ms_Group25_Reserved1 15;
BA_ "ISignalName" SG_ 893 IICBAD_100ms_Group25_Reserved1 "IICBAD_100ms_Group25_Reserved1";
BA_ "SysSignalName" SG_ 893 IICBAD_100ms_Group25_Reserved1 "ICBAD_100ms_Group25_Reserved1";
BA_ "CompuMethodName" SG_ 893 IICBAD_100ms_Group25_Reserved2 "ICBAD_100ms_Group25_Reserved2";
BA_ "GenSigStartValue" SG_ 893 IICBAD_100ms_Group25_Reserved2 255;
BA_ "ISignalName" SG_ 893 IICBAD_100ms_Group25_Reserved2 "IICBAD_100ms_Group25_Reserved2";
BA_ "SysSignalName" SG_ 893 IICBAD_100ms_Group25_Reserved2 "ICBAD_100ms_Group25_Reserved2";
BA_ "CompuMethodName" SG_ 893 IICBAD_100ms_Group25_Reserved3 "ICBAD_100ms_Group25_Reserved3";
BA_ "GenSigStartValue" SG_ 893 IICBAD_100ms_Group25_Reserved3 127;
BA_ "ISignalName" SG_ 893 IICBAD_100ms_Group25_Reserved3 "IICBAD_100ms_Group25_Reserved3";
BA_ "SysSignalName" SG_ 893 IICBAD_100ms_Group25_Reserved3 "ICBAD_100ms_Group25_Reserved3";
BA_ "CompuMethodName" SG_ 893 IAutodDrvngSysStsV "AutodDrvngSysStsV";
BA_ "ISignalName" SG_ 893 IAutodDrvngSysStsV "IAutodDrvngSysStsV";
BA_ "LongName" SG_ 893 IAutodDrvngSysStsV "Automated Driving System Status Validity";
BA_ "SysSignalName" SG_ 893 IAutodDrvngSysStsV "AutodDrvngSysStsV";
BA_ "CompuMethodName" SG_ 893 IICBAD_100ms_Group25_Reserved4 "ICBAD_100ms_Group25_Reserved4";
BA_ "GenSigStartValue" SG_ 893 IICBAD_100ms_Group25_Reserved4 255;
BA_ "ISignalName" SG_ 893 IICBAD_100ms_Group25_Reserved4 "IICBAD_100ms_Group25_Reserved4";
BA_ "SysSignalName" SG_ 893 IICBAD_100ms_Group25_Reserved4 "ICBAD_100ms_Group25_Reserved4";
BA_ "CompuMethodName" SG_ 893 IICBAD_100ms_Group25_Reserved5 "ICBAD_100ms_Group25_Reserved5";
BA_ "GenSigStartValue" SG_ 893 IICBAD_100ms_Group25_Reserved5 255;
BA_ "ISignalName" SG_ 893 IICBAD_100ms_Group25_Reserved5 "IICBAD_100ms_Group25_Reserved5";
BA_ "SysSignalName" SG_ 893 IICBAD_100ms_Group25_Reserved5 "ICBAD_100ms_Group25_Reserved5";
BA_ "CompuMethodName" SG_ 893 IICBAD_100ms_Group25_Reserved6 "ICBAD_100ms_Group25_Reserved6";
BA_ "GenSigStartValue" SG_ 893 IICBAD_100ms_Group25_Reserved6 255;
BA_ "ISignalName" SG_ 893 IICBAD_100ms_Group25_Reserved6 "IICBAD_100ms_Group25_Reserved6";
BA_ "SysSignalName" SG_ 893 IICBAD_100ms_Group25_Reserved6 "ICBAD_100ms_Group25_Reserved6";
BA_ "CompuMethodName" SG_ 893 IICBAD_100ms_Group25_Reserved7 "ICBAD_100ms_Group25_Reserved7";
BA_ "GenSigStartValue" SG_ 893 IICBAD_100ms_Group25_Reserved7 255;
BA_ "ISignalName" SG_ 893 IICBAD_100ms_Group25_Reserved7 "IICBAD_100ms_Group25_Reserved7";
BA_ "SysSignalName" SG_ 893 IICBAD_100ms_Group25_Reserved7 "ICBAD_100ms_Group25_Reserved7";
BA_ "CompuMethodName" SG_ 360 IICBAD_20ms_Group13_CRC "ICBAD_20ms_Group13_CRC";
BA_ "ISignalName" SG_ 360 IICBAD_20ms_Group13_CRC "IICBAD_20ms_Group13_CRC";
BA_ "SysSignalName" SG_ 360 IICBAD_20ms_Group13_CRC "ICBAD_20ms_Group13_CRC";
BA_ "CompuMethodName" SG_ 360 IICBAD_20ms_Group13_RC "ICBAD_20ms_Group13_RC";
BA_ "ISignalName" SG_ 360 IICBAD_20ms_Group13_RC "IICBAD_20ms_Group13_RC";
BA_ "SysSignalName" SG_ 360 IICBAD_20ms_Group13_RC "ICBAD_20ms_Group13_RC";
BA_ "CompuMethodName" SG_ 360 IAPAShifterPosReqd "APAShifterPosReqd";
BA_ "ISignalName" SG_ 360 IAPAShifterPosReqd "IAPAShifterPosReqd";
BA_ "LongName" SG_ 360 IAPAShifterPosReqd "Advanced Park Assist Shifter Position Requested";
BA_ "SysSignalName" SG_ 360 IAPAShifterPosReqd "APAShifterPosReqd";
BA_ "CompuMethodName" SG_ 360 IAPATrgtEPSStrgWhlAng "APATrgtEPSStrgWhlAng";
BA_ "GenSigStartValue" SG_ 360 IAPATrgtEPSStrgWhlAng 32768;
BA_ "ISignalName" SG_ 360 IAPATrgtEPSStrgWhlAng "IAPATrgtEPSStrgWhlAng";
BA_ "LongName" SG_ 360 IAPATrgtEPSStrgWhlAng "Advanced Park Assist Target Electric Power Steering Steering Wheel Angle";
BA_ "SysSignalName" SG_ 360 IAPATrgtEPSStrgWhlAng "APATrgtEPSStrgWhlAng";
BA_ "CompuMethodName" SG_ 360 IICBAD_20ms_Group13_Reserved1 "ICBAD_20ms_Group13_Reserved1";
BA_ "GenSigStartValue" SG_ 360 IICBAD_20ms_Group13_Reserved1 255;
BA_ "ISignalName" SG_ 360 IICBAD_20ms_Group13_Reserved1 "IICBAD_20ms_Group13_Reserved1";
BA_ "SysSignalName" SG_ 360 IICBAD_20ms_Group13_Reserved1 "ICBAD_20ms_Group13_Reserved1";
BA_ "CompuMethodName" SG_ 360 IAPASCUReqSts "APASCUReqSts";
BA_ "ISignalName" SG_ 360 IAPASCUReqSts "IAPASCUReqSts";
BA_ "LongName" SG_ 360 IAPASCUReqSts "Advanced Park Assist Shifter Control Unit Request Status";
BA_ "SysSignalName" SG_ 360 IAPASCUReqSts "APASCUReqSts";
BA_ "CompuMethodName" SG_ 360 IAPACmdEPSSts "APACmdEPSSts";
BA_ "ISignalName" SG_ 360 IAPACmdEPSSts "IAPACmdEPSSts";
BA_ "LongName" SG_ 360 IAPACmdEPSSts "Advanced Park Assist Command Electric Power Steering Status";
BA_ "SysSignalName" SG_ 360 IAPACmdEPSSts "APACmdEPSSts";
BA_ "CompuMethodName" SG_ 360 IICBAD_20ms_Group13_Reserved2 "ICBAD_20ms_Group13_Reserved2";
BA_ "GenSigStartValue" SG_ 360 IICBAD_20ms_Group13_Reserved2 15;
BA_ "ISignalName" SG_ 360 IICBAD_20ms_Group13_Reserved2 "IICBAD_20ms_Group13_Reserved2";
BA_ "SysSignalName" SG_ 360 IICBAD_20ms_Group13_Reserved2 "ICBAD_20ms_Group13_Reserved2";
BA_ "CompuMethodName" SG_ 360 IICBAD_20ms_Group13_Reserved4 "ICBAD_20ms_Group13_Reserved4";
BA_ "GenSigStartValue" SG_ 360 IICBAD_20ms_Group13_Reserved4 15;
BA_ "ISignalName" SG_ 360 IICBAD_20ms_Group13_Reserved4 "IICBAD_20ms_Group13_Reserved4";
BA_ "SysSignalName" SG_ 360 IICBAD_20ms_Group13_Reserved4 "ICBAD_20ms_Group13_Reserved4";
BA_ "CompuMethodName" SG_ 360 IAPAShifterPosReqdV "APAShifterPosReqdV";
BA_ "ISignalName" SG_ 360 IAPAShifterPosReqdV "IAPAShifterPosReqdV";
BA_ "LongName" SG_ 360 IAPAShifterPosReqdV "Advanced Park Assist Shifter Position Requested Validity";
BA_ "SysSignalName" SG_ 360 IAPAShifterPosReqdV "APAShifterPosReqdV";
BA_ "CompuMethodName" SG_ 360 IAPASCUReqStsV "APASCUReqStsV";
BA_ "ISignalName" SG_ 360 IAPASCUReqStsV "IAPASCUReqStsV";
BA_ "LongName" SG_ 360 IAPASCUReqStsV "Advanced Park Assist Shifter Control Unit Request Status Validity";
BA_ "SysSignalName" SG_ 360 IAPASCUReqStsV "APASCUReqStsV";
BA_ "CompuMethodName" SG_ 360 IAPAF "APAF";
BA_ "ISignalName" SG_ 360 IAPAF "IAPAF";
BA_ "LongName" SG_ 360 IAPAF "Advanced Park Assist Failed";
BA_ "SysSignalName" SG_ 360 IAPAF "APAF";
BA_ "CompuMethodName" SG_ 360 IICBAD_20ms_Group13_Reserved3 "ICBAD_20ms_Group13_Reserved3";
BA_ "GenSigStartValue" SG_ 360 IICBAD_20ms_Group13_Reserved3 1;
BA_ "ISignalName" SG_ 360 IICBAD_20ms_Group13_Reserved3 "IICBAD_20ms_Group13_Reserved3";
BA_ "SysSignalName" SG_ 360 IICBAD_20ms_Group13_Reserved3 "ICBAD_20ms_Group13_Reserved3";
BA_ "CompuMethodName" SG_ 360 IICBAD_20ms_Group13_Reserved5 "ICBAD_20ms_Group13_Reserved5";
BA_ "GenSigStartValue" SG_ 360 IICBAD_20ms_Group13_Reserved5 255;
BA_ "ISignalName" SG_ 360 IICBAD_20ms_Group13_Reserved5 "IICBAD_20ms_Group13_Reserved5";
BA_ "SysSignalName" SG_ 360 IICBAD_20ms_Group13_Reserved5 "ICBAD_20ms_Group13_Reserved5";
BA_ "CompuMethodName" SG_ 1122 IACCStsForEdr "ACCStsForEdr";
BA_ "ISignalName" SG_ 1122 IACCStsForEdr "IACCStsForEdr";
BA_ "LongName" SG_ 1122 IACCStsForEdr "Adaptive Cruise Control Status For Edr";
BA_ "SysSignalName" SG_ 1122 IACCStsForEdr "ACCStsForEdr";
BA_ "CompuMethodName" SG_ 1122 ILDWStsForEdr "LDWStsForEdr";
BA_ "ISignalName" SG_ 1122 ILDWStsForEdr "ILDWStsForEdr";
BA_ "LongName" SG_ 1122 ILDWStsForEdr "Lane Departure Warning Status For Edr";
BA_ "SysSignalName" SG_ 1122 ILDWStsForEdr "LDWStsForEdr";
BA_ "CompuMethodName" SG_ 1122 IAEBStsForEdr "AEBStsForEdr";
BA_ "ISignalName" SG_ 1122 IAEBStsForEdr "IAEBStsForEdr";
BA_ "LongName" SG_ 1122 IAEBStsForEdr "Autonomous Emergency Braking Status For Edr";
BA_ "SysSignalName" SG_ 1122 IAEBStsForEdr "AEBStsForEdr";
BA_ "CompuMethodName" SG_ 1122 IESFStsForEdr "ESFStsForEdr";
BA_ "ISignalName" SG_ 1122 IESFStsForEdr "IESFStsForEdr";
BA_ "LongName" SG_ 1122 IESFStsForEdr "Emergency Steering Function Status For Edr";
BA_ "SysSignalName" SG_ 1122 IESFStsForEdr "ESFStsForEdr";
BA_ "CompuMethodName" SG_ 1122 ICSFStsForEdr "CSFStsForEdr";
BA_ "ISignalName" SG_ 1122 ICSFStsForEdr "ICSFStsForEdr";
BA_ "LongName" SG_ 1122 ICSFStsForEdr "Corrective Steering Function Status For Edr";
BA_ "SysSignalName" SG_ 1122 ICSFStsForEdr "CSFStsForEdr";
BA_ "CompuMethodName" SG_ 1122 IACSFCatgrB1StsForEdr "ACSFCatgrB1StsForEdr";
BA_ "ISignalName" SG_ 1122 IACSFCatgrB1StsForEdr "IACSFCatgrB1StsForEdr";
BA_ "LongName" SG_ 1122 IACSFCatgrB1StsForEdr "Automatically Commanded Steering Function Category B1 Status For Edr";
BA_ "SysSignalName" SG_ 1122 IACSFCatgrB1StsForEdr "ACSFCatgrB1StsForEdr";
BA_ "CompuMethodName" SG_ 1122 IACSFCatgrAStsForEdr "ACSFCatgrAStsForEdr";
BA_ "ISignalName" SG_ 1122 IACSFCatgrAStsForEdr "IACSFCatgrAStsForEdr";
BA_ "LongName" SG_ 1122 IACSFCatgrAStsForEdr "Automatically Commanded Steering Function Category A Status For Edr";
BA_ "SysSignalName" SG_ 1122 IACSFCatgrAStsForEdr "ACSFCatgrAStsForEdr";
BA_ "CompuMethodName" SG_ 1122 IACSFCatgrCStsForEdr "ACSFCatgrCStsForEdr";
BA_ "ISignalName" SG_ 1122 IACSFCatgrCStsForEdr "IACSFCatgrCStsForEdr";
BA_ "LongName" SG_ 1122 IACSFCatgrCStsForEdr "Automatically Commanded Steering Function Category C Status For Edr";
BA_ "SysSignalName" SG_ 1122 IACSFCatgrCStsForEdr "ACSFCatgrCStsForEdr";
BA_ "CompuMethodName" SG_ 1122 IACSFCatgrB2StsForEdr "ACSFCatgrB2StsForEdr";
BA_ "ISignalName" SG_ 1122 IACSFCatgrB2StsForEdr "IACSFCatgrB2StsForEdr";
BA_ "LongName" SG_ 1122 IACSFCatgrB2StsForEdr "Automatically Commanded Steering Function Category B2 Status For Edr";
BA_ "SysSignalName" SG_ 1122 IACSFCatgrB2StsForEdr "ACSFCatgrB2StsForEdr";
BA_ "CompuMethodName" SG_ 1122 IACSFCatgrEStsForEdr "ACSFCatgrEStsForEdr";
BA_ "ISignalName" SG_ 1122 IACSFCatgrEStsForEdr "IACSFCatgrEStsForEdr";
BA_ "LongName" SG_ 1122 IACSFCatgrEStsForEdr "Automatically Commanded Steering Function Category E Status For Edr";
BA_ "SysSignalName" SG_ 1122 IACSFCatgrEStsForEdr "ACSFCatgrEStsForEdr";
BA_ "CompuMethodName" SG_ 1122 IACSFCatgrDStsForEdr "ACSFCatgrDStsForEdr";
BA_ "ISignalName" SG_ 1122 IACSFCatgrDStsForEdr "IACSFCatgrDStsForEdr";
BA_ "LongName" SG_ 1122 IACSFCatgrDStsForEdr "Automatically Commanded Steering Function Category D Status For Edr";
BA_ "SysSignalName" SG_ 1122 IACSFCatgrDStsForEdr "ACSFCatgrDStsForEdr";
BA_ "CompuMethodName" SG_ 474 IICBAD_20ms_Group48_CRC "ICBAD_20ms_Group48_CRC";
BA_ "ISignalName" SG_ 474 IICBAD_20ms_Group48_CRC "IICBAD_20ms_Group48_CRC";
BA_ "SysSignalName" SG_ 474 IICBAD_20ms_Group48_CRC "ICBAD_20ms_Group48_CRC";
BA_ "CompuMethodName" SG_ 474 IICBAD_20ms_Group48_RC "ICBAD_20ms_Group48_RC";
BA_ "ISignalName" SG_ 474 IICBAD_20ms_Group48_RC "IICBAD_20ms_Group48_RC";
BA_ "SysSignalName" SG_ 474 IICBAD_20ms_Group48_RC "ICBAD_20ms_Group48_RC";
BA_ "CompuMethodName" SG_ 474 IICBAD_20ms_Group48_Reserved1 "ICBAD_20ms_Group48_Reserved1";
BA_ "GenSigStartValue" SG_ 474 IICBAD_20ms_Group48_Reserved1 1;
BA_ "ISignalName" SG_ 474 IICBAD_20ms_Group48_Reserved1 "IICBAD_20ms_Group48_Reserved1";
BA_ "SysSignalName" SG_ 474 IICBAD_20ms_Group48_Reserved1 "ICBAD_20ms_Group48_Reserved1";
BA_ "CompuMethodName" SG_ 474 ILDWLKARVsulznReq "LDWLKARVsulznReq";
BA_ "ISignalName" SG_ 474 ILDWLKARVsulznReq "ILDWLKARVsulznReq";
BA_ "LongName" SG_ 474 ILDWLKARVsulznReq "Lane Departure Warning Lane Keeping Assist Right Visualization Request";
BA_ "SysSignalName" SG_ 474 ILDWLKARVsulznReq "LDWLKARVsulznReq";
BA_ "CompuMethodName" SG_ 474 ILDWLKAVbnLvlReq "LDWLKAVbnLvlReq";
BA_ "ISignalName" SG_ 474 ILDWLKAVbnLvlReq "ILDWLKAVbnLvlReq";
BA_ "LongName" SG_ 474 ILDWLKAVbnLvlReq "Lane_Departure_Warning_Lane_Keeping_Assist_Vibration_Level_Request";
BA_ "SysSignalName" SG_ 474 ILDWLKAVbnLvlReq "LDWLKAVbnLvlReq";
BA_ "CompuMethodName" SG_ 474 ILDWSysFltSts "LDWSysFltSts";
BA_ "ISignalName" SG_ 474 ILDWSysFltSts "ILDWSysFltSts";
BA_ "LongName" SG_ 474 ILDWSysFltSts "Lane Departure Warning System Fault Status";
BA_ "SysSignalName" SG_ 474 ILDWSysFltSts "LDWSysFltSts";
BA_ "CompuMethodName" SG_ 474 ILDWSysSts "LDWSysSts";
BA_ "ISignalName" SG_ 474 ILDWSysSts "ILDWSysSts";
BA_ "LongName" SG_ 474 ILDWSysSts "Lane Departure Warning System Status";
BA_ "SysSignalName" SG_ 474 ILDWSysSts "LDWSysSts";
BA_ "CompuMethodName" SG_ 474 IICBAD_20ms_Group48_Reserved2 "ICBAD_20ms_Group48_Reserved2";
BA_ "GenSigStartValue" SG_ 474 IICBAD_20ms_Group48_Reserved2 255;
BA_ "ISignalName" SG_ 474 IICBAD_20ms_Group48_Reserved2 "IICBAD_20ms_Group48_Reserved2";
BA_ "SysSignalName" SG_ 474 IICBAD_20ms_Group48_Reserved2 "ICBAD_20ms_Group48_Reserved2";
BA_ "CompuMethodName" SG_ 474 IICBAD_20ms_Group48_Reserved3 "ICBAD_20ms_Group48_Reserved3";
BA_ "GenSigStartValue" SG_ 474 IICBAD_20ms_Group48_Reserved3 255;
BA_ "ISignalName" SG_ 474 IICBAD_20ms_Group48_Reserved3 "IICBAD_20ms_Group48_Reserved3";
BA_ "SysSignalName" SG_ 474 IICBAD_20ms_Group48_Reserved3 "ICBAD_20ms_Group48_Reserved3";
BA_ "CompuMethodName" SG_ 474 IICBAD_20ms_Group48_Reserved4 "ICBAD_20ms_Group48_Reserved4";
BA_ "GenSigStartValue" SG_ 474 IICBAD_20ms_Group48_Reserved4 31;
BA_ "ISignalName" SG_ 474 IICBAD_20ms_Group48_Reserved4 "IICBAD_20ms_Group48_Reserved4";
BA_ "SysSignalName" SG_ 474 IICBAD_20ms_Group48_Reserved4 "ICBAD_20ms_Group48_Reserved4";
BA_ "CompuMethodName" SG_ 474 ILDWLKALVsulznReq "LDWLKALVsulznReq";
BA_ "ISignalName" SG_ 474 ILDWLKALVsulznReq "ILDWLKALVsulznReq";
BA_ "LongName" SG_ 474 ILDWLKALVsulznReq "Lane Departure Warning Lane Keeping Assist Left Visualization Request";
BA_ "SysSignalName" SG_ 474 ILDWLKALVsulznReq "LDWLKALVsulznReq";
BA_ "CompuMethodName" SG_ 474 IICBAD_20ms_Group48_Reserved5 "ICBAD_20ms_Group48_Reserved5";
BA_ "GenSigStartValue" SG_ 474 IICBAD_20ms_Group48_Reserved5 255;
BA_ "ISignalName" SG_ 474 IICBAD_20ms_Group48_Reserved5 "IICBAD_20ms_Group48_Reserved5";
BA_ "SysSignalName" SG_ 474 IICBAD_20ms_Group48_Reserved5 "ICBAD_20ms_Group48_Reserved5";
BA_ "CompuMethodName" SG_ 474 IICBAD_20ms_Group48_Reserved6 "ICBAD_20ms_Group48_Reserved6";
BA_ "GenSigStartValue" SG_ 474 IICBAD_20ms_Group48_Reserved6 255;
BA_ "ISignalName" SG_ 474 IICBAD_20ms_Group48_Reserved6 "IICBAD_20ms_Group48_Reserved6";
BA_ "SysSignalName" SG_ 474 IICBAD_20ms_Group48_Reserved6 "ICBAD_20ms_Group48_Reserved6";
BA_ "CompuMethodName" SG_ 520 IRPShockDistL "RPShockDistL";
BA_ "ISignalName" SG_ 520 IRPShockDistL "IRPShockDistL";
BA_ "LongName" SG_ 520 IRPShockDistL "Distance To The Leading Edge Of The First Shock Feature Along The Rolling Path L";
BA_ "SysSignalName" SG_ 520 IRPShockDistL "RPShockDistL";
BA_ "CompuMethodName" SG_ 520 IRoadProfileShockLevelL "RoadProfileShockLevelL";
BA_ "ISignalName" SG_ 520 IRoadProfileShockLevelL "IRoadProfileShockLevelL";
BA_ "LongName" SG_ 520 IRoadProfileShockLevelL "Road Profile Shock Level L";
BA_ "SysSignalName" SG_ 520 IRoadProfileShockLevelL "RoadProfileShockLevelL";
BA_ "CompuMethodName" SG_ 520 IRPShockDistR "RPShockDistR";
BA_ "ISignalName" SG_ 520 IRPShockDistR "IRPShockDistR";
BA_ "LongName" SG_ 520 IRPShockDistR "Distance To The Leading Edge Of The First Shock Feature Along The Rolling Path R";
BA_ "SysSignalName" SG_ 520 IRPShockDistR "RPShockDistR";
BA_ "CompuMethodName" SG_ 520 IRoadProfileShockLevelR "RoadProfileShockLevelR";
BA_ "ISignalName" SG_ 520 IRoadProfileShockLevelR "IRoadProfileShockLevelR";
BA_ "LongName" SG_ 520 IRoadProfileShockLevelR "Road Profile Shock Level R";
BA_ "SysSignalName" SG_ 520 IRoadProfileShockLevelR "RoadProfileShockLevelR";
BA_ "CompuMethodName" SG_ 520 IRoadProfileShockHeightL "RoadProfileShockHeightL";
BA_ "ISignalName" SG_ 520 IRoadProfileShockHeightL "IRoadProfileShockHeightL";
BA_ "LongName" SG_ 520 IRoadProfileShockHeightL "The Height Of The Shock Feature L";
BA_ "SysSignalName" SG_ 520 IRoadProfileShockHeightL "RoadProfileShockHeightL";
BA_ "CompuMethodName" SG_ 520 IRoadProfileShockDetectedL "RoadProfileShockDetectedL";
BA_ "ISignalName" SG_ 520 IRoadProfileShockDetectedL "IRoadProfileShockDetectedL";
BA_ "LongName" SG_ 520 IRoadProfileShockDetectedL "An Indication That A Shock Feature Has Been Detected L";
BA_ "SysSignalName" SG_ 520 IRoadProfileShockDetectedL "RoadProfileShockDetectedL";
BA_ "CompuMethodName" SG_ 520 IRoadProfileShockHeightR "RoadProfileShockHeightR";
BA_ "ISignalName" SG_ 520 IRoadProfileShockHeightR "IRoadProfileShockHeightR";
BA_ "LongName" SG_ 520 IRoadProfileShockHeightR "The Height Of The Shock Feature R";
BA_ "SysSignalName" SG_ 520 IRoadProfileShockHeightR "RoadProfileShockHeightR";
BA_ "CompuMethodName" SG_ 520 IRoadProfileShockDetectedR "RoadProfileShockDetectedR";
BA_ "ISignalName" SG_ 520 IRoadProfileShockDetectedR "IRoadProfileShockDetectedR";
BA_ "LongName" SG_ 520 IRoadProfileShockDetectedR "An Indication That A Shock Feature Has Been Detected R";
BA_ "SysSignalName" SG_ 520 IRoadProfileShockDetectedR "RoadProfileShockDetectedR";
BA_ "CompuMethodName" SG_ 520 IRoadProfileShockConfidenceL "RoadProfileShockConfidenceL";
BA_ "ISignalName" SG_ 520 IRoadProfileShockConfidenceL "IRoadProfileShockConfidenceL";
BA_ "LongName" SG_ 520 IRoadProfileShockConfidenceL "The Confidence Of The Shock Detection L";
BA_ "SysSignalName" SG_ 520 IRoadProfileShockConfidenceL "RoadProfileShockConfidenceL";
BA_ "CompuMethodName" SG_ 520 IRoadProfileShockConfidenceR "RoadProfileShockConfidenceR";
BA_ "ISignalName" SG_ 520 IRoadProfileShockConfidenceR "IRoadProfileShockConfidenceR";
BA_ "LongName" SG_ 520 IRoadProfileShockConfidenceR "The Confidence Of The Shock Detection R";
BA_ "SysSignalName" SG_ 520 IRoadProfileShockConfidenceR "RoadProfileShockConfidenceR";
BA_ "CompuMethodName" SG_ 98 IICBAD_ZONE_10ms_Group20_CRC "ICBAD_ZONE_10ms_Group20_CRC";
BA_ "ISignalName" SG_ 98 IICBAD_ZONE_10ms_Group20_CRC "IICBAD_ZONE_10ms_Group20_CRC";
BA_ "SysSignalName" SG_ 98 IICBAD_ZONE_10ms_Group20_CRC "ICBAD_ZONE_10ms_Group20_CRC";
BA_ "CompuMethodName" SG_ 98 IICBAD_ZONE_10ms_Group20_RC "ICBAD_ZONE_10ms_Group20_RC";
BA_ "ISignalName" SG_ 98 IICBAD_ZONE_10ms_Group20_RC "IICBAD_ZONE_10ms_Group20_RC";
BA_ "SysSignalName" SG_ 98 IICBAD_ZONE_10ms_Group20_RC "ICBAD_ZONE_10ms_Group20_RC";
BA_ "CompuMethodName" SG_ 98 IICBAD_ZONE_10ms_Group20_Reserve0 "ICBAD_ZONE_10ms_Group20_Reserved1";
BA_ "GenSigStartValue" SG_ 98 IICBAD_ZONE_10ms_Group20_Reserve0 15;
BA_ "ISignalName" SG_ 98 IICBAD_ZONE_10ms_Group20_Reserve0 "IICBAD_ZONE_10ms_Group20_Reserved1";
BA_ "SysSignalName" SG_ 98 IICBAD_ZONE_10ms_Group20_Reserve0 "ICBAD_ZONE_10ms_Group20_Reserved1";
BA_ "SystemSignalLongSymbol" SG_ 98 IICBAD_ZONE_10ms_Group20_Reserve0 "IICBAD_ZONE_10ms_Group20_Reserved1";
BA_ "CompuMethodName" SG_ 98 IICBAD_ZONE_10ms_Group20_Reserve1 "ICBAD_ZONE_10ms_Group20_Reserved2";
BA_ "GenSigStartValue" SG_ 98 IICBAD_ZONE_10ms_Group20_Reserve1 255;
BA_ "ISignalName" SG_ 98 IICBAD_ZONE_10ms_Group20_Reserve1 "IICBAD_ZONE_10ms_Group20_Reserved2";
BA_ "SysSignalName" SG_ 98 IICBAD_ZONE_10ms_Group20_Reserve1 "ICBAD_ZONE_10ms_Group20_Reserved2";
BA_ "SystemSignalLongSymbol" SG_ 98 IICBAD_ZONE_10ms_Group20_Reserve1 "IICBAD_ZONE_10ms_Group20_Reserved2";
BA_ "CompuMethodName" SG_ 98 IICBAD_ZONE_10ms_Group20_Reserve2 "ICBAD_ZONE_10ms_Group20_Reserved3";
BA_ "GenSigStartValue" SG_ 98 IICBAD_ZONE_10ms_Group20_Reserve2 255;
BA_ "ISignalName" SG_ 98 IICBAD_ZONE_10ms_Group20_Reserve2 "IICBAD_ZONE_10ms_Group20_Reserved3";
BA_ "SysSignalName" SG_ 98 IICBAD_ZONE_10ms_Group20_Reserve2 "ICBAD_ZONE_10ms_Group20_Reserved3";
BA_ "SystemSignalLongSymbol" SG_ 98 IICBAD_ZONE_10ms_Group20_Reserve2 "IICBAD_ZONE_10ms_Group20_Reserved3";
BA_ "CompuMethodName" SG_ 98 ILKAToqReqValMax "LKAToqReqValMax";
BA_ "GenSigStartValue" SG_ 98 ILKAToqReqValMax 1024;
BA_ "ISignalName" SG_ 98 ILKAToqReqValMax "ILKAToqReqValMax";
BA_ "LongName" SG_ 98 ILKAToqReqValMax "Lane Keeping Assist Torque Request Value Maximum";
BA_ "SysSignalName" SG_ 98 ILKAToqReqValMax "LKAToqReqValMax";
BA_ "CompuMethodName" SG_ 98 IICBAD_ZONE_10ms_Group20_Reserve3 "ICBAD_ZONE_10ms_Group20_Reserved4";
BA_ "GenSigStartValue" SG_ 98 IICBAD_ZONE_10ms_Group20_Reserve3 1;
BA_ "ISignalName" SG_ 98 IICBAD_ZONE_10ms_Group20_Reserve3 "IICBAD_ZONE_10ms_Group20_Reserved4";
BA_ "SysSignalName" SG_ 98 IICBAD_ZONE_10ms_Group20_Reserve3 "ICBAD_ZONE_10ms_Group20_Reserved4";
BA_ "SystemSignalLongSymbol" SG_ 98 IICBAD_ZONE_10ms_Group20_Reserve3 "IICBAD_ZONE_10ms_Group20_Reserved4";
BA_ "CompuMethodName" SG_ 98 IICBAD_ZONE_10ms_Group20_Reserve4 "ICBAD_ZONE_10ms_Group20_Reserved5";
BA_ "GenSigStartValue" SG_ 98 IICBAD_ZONE_10ms_Group20_Reserve4 15;
BA_ "ISignalName" SG_ 98 IICBAD_ZONE_10ms_Group20_Reserve4 "IICBAD_ZONE_10ms_Group20_Reserved5";
BA_ "SysSignalName" SG_ 98 IICBAD_ZONE_10ms_Group20_Reserve4 "ICBAD_ZONE_10ms_Group20_Reserved5";
BA_ "SystemSignalLongSymbol" SG_ 98 IICBAD_ZONE_10ms_Group20_Reserve4 "IICBAD_ZONE_10ms_Group20_Reserved5";
BA_ "CompuMethodName" SG_ 98 ILKAToqReqValMin "LKAToqReqValMin";
BA_ "GenSigStartValue" SG_ 98 ILKAToqReqValMin 1024;
BA_ "ISignalName" SG_ 98 ILKAToqReqValMin "ILKAToqReqValMin";
BA_ "LongName" SG_ 98 ILKAToqReqValMin "Lane Keeping Assist Torque Request Value Minimum";
BA_ "SysSignalName" SG_ 98 ILKAToqReqValMin "LKAToqReqValMin";
BA_ "CompuMethodName" SG_ 98 IICBAD_ZONE_10ms_Group20_Reserve5 "ICBAD_ZONE_10ms_Group20_Reserved6";
BA_ "GenSigStartValue" SG_ 98 IICBAD_ZONE_10ms_Group20_Reserve5 31;
BA_ "ISignalName" SG_ 98 IICBAD_ZONE_10ms_Group20_Reserve5 "IICBAD_ZONE_10ms_Group20_Reserved6";
BA_ "SysSignalName" SG_ 98 IICBAD_ZONE_10ms_Group20_Reserve5 "ICBAD_ZONE_10ms_Group20_Reserved6";
BA_ "SystemSignalLongSymbol" SG_ 98 IICBAD_ZONE_10ms_Group20_Reserve5 "IICBAD_ZONE_10ms_Group20_Reserved6";
BA_ "CompuMethodName" SG_ 502 IIMCU_20ms_Group58_CRC "IMCU_20ms_Group58_CRC";
BA_ "ISignalName" SG_ 502 IIMCU_20ms_Group58_CRC "IIMCU_20ms_Group58_CRC";
BA_ "SysSignalName" SG_ 502 IIMCU_20ms_Group58_CRC "IMCU_20ms_Group58_CRC";
BA_ "CompuMethodName" SG_ 502 IIMCU_20ms_Group58_RC "IMCU_20ms_Group58_RC";
BA_ "ISignalName" SG_ 502 IIMCU_20ms_Group58_RC "IIMCU_20ms_Group58_RC";
BA_ "SysSignalName" SG_ 502 IIMCU_20ms_Group58_RC "IMCU_20ms_Group58_RC";
BA_ "CompuMethodName" SG_ 502 ICldBdyAdjReq "CldBdyAdjReq";
BA_ "ISignalName" SG_ 502 ICldBdyAdjReq "ICldBdyAdjReq";
BA_ "LongName" SG_ 502 ICldBdyAdjReq "Cloud Body Adjust Request";
BA_ "SysSignalName" SG_ 502 ICldBdyAdjReq "CldBdyAdjReq";
BA_ "CompuMethodName" SG_ 502 IVMCExtrmOutSts "VMCExtrmOutSts";
BA_ "GenSigStartValue" SG_ 502 IVMCExtrmOutSts 3;
BA_ "ISignalName" SG_ 502 IVMCExtrmOutSts "IVMCExtrmOutSts";
BA_ "LongName" SG_ 502 IVMCExtrmOutSts "VMC Extreme Driving Status";
BA_ "SysSignalName" SG_ 502 IVMCExtrmOutSts "VMCExtrmOutSts";
BA_ "CompuMethodName" SG_ 502 IVMCSusHghtLvlReqFA "VMCSusHghtLvlReqFA";
BA_ "ISignalName" SG_ 502 IVMCSusHghtLvlReqFA "IVMCSusHghtLvlReqFA";
BA_ "LongName" SG_ 502 IVMCSusHghtLvlReqFA "VMC Suspension Height Level Request Front Axle";
BA_ "SysSignalName" SG_ 502 IVMCSusHghtLvlReqFA "VMCSusHghtLvlReqFA";
BA_ "CompuMethodName" SG_ 502 IVMCASCActvnReq "VMCASCActvnReq";
BA_ "ISignalName" SG_ 502 IVMCASCActvnReq "IVMCASCActvnReq";
BA_ "LongName" SG_ 502 IVMCASCActvnReq "ASC activation request (for handshaking)";
BA_ "SysSignalName" SG_ 502 IVMCASCActvnReq "VMCASCActvnReq";
BA_ "CompuMethodName" SG_ 502 IIMCU_20ms_Group58_Reserved11 "IMCU_20ms_Group58_Reserved12";
BA_ "GenSigStartValue" SG_ 502 IIMCU_20ms_Group58_Reserved11 1;
BA_ "ISignalName" SG_ 502 IIMCU_20ms_Group58_Reserved11 "IIMCU_20ms_Group58_Reserved11";
BA_ "SysSignalName" SG_ 502 IIMCU_20ms_Group58_Reserved11 "IMCU_20ms_Group58_Reserved1";
BA_ "CompuMethodName" SG_ 502 IVMCSusHghtLvlReqLSide "VMCSusHghtLvlReqLSide";
BA_ "ISignalName" SG_ 502 IVMCSusHghtLvlReqLSide "IVMCSusHghtLvlReqLSide";
BA_ "LongName" SG_ 502 IVMCSusHghtLvlReqLSide "VMC Suspension Heght Level Request Left Side";
BA_ "SysSignalName" SG_ 502 IVMCSusHghtLvlReqLSide "VMCSusHghtLvlReqLSide";
BA_ "CompuMethodName" SG_ 502 IVMCSusHghtLvlReqRA "VMCSusHghtLvlReqRA";
BA_ "ISignalName" SG_ 502 IVMCSusHghtLvlReqRA "IVMCSusHghtLvlReqRA";
BA_ "LongName" SG_ 502 IVMCSusHghtLvlReqRA "MC Suspension Height Level Request Rear Axle";
BA_ "SysSignalName" SG_ 502 IVMCSusHghtLvlReqRA "VMCSusHghtLvlReqRA";
BA_ "CompuMethodName" SG_ 502 IIMCU_20ms_Group58_Reserved2 "IMCU_20ms_Group58_Reserved2";
BA_ "GenSigStartValue" SG_ 502 IIMCU_20ms_Group58_Reserved2 1;
BA_ "ISignalName" SG_ 502 IIMCU_20ms_Group58_Reserved2 "IIMCU_20ms_Group58_Reserved2";
BA_ "SysSignalName" SG_ 502 IIMCU_20ms_Group58_Reserved2 "IMCU_20ms_Group58_Reserved2";
BA_ "CompuMethodName" SG_ 502 IVMCLvlCtrlReqdTrgtLvl "VMCLvlCtrlReqdTrgtLvl";
BA_ "GenSigStartValue" SG_ 502 IVMCLvlCtrlReqdTrgtLvl 1;
BA_ "ISignalName" SG_ 502 IVMCLvlCtrlReqdTrgtLvl "IVMCLvlCtrlReqdTrgtLvl";
BA_ "LongName" SG_ 502 IVMCLvlCtrlReqdTrgtLvl "Level Control Requested Target Level";
BA_ "SysSignalName" SG_ 502 IVMCLvlCtrlReqdTrgtLvl "VMCLvlCtrlReqdTrgtLvl";
BA_ "CompuMethodName" SG_ 502 IIMCU_20ms_Group58_Reserved1 "IMCU_20ms_Group58_Reserved11";
BA_ "GenSigStartValue" SG_ 502 IIMCU_20ms_Group58_Reserved1 7;
BA_ "ISignalName" SG_ 502 IIMCU_20ms_Group58_Reserved1 "IIMCU_20ms_Group58_Reserved1";
BA_ "SysSignalName" SG_ 502 IIMCU_20ms_Group58_Reserved1 "IMCU_20ms_Group58_Reserved11";
BA_ "CompuMethodName" SG_ 502 IVMCSusHghtReqFR "VMCSusHghtReqFR";
BA_ "ISignalName" SG_ 502 IVMCSusHghtReqFR "IVMCSusHghtReqFR";
BA_ "LongName" SG_ 502 IVMCSusHghtReqFR "suspension height request FR";
BA_ "SysSignalName" SG_ 502 IVMCSusHghtReqFR "VMCSusHghtReqFR";
BA_ "CompuMethodName" SG_ 502 IVMCSusHghtReqFL "VMCSusHghtReqFL";
BA_ "ISignalName" SG_ 502 IVMCSusHghtReqFL "IVMCSusHghtReqFL";
BA_ "LongName" SG_ 502 IVMCSusHghtReqFL "suspension height request FL";
BA_ "SysSignalName" SG_ 502 IVMCSusHghtReqFL "VMCSusHghtReqFL";
BA_ "CompuMethodName" SG_ 502 IVMCSusHghtReqRR "VMCSusHghtReqRR";
BA_ "ISignalName" SG_ 502 IVMCSusHghtReqRR "IVMCSusHghtReqRR";
BA_ "LongName" SG_ 502 IVMCSusHghtReqRR "suspension height request RR";
BA_ "SysSignalName" SG_ 502 IVMCSusHghtReqRR "VMCSusHghtReqRR";
BA_ "CompuMethodName" SG_ 502 IVMCSusHghtReqRL "VMCSusHghtReqRL";
BA_ "ISignalName" SG_ 502 IVMCSusHghtReqRL "IVMCSusHghtReqRL";
BA_ "LongName" SG_ 502 IVMCSusHghtReqRL "suspension height request RL";
BA_ "SysSignalName" SG_ 502 IVMCSusHghtReqRL "VMCSusHghtReqRL";
BA_ "CompuMethodName" SG_ 502 IVMCSusHghtLvlReqRSide "VMCSusHghtLvlReqRSide";
BA_ "ISignalName" SG_ 502 IVMCSusHghtLvlReqRSide "IVMCSusHghtLvlReqRSide";
BA_ "LongName" SG_ 502 IVMCSusHghtLvlReqRSide "VMC Suspension Heght Level Request Right Side";
BA_ "SysSignalName" SG_ 502 IVMCSusHghtLvlReqRSide "VMCSusHghtLvlReqRSide";
BA_ "CompuMethodName" SG_ 502 IAddlVolmVlvReq "AddlVolmVlvReq";
BA_ "ISignalName" SG_ 502 IAddlVolmVlvReq "IAddlVolmVlvReq";
BA_ "LongName" SG_ 502 IAddlVolmVlvReq "Additional Volume Valve Request";
BA_ "SysSignalName" SG_ 502 IAddlVolmVlvReq "AddlVolmVlvReq";
BA_ "CompuMethodName" SG_ 502 IIMCU_20ms_Group58_Reserved4 "IMCU_20ms_Group58_Reserved4";
BA_ "GenSigStartValue" SG_ 502 IIMCU_20ms_Group58_Reserved4 255;
BA_ "ISignalName" SG_ 502 IIMCU_20ms_Group58_Reserved4 "IIMCU_20ms_Group58_Reserved4";
BA_ "SysSignalName" SG_ 502 IIMCU_20ms_Group58_Reserved4 "IMCU_20ms_Group58_Reserved4";
BA_ "CompuMethodName" SG_ 502 IIMCU_20ms_Group58_Reserved5 "IMCU_20ms_Group58_Reserved5";
BA_ "GenSigStartValue" SG_ 502 IIMCU_20ms_Group58_Reserved5 255;
BA_ "ISignalName" SG_ 502 IIMCU_20ms_Group58_Reserved5 "IIMCU_20ms_Group58_Reserved5";
BA_ "SysSignalName" SG_ 502 IIMCU_20ms_Group58_Reserved5 "IMCU_20ms_Group58_Reserved5";
BA_ "CompuMethodName" SG_ 502 IIMCU_20ms_Group58_Reserved6 "IMCU_20ms_Group58_Reserved6";
BA_ "GenSigStartValue" SG_ 502 IIMCU_20ms_Group58_Reserved6 255;
BA_ "ISignalName" SG_ 502 IIMCU_20ms_Group58_Reserved6 "IIMCU_20ms_Group58_Reserved6";
BA_ "SysSignalName" SG_ 502 IIMCU_20ms_Group58_Reserved6 "IMCU_20ms_Group58_Reserved6";
BA_ "CompuMethodName" SG_ 502 IIMCU_20ms_Group58_Reserved7 "IMCU_20ms_Group58_Reserved7";
BA_ "GenSigStartValue" SG_ 502 IIMCU_20ms_Group58_Reserved7 255;
BA_ "ISignalName" SG_ 502 IIMCU_20ms_Group58_Reserved7 "IIMCU_20ms_Group58_Reserved7";
BA_ "SysSignalName" SG_ 502 IIMCU_20ms_Group58_Reserved7 "IMCU_20ms_Group58_Reserved7";
BA_ "CompuMethodName" SG_ 502 IIMCU_20ms_Group58_Reserved8 "IMCU_20ms_Group58_Reserved8";
BA_ "GenSigStartValue" SG_ 502 IIMCU_20ms_Group58_Reserved8 255;
BA_ "ISignalName" SG_ 502 IIMCU_20ms_Group58_Reserved8 "IIMCU_20ms_Group58_Reserved8";
BA_ "SysSignalName" SG_ 502 IIMCU_20ms_Group58_Reserved8 "IMCU_20ms_Group58_Reserved8";
BA_ "CompuMethodName" SG_ 502 IIMCU_20ms_Group58_Reserved9 "IMCU_20ms_Group58_Reserved9";
BA_ "GenSigStartValue" SG_ 502 IIMCU_20ms_Group58_Reserved9 255;
BA_ "ISignalName" SG_ 502 IIMCU_20ms_Group58_Reserved9 "IIMCU_20ms_Group58_Reserved9";
BA_ "SysSignalName" SG_ 502 IIMCU_20ms_Group58_Reserved9 "IMCU_20ms_Group58_Reserved9";

VAL_ 822 IFrntWhlStrgMotToqV 0 "FrntWhlStrgMotToqV_0_Valid" 1 "FrntWhlStrgMotToqV_1_Invalid";
VAL_ 430 IEPSAPASts 0 "EPSAPASts_0_Inhibit" 1 "EPSAPASts_1_Available" 2 "EPSAPASts_2_Active" 3 "EPSAPASts_3_Abort" 4 "EPSAPASts_4_ReplyForControl" 5 "EPSAPASts_5_NrcdActive" 6 "EPSAPASts_6_AdasActive" 7 "EPSAPASts_7_Failure";
VAL_ 430 IEPSAPAInh 0 "EPSAPAInh_0_Normal_Operation" 1 "EPSAPAInh_1_Over_Speed" 2 "EPSAPAInh_2_Driver_Interference" 4 "EPSAPAInh_4_Abnormal_CAN_input" 8 "EPSAPAInh_8_Excess_Angle_Deviation" 16 "EPSAPAInh_16_EPS_failure";
VAL_ 1252 IEPS_NM_BSMtoRMS_CHCANFD 0 "EPS_NM_BSMtoRMS_CHCANFD_0_False" 1 "EPS_NM_BSMtoRMS_CHCANFD_1_True";
VAL_ 1252 IEPS_NM_PBSMtoRMS_CHCANFD 0 "EPS_NM_PBSMtoRMS_CHCANFD_0_False" 1 "EPS_NM_PBSMtoRMS_CHCANFD_1_True";
VAL_ 1252 IEPS_NM_RMStoNOS_CHCANFD 0 "EPS_NM_RMStoNOS_CHCANFD_0_False" 1 "EPS_NM_RMStoNOS_CHCANFD_1_True";
VAL_ 1252 IEPS_NM_RSStoNOS_CHCANFD 0 "EPS_NM_RSStoNOS_CHCANFD_0_False" 1 "EPS_NM_RSStoNOS_CHCANFD_1_True";
VAL_ 1252 IEPS_NM_RSStoRMS_CHCANFD 0 "EPS_NM_RSStoRMS_CHCANFD_0_False" 1 "EPS_NM_RSStoRMS_CHCANFD_1_True";
VAL_ 1252 IEPS_NM_NOStoRMS_CHCANFD 0 "EPS_NM_NOStoRMS_CHCANFD_0_False" 1 "EPS_NM_NOStoRMS_CHCANFD_1_True";
VAL_ 1252 IEPS_NM_NOSSta_CHCANFD 0 "EPS_NM_NOSSta_CHCANFD_0_False" 1 "EPS_NM_NOSSta_CHCANFD_1_True";
VAL_ 1252 IEPS_NM_RMSSta_CHCANFD 0 "EPS_NM_RMSSta_CHCANFD_0_False" 1 "EPS_NM_RMSSta_CHCANFD_1_True";
VAL_ 1252 IEPS_NWI_CHCANFD 0 "EPS_NWI_CHCANFD_0_NoWakeNetworkSource";
VAL_ 1252 IEPS_NOI_CHCANFD 0 "EPS_NOI_CHCANFD_0_NoRequest" 65535 "EPS_NOI_CHCANFD_65535_AllNetworkOperationActive";
VAL_ 697 IEPStoIPD_Rsrv01 0 "EPStoIPD_Rsrv01_0_Reserved" 1 "EPStoIPD_Rsrv01_1_Reserved" 2 "EPStoIPD_Rsrv01_2_Reserved" 3 "EPStoIPD_Rsrv01_3_Reserved";
VAL_ 697 IEPStoIPD_Rsrv02 0 "EPStoIPD_Rsrv01_0_Reserved" 1 "EPStoIPD_Rsrv01_1_Reserved" 2 "EPStoIPD_Rsrv01_2_Reserved" 3 "EPStoIPD_Rsrv01_3_Reserved";
VAL_ 697 IEPStoIPD_Rsrv03 0 "EPStoIPD_Rsrv01_0_Reserved" 1 "EPStoIPD_Rsrv01_1_Reserved" 2 "EPStoIPD_Rsrv01_2_Reserved" 3 "EPStoIPD_Rsrv01_3_Reserved";
VAL_ 956 IPilotSysMsg 0 "PilotSysMsg_0_No_display" 1 "PilotSysMsg_1_ACC_Active" 2 "PilotSysMsg_2_ACC_Exit" 3 "PilotSysMsg_3_LCC_Active" 4 "PilotSysMsg_4_LCC_UpgradeFromACC" 5 "PilotSysMsg_5_LCC_DegradationToACC" 6 "PilotSysMsg_6_LCC_Exit" 7 "PilotSysMsg_7_NOA_Active" 8 "PilotSysMsg_8_NOA_Upgrade" 9 "PilotSysMsg_9_NOA_DegradationToLCC" 10 "PilotSysMsg_10_NOA_DegradationToACC" 11 "PilotSysMsg_11_NOA_Exit" 12 "PilotSysMsg_12_Reserved" 13 "PilotSysMsg_13_Reserved" 14 "PilotSysMsg_14_Reserved" 15 "PilotSysMsg_15_Reserved";
VAL_ 956 ITLRMsgReq 0 "TLRMsgReq_0_NoDisplay" 1 "TLRMsgReq_1_Countdown" 2 "TLRMsgReq_2_Reserved" 3 "TLRMsgReq_3_Reserved";
VAL_ 956 ILane0_location 0 "Lane0_location_0_Left" 1 "Lane0_location_1_Right" 2 "Lane0_location_2_NextLeft" 3 "Lane0_location_3_NextRight";
VAL_ 956 ITLRSysSts 0 "TLRSysSts_0_Off" 1 "TLRSysSts_1_StandBy" 2 "TLRSysSts_2_Active" 3 "TLRSysSts_3_Error";
VAL_ 956 ILane1_location 0 "Lane1_location_0_Left" 1 "Lane1_location_1_Right" 2 "Lane1_location_2_NextLeft" 3 "Lane1_location_3_NextRight";
VAL_ 956 ITrgtSpdSrcSts_IPD 0 "TrgtSpdSrcSts_IPD_0_Undefined" 1 "TrgtSpdSrcSts_IPD_1_Camera" 2 "TrgtSpdSrcSts_IPD_2_Navigation" 3 "TrgtSpdSrcSts_IPD_3_Fault";
VAL_ 956 ISLIFWrnngMdResp 0 "SLIFWrnngMdResp_0__Unavailable" 1 "SLIFWrnngMdResp_1__Off" 2 "SLIFWrnngMdResp_2__Visual" 3 "SLIFWrnngMdResp_3___Audible";
VAL_ 956 ITLRWarning 0 "TLRWarning_0_NoRequest" 1 "TLRWarning_1_GreenLightStartAlert_lvl1" 2 "TLRWarning_2_GreenLightStartAlert_lvl2" 3 "TLRWarning_3_RedLightRunAlert_lvl1" 4 "TLRWarning_4_RedLightRunAlert_lvl2" 5 "TLRWarning_5_Reserved" 6 "TLRWarning_6_Reserved";
VAL_ 956 ITLRMdSwDspCmd 0 "TLRMdSwDspCmd_0_unavailable" 1 "TLRMdSwDspCmd_1_TLR_on" 2 "TLRMdSwDspCmd_2_TLR_off" 3 "TLRMdSwDspCmd_3_TLR_alert_off" 4 "TLRMdSwDspCmd_4_TLR_alert_on" 5 "TLRMdSwDspCmd_5_Reserved" 6 "TLRMdSwDspCmd_6_Reserved";
VAL_ 956 ISLIFAudWrnng_IPD 0 "SLIFAudWrnng_IPD_0__False" 1 "SLIFAudWrnng_IPD_1__True";
VAL_ 956 ISLIFUpdtIndResp_IPD 0 "SLIFUpdtIndResp_IPD_0__Off" 1 "SLIFUpdtIndResp_IPD_1__On";
VAL_ 956 ISLIFUpdtInd_IPD 0 "SLIFUpdtInd_IPD_0__False" 1 "SLIFUpdtInd_IPD_1__True";
VAL_ 956 ICCSpdVcCmdCnfm 0 "CCSpdVcCmdCnfm_0_NoResponse" 1 "CCSpdVcCmdCnfm_1_SpeedIsConfirmed" 2 "CCSpdVcCmdCnfm_2_DistanceIsConfirmed" 3 "CCSpdVcCmdCnfm_3_NotInTheRange" 4 "CCSpdVcCmdCnfm_4_AlreadyInMaximunRange" 5 "CCSpdVcCmdCnfm_5_AlreadyInMinimumRange" 6 "CCSpdVcCmdCnfm_6_ACCisActived" 7 "CCSpdVcCmdCnfm_7_ACCisDeactived";
VAL_ 163 ILKAReqToqSts 0 "LKAReqToqSts_0_no_request" 1 "LKAReqToqSts_1_torque_request_HO" 2 "LKAReqToqSts_2_reserved_HF" 3 "LKAReqToqSts_3_reserved";
VAL_ 163 ILKAReqAngSts 0 "LKAReqAngSts_0_LKAReq_AngSts_0_no_request" 1 "LKAReqAngSts_1_Angle_request_HO" 2 "LKAReqAngSts_2_angle_request_HF" 3 "LKAReqAngSts_3_EMA";
VAL_ 318 ILDrvnWhlRotlRstOcd 0 "LDrvnWhlRotlRstOcd_0_False" 1 "LDrvnWhlRotlRstOcd_1_True";
VAL_ 318 ILDrvnWhlRotlDistV 0 "LDrvnWhlRotlDistV_0_Valid" 1 "LDrvnWhlRotlDistV_1_Invalid";
VAL_ 318 IRDrvnWhlRotlRstOcd 0 "RDrvnWhlRotlRstOcd_0_False" 1 "RDrvnWhlRotlRstOcd_1_True";
VAL_ 318 IRDrvnWhlRotlDistV 0 "RDrvnWhlRotlDistV_0_Valid" 1 "RDrvnWhlRotlDistV_1_Invalid";
VAL_ 319 ILNonDrvnWhlRotlRstOcd 0 "LNonDrvnWhlRotlRstOcd_0_False" 1 "LNonDrvnWhlRotlRstOcd_1_True";
VAL_ 319 ILNonDrvnWhlRotlDistV 0 "LNonDrvnWhlRotlDistV_0_Valid" 1 "LNonDrvnWhlRotlDistV_1_Invalid";
VAL_ 319 IRNonDrvnWhlRotlRstOcd 0 "RNonDrvnWhlRotlRstOcd_0_False" 1 "RNonDrvnWhlRotlRstOcd_1_True";
VAL_ 319 IRNonDrvnWhlRotlDistV 0 "RNonDrvnWhlRotlDistV_0_Valid" 1 "RNonDrvnWhlRotlDistV_1_Invalid";
VAL_ 423 IHDCSysSts 0 "HDCSysSts_0_Normal" 1 "HDCSysSts_1_Enabled" 2 "HDCSysSts_2_Active" 3 "HDCSysSts_3_Failed" 4 "HDCSysSts_4_Temporarily_Inhibited";
VAL_ 423 IABSIO 0 "ABSIO_0_False" 1 "ABSIO_1_True";
VAL_ 423 IVSESysA 0 "VSESysA_0_False" 1 "VSESysA_1_True";
VAL_ 423 IBrkSysYlwBrkTlltReq 0 "BrkSysYlwBrkTlltReq_0_False" 1 "BrkSysYlwBrkTlltReq_1_True";
VAL_ 423 IVSESts 0 "VSESts_0_Inactive" 1 "VSESts_1_Active" 2 "VSESts_2_Fault" 3 "VSESts_3_WarmingUp" 4 "VSESts_4_NotReady";
VAL_ 423 IVSEMd 0 "VSEMd_0_Off" 1 "VSEMd_1_Normal" 2 "VSEMd_2_Competitive" 3 "VSEMd_3_TraceMd";
VAL_ 423 IMultColBrkEnbA 0 "MultColBrkEnbA_0_NoActive" 1 "MultColBrkEnbA_1_Active";
VAL_ 423 IEBDFaultSt 0 "EBDFaultSt_0_False" 1 "EBDFaultSt_1_True";
VAL_ 423 ITCSOpngSts 0 "TCSOpngSts_0_Inactive" 1 "TCSOpngSts_1_Active" 2 "TCSOpngSts_2_Fault";
VAL_ 423 ITCSOpngMd 0 "TCSOpngMd_0_Off" 1 "TCSOpngMd_1_Normal" 2 "TCSOpngMd_2_OffRoad" 3 "TCSOpngMd_3_TraceMd";
VAL_ 423 IBrkSysHillStAstAvlbl 0 "BrkSysHillStAstAvlbl_0_False" 1 "BrkSysHillStAstAvlbl_1_True";
VAL_ 423 IRgtvBrkFnFltSts 0 "RgtvBrkFnFltSts_0_False" 1 "RgtvBrkFnFltSts_1_True";
VAL_ 423 IMSRF 0 "MSRF_0_False" 1 "MSRF_1_True";
VAL_ 423 IAutoHoldSysSts 0 "AutoHoldSysSts_0_Off" 1 "AutoHoldSysSts_1_intervention" 2 "AutoHoldSysSts_2_standby" 3 "AutoHoldSysSts_3_error";
VAL_ 423 IAutoHoldMsg 0 "AutoHoldMsg_0_reserved" 1 "AutoHoldMsg_1_Seat_belt_not_fastend" 2 "AutoHoldMsg_2_Press_brake_pedal" 3 "AutoHoldMsg_3_Autohold_standby" 4 "AutoHoldMsg_4_Autohold_Off" 5 "AutoHoldMsg_5_Autohold_release" 6 "AutoHoldMsg_6_reserved" 7 "AutoHoldMsg_7_reserved";
VAL_ 423 IEBDA 0 "EBDA_0_Notactive" 1 "EBDA_1_Active";
VAL_ 423 IRgtvBrkFnSts 0 "RgtvBrkFnSts_0_On" 1 "RgtvBrkFnSts_1_Off";
VAL_ 423 ITCSEnbd 0 "TCSEnbd_0_False" 1 "TCSEnbd_1_True";
VAL_ 423 IHBAActiveSt 0 "HBAActiveSt_0_False" 1 "HBAActiveSt_1_True";
VAL_ 423 ITCSA 0 "TCSA_0_False" 1 "TCSA_1_True";
VAL_ 423 IEnDragToqRducnA 0 "EnDragToqRducnA_0_False" 1 "EnDragToqRducnA_1_True";
VAL_ 423 IABSF 0 "ABSF_0_False" 1 "ABSF_1_True";
VAL_ 423 IABSA 0 "ABSA_0_False" 1 "ABSA_1_True";
VAL_ 423 IHBAValidSt 0 "HBAValidSt_0_Valid" 1 "HBAValidSt_1_Invalid";
VAL_ 423 IMSRA 0 "MSRA_0_MSRActive" 1 "MSRA_1_MSRInactive";
VAL_ 423 IEmgcBrkAV 0 "EmgcBrkAV_0_Valid" 1 "EmgcBrkAV_1_Invalid";
VAL_ 423 IEmgcBrkA 0 "EmgcBrkA_0_False" 1 "EmgcBrkA_1_True";
VAL_ 423 IBrkSysRedBrkTlltReq 0 "BrkSysRedBrkTlltReq_0_False" 1 "BrkSysRedBrkTlltReq_1_True";
VAL_ 423 IBrkSysHillStAstSts 0 "BrkSysHillStAstSts_0_Inactive" 1 "BrkSysHillStAstSts_1_Brake_Pressure_Hold" 2 "BrkSysHillStAstSts_2_Normal_Pressure_Decay" 3 "BrkSysHillStAstSts_3_Drive_Off_Pressure_Decay" 4 "BrkSysHillStAstSts_4_Reserved" 5 "BrkSysHillStAstSts_5_Reserved" 6 "BrkSysHillStAstSts_6_Reserved" 7 "BrkSysHillStAstSts_7_Reserved";
VAL_ 423 IAVHSigPdlSts 0 "AVHSigPdlSts_0_Off" 1 "AVHSigPdlSts_1_On" 2 "AVHSigPdlSts_2_error" 3 "AVHSigPdlSts_3_reserved";
VAL_ 423 IAutoHoldMdSts 0 "AutoHoldMdSts_0_Off" 1 "AutoHoldMdSts_1_normal" 2 "AutoHoldMdSts_2_classic" 3 "AutoHoldMdSts_3_error";
VAL_ 423 ISoftSpSysSts 0 "SoftSpSysSts_0_normal" 1 "SoftSpSysSts_1_Enabled" 2 "SoftSpSysSts_2_Active" 3 "SoftSpSysSts_3_Failed";
VAL_ 423 IMulColBrkA 0 "MulColBrkA_0_NoActive" 1 "MulColBrkA_1_Active";
VAL_ 423 IMulColBrkAvlblySts 0 "MulColBrkAvlblySts_0_False" 1 "MulColBrkAvlblySts_1_True";
VAL_ 342 IEPBSts 0 "EPBSts_0_Released" 1 "EPBSts_1_Applied" 2 "EPBSts_2_Fault";
VAL_ 342 IEPBAppcnSts 0 "EPBAppcnSts_0_Unknown" 1 "EPBAppcnSts_1_ParkBrakeApplied" 2 "EPBAppcnSts_2_ParkBrakeReleased" 3 "EPBAppcnSts_3_ParkBrakeApplicationInProgress";
VAL_ 342 IEPBCCCanclReqd 0 "EPBCCCanclReqd_0_False" 1 "EPBCCCanclReqd_1_True";
VAL_ 342 IEPBSysStsIndReq 0 "EPBSysStsIndReq_0_No_Indication" 1 "EPBSysStsIndReq_1_Continuous_Indication" 2 "EPBSysStsIndReq_2_Flash_Rate_1_Indication" 3 "EPBSysStsIndReq_3_Flash_Rate_2_Indication";
VAL_ 342 IEPBSwSts 0 "EPBSwSts_0_NotActive" 1 "EPBSwSts_1_Release" 2 "EPBSwSts_2_Apply";
VAL_ 342 IEPBAvlblySts 0 "EPBAvlblySts_0_Unavailable_Not_Failed" 1 "EPBAvlblySts_1_Available_Not_Failed" 2 "EPBAvlblySts_2_Unavailable_Failed_Applied" 3 "EPBAvlblySts_3_Unavailable_Failed_Released" 4 "EPBAvlblySts_4_Unavailable_Failed_other" 5 "EPBAvlblySts_5_Unused_and_Reserved_1" 6 "EPBAvlblySts_6_Unused_and_Reserved_2" 7 "EPBAvlblySts_7_Unused_and_Reserved_3";
VAL_ 342 IEPBSysAudWrnngReq 0 "EPBSysAudWrnngReq_0_Off" 1 "EPBSysAudWrnngReq_1_Warning_1" 2 "EPBSysAudWrnngReq_2_Warning_2";
VAL_ 342 IEPBSwStsV 0 "EPBSwStsV_0_Valid" 1 "EPBSwStsV_1_Invalid";
VAL_ 342 IEPBSysWrnngIndReq 0 "EPBSysWrnngIndReq_0_No_Indication" 1 "EPBSysWrnngIndReq_1_Continuous_Indication" 2 "EPBSysWrnngIndReq_2_Flash_Rate_1_Indication" 3 "EPBSysWrnngIndReq_3_Flash_Rate_2_Indication";
VAL_ 342 IEPBSysDspMsgReq 0 "EPBSysDspMsgReq_0_Off" 1 "EPBSysDspMsgReq_1_Message_1" 2 "EPBSysDspMsgReq_2_Message_2" 3 "EPBSysDspMsgReq_3_Message_3" 4 "EPBSysDspMsgReq_4_Message_4" 5 "EPBSysDspMsgReq_5_Message_5" 6 "EPBSysDspMsgReq_6_Message_6" 7 "EPBSysDspMsgReq_7_Message_7";
VAL_ 342 IEPBAPAAvlbl 0 "EPBAPAAvlbl_0_Unavailable" 1 "EPBAPAAvlbl_1_available";
VAL_ 342 IEPBFlrSts 0 "EPBFlrSts_0_NoErrorInEpb" 1 "EPBFlrSts_1_ErrorInEpb";
VAL_ 342 IChSysSecyBrkAxleToqValV 0 "ChSysSecyBrkAxleToqValV_0_valid" 1 "ChSysSecyBrkAxleToqValV_1_invalid";
VAL_ 342 IChSysTrBrkAxleToqValV 0 "ChSysTrBrkAxleToqValV_0_valid" 1 "ChSysTrBrkAxleToqValV_1_invalid";
VAL_ 329 ILDrvnWhlRotlDircn 0 "LDrvnWhlRotlDircn_0_Unknown" 1 "LDrvnWhlRotlDircn_1_Forward" 2 "LDrvnWhlRotlDircn_2_Backward" 3 "LDrvnWhlRotlDircn_3_Initial_Invalid";
VAL_ 329 IRDrvnWhlRotlDircn 0 "RDrvnWhlRotlDircn_0_Unknown" 1 "RDrvnWhlRotlDircn_1_Forward" 2 "RDrvnWhlRotlDircn_2_Backward" 3 "RDrvnWhlRotlDircn_3_Initial_Invalid";
VAL_ 329 IWhlGndVelRDrvnV 0 "WhlGndVelRDrvnV_0_Valid" 1 "WhlGndVelRDrvnV_1_Invalid";
VAL_ 329 IWhlGndVelLDrvnV 0 "WhlGndVelLDrvnV_0_Valid" 1 "WhlGndVelLDrvnV_1_Invalid";
VAL_ 329 IRDrvnWhlRotlDircnSdslSts 0 "RDrvnWhlRotlDircnSdslSts_0_Notstandstill" 1 "RDrvnWhlRotlDircnSdslSts_1_Standstill";
VAL_ 329 ILDrvnWhlRotlDircnSdslSts 0 "LDrvnWhlRotlDircnSdslSts_0_Notstandstill" 1 "LDrvnWhlRotlDircnSdslSts_1_Standstill";
VAL_ 329 IChSysTotBrkAxleToqValV 0 "ChSysTotBrkAxleToqValV_0_Valid" 1 "ChSysTotBrkAxleToqValV_1_Invalid";
VAL_ 425 IVehSpdAvgNonDrvnV 0 "VehSpdAvgNonDrvnV_0_Valid" 1 "VehSpdAvgNonDrvnV_1_Invalid";
VAL_ 425 IVehSpdAvgV 0 "VehSpdAvgV_0_Valid" 1 "VehSpdAvgV_1_Invalid";
VAL_ 425 IVehSpdAvgDrvnV 0 "VehSpdAvgDrvnV_0_Valid" 1 "VehSpdAvgDrvnV_1_Invalid";
VAL_ 425 IVehSpdAvgDrvnSrc 0 "VehSpdAvgDrvnSrc_0_Transmission_Output_Speed" 1 "VehSpdAvgDrvnSrc_1_Wheel_Speed";
VAL_ 339 IRNonDrvnWhlRotlDircn 0 "RNonDrvnWhlRotlDircn_0_Unknown" 1 "RNonDrvnWhlRotlDircn_1_Forward" 2 "RNonDrvnWhlRotlDircn_2_Backward" 3 "RNonDrvnWhlRotlDircn_3_Initial_Invalid";
VAL_ 339 ILNonDrvnWhlRotlDircn 0 "LNonDrvnWhlRotlDircn_0_Unknown" 1 "LNonDrvnWhlRotlDircn_1_Forward" 2 "LNonDrvnWhlRotlDircn_2_Backward" 3 "LNonDrvnWhlRotlDircn_3_Initial_Invalid";
VAL_ 339 IWhlGndVelRNonDrvnV 0 "WhlGndVelRNonDrvnV_0_Valid" 1 "WhlGndVelRNonDrvnV_1_Invalid";
VAL_ 339 IWhlGndVelLNonDrvnV 0 "WhlGndVelLNonDrvnV_0_Valid" 1 "WhlGndVelLNonDrvnV_1_Invalid";
VAL_ 339 IRNonDrvnWhlRotlDircnSdslSts 0 "RNonDrvnWhlRotlDircnSdslSts_0_Notstandstill" 1 "RNonDrvnWhlRotlDircnSdslSts_1_Standstill";
VAL_ 339 ILNonDrvnWhlRotlDircnSdslSts 0 "LNonDrvnWhlRotlDircnSdslSts_0_Notstandstill" 1 "LNonDrvnWhlRotlDircnSdslSts_1_Standstill";
VAL_ 1272 IIBS_NM_BSMtoRMS_CHCANFD 0 "IBS_NM_BSMtoRMS_CHCANFD_0_False" 1 "IBS_NM_BSMtoRMS_CHCANFD_1_True";
VAL_ 1272 IIBS_NM_PBSMtoRMS_CHCANFD 0 "IBS_NM_PBSMtoRMS_CHCANFD_0_False" 1 "IBS_NM_PBSMtoRMS_CHCANFD_1_True";
VAL_ 1272 IIBS_NM_RMStoNOS_CHCANFD 0 "IBS_NM_RMStoNOS_CHCANFD_0_False" 1 "IBS_NM_RMStoNOS_CHCANFD_1_True";
VAL_ 1272 IIBS_NM_RSStoNOS_CHCANFD 0 "IBS_NM_RSStoNOS_CHCANFD_0_False" 1 "IBS_NM_RSStoNOS_CHCANFD_1_True";
VAL_ 1272 IIBS_NM_RSStoRMS_CHCANFD 0 "IBS_NM_RSStoRMS_CHCANFD_0_False" 1 "IBS_NM_RSStoRMS_CHCANFD_1_True";
VAL_ 1272 IIBS_NM_NOStoRMS_CHCANFD 0 "IBS_NM_NOStoRMS_CHCANFD_0_False" 1 "IBS_NM_NOStoRMS_CHCANFD_1_True";
VAL_ 1272 IIBS_NM_NOSSta_CHCANFD 0 "IBS_NM_NOSSta_CHCANFD_0_False" 1 "IBS_NM_NOSSta_CHCANFD_1_True";
VAL_ 1272 IIBS_NM_RMSSta_CHCANFD 0 "IBS_NM_RMSSta_CHCANFD_0_False" 1 "IBS_NM_RMSSta_CHCANFD_1_True";
VAL_ 1272 IIBS_NWI_CHCANFD 0 "IBS_NWI_CHCANFD_0_NoWakeNetworkSource" 1 "IBS_NWI_CHCANFD_1_IBS_NWI_1_PowerModeIsRun_crank" 2 "IBS_NWI_CHCANFD_2_IBS_NWI_2_EpbApplySwitchActive";
VAL_ 1272 IIBS_NOI_CHCANFD 0 "IBS_NOI_CHCANFD_0_NoRequest" 65535 "IBS_NOI_CHCANFD_65535_AllNetworkOperationActive";
VAL_ 1272 IIBS_NKI_CHCANFD 0 "IBS_NKI_CHCANFD_0_NoRequest" 1 "IBS_NKI_CHCANFD_1_PowerModeIsNonOFF";
VAL_ 507 IEPBAppcnSts_M 0 "EPBAppcnSts_M_0_ParkApplied" 1 "EPBAppcnSts_M_1_Released" 2 "EPBAppcnSts_M_2_Unknown" 3 "EPBAppcnSts_M_3_HoldApplied" 4 "EPBAppcnSts_M_4_CompletelyReleased" 5 "EPBAppcnSts_M_5_Applying" 6 "EPBAppcnSts_M_6_Releasing";
VAL_ 507 IBrkBstFnSts 0 "BrkBstFnSts_0_normal" 1 "BrkBstFnSts_1_pedal_feelling_error" 2 "BrkBstFnSts_2_partial_fallback" 3 "BrkBstFnSts_3_fallback" 4 "BrkBstFnSts_4_selfcheck";
VAL_ 917 IAIPiloTIntervQuit 0 "AIPiloTIntervQuit_0_No_display" 1 "AIPiloTIntervQuit_1_SystemFailed_AIPilotIsQuit" 2 "AIPiloTIntervQuit_2_TrunkOpen_TakeOverPlease" 3 "AIPiloTIntervQuit_3_SeatbeltReleased_AIPilotIsQuit" 4 "AIPiloTIntervQuit_4_EPBSwitchPressed_AIPilotIsQuit" 5 "AIPiloTIntervQuit_5_DoorsOpen_AIPilotIsQuit" 6 "AIPiloTIntervQuit_6_HoodOpen_AIPilotIsQuit" 7 "AIPiloTIntervQuit_7_please_parking_the_vehicle" 8 "AIPiloTIntervQuit_8_VehicleSpeedIsTooFast_AIPilotIsQuit" 9 "AIPiloTIntervQuit_9_ESP_active_AIPilotIsQuit" 10 "AIPiloTIntervQuit_10_ParkingTimeOver15min_AIPilotIsQuit" 11 "AIPiloTIntervQuit_11_AIPilotIsQuit" 12 "AIPiloTIntervQuit_12_Camera_is_blocked_ACCIsQuit" 13 "AIPiloTIntervQuit_13_The_end_of_NOA" 14 "AIPiloTIntervQuit_14_NOA_is_not_available_at_the_front_XXM" 15 "AIPiloTIntervQuit_15_NOA_is_finished_at_the_front_XXM" 16 "AIPiloTIntervQuit_16_Waiting_for_timeout__AIPilotIsQuit" 17 "AIPiloTIntervQuit_17_Too_long_time_to_step_on_the_accelerator_TakeOverPlease" 18 "AIPiloTIntervQuit_18_ESP_is_closed_TakeOverPlease" 19 "AIPiloTIntervQuit_19_Reserved_1" 20 "AIPiloTIntervQuit_20_Reserved_2" 21 "AIPiloTIntervQuit_21_Reserved_3" 22 "AIPiloTIntervQuit_22_Reserved_4" 23 "AIPiloTIntervQuit_23_Reserved_5" 24 "AIPiloTIntervQuit_24_Reserved_6" 25 "AIPiloTIntervQuit_25_Reserved_7" 26 "AIPiloTIntervQuit_26_Reserved_8" 27 "AIPiloTIntervQuit_27_Reserved_9" 28 "AIPiloTIntervQuit_28_Reserved_10" 29 "AIPiloTIntervQuit_29_Reserved_11" 30 "AIPiloTIntervQuit_30_Reserved_12" 31 "AIPiloTIntervQuit_31_Reserved_13" 32 "AIPiloTIntervQuit_32_Reserved_14" 33 "AIPiloTIntervQuit_33_Reserved_15" 34 "AIPiloTIntervQuit_34_Reserved_16" 35 "AIPiloTIntervQuit_35_Reserved_17" 36 "AIPiloTIntervQuit_36_Reserved_18" 37 "AIPiloTIntervQuit_37_Reserved_19" 38 "AIPiloTIntervQuit_38_Reserved_20" 39 "AIPiloTIntervQuit_39_Reserved_21" 40 "AIPiloTIntervQuit_40_Reserved_22" 41 "AIPiloTIntervQuit_41_Reserved_23" 42 "AIPiloTIntervQuit_42_Reserved_24" 43 "AIPiloTIntervQuit_43_Reserved_25" 44 "AIPiloTIntervQuit_44_Reserved_26" 45 "AIPiloTIntervQuit_45_Reserved_27" 46 "AIPiloTIntervQuit_46_Reserved_28" 47 "AIPiloTIntervQuit_47_Reserved_29" 48 "AIPiloTIntervQuit_48_Reserved_30" 49 "AIPiloTIntervQuit_49_Reserved_31" 50 "AIPiloTIntervQuit_50_Reserved_32" 51 "AIPiloTIntervQuit_51_Reserved_33" 52 "AIPiloTIntervQuit_52_Reserved_34" 53 "AIPiloTIntervQuit_53_Reserved_35" 54 "AIPiloTIntervQuit_54_Reserved_36" 55 "AIPiloTIntervQuit_55_Reserved_37" 56 "AIPiloTIntervQuit_56_Reserved_38" 57 "AIPiloTIntervQuit_57_Reserved_39" 58 "AIPiloTIntervQuit_58_Reserved_40" 59 "AIPiloTIntervQuit_59_Reserved_41" 60 "AIPiloTIntervQuit_60_Reserved_42" 61 "AIPiloTIntervQuit_61_Reserved_43" 62 "AIPiloTIntervQuit_62_Reserved_44" 63 "AIPiloTIntervQuit_63_Reserved_45";
VAL_ 917 IAIParkngDsp 0 "AIParkngDsp_0_NoDisplay" 1 "AIParkngDsp_1_BrakePedalStepDownArtificiallyAutoParkingHasExitedTakeOverPlease" 2 "AIParkngDsp_2_SelfTestTimeoutAutoParkingHasExitedTakeOverPlease" 3 "AIParkngDsp_3_FlameoutTimeoutAutoParkingHasExitedTakeOverPlease" 4 "AIParkngDsp_4_BluetoothdisconnectedAutoParkingHasExitedTakeOverPlease" 5 "AIParkngDsp_5_NotUseOnPublicRoadMapBuildingfailed" 6 "AIParkngDsp_6_ElectricLockCompleted" 7 "AIParkngDsp_7_FailedLockCarAutoParkingHasExitedTakeOverPlease" 8 "AIParkngDsp_8_VehicleSelfTestFailureAutoParkingHasExitedTakeOverPlease" 9 "AIParkngDsp_9_FlameoutFailedAutoParkingHasExitedTakeOverPlease" 10 "AIParkngDsp_10_AutoParkingHasStopped" 11 "AIParkngDsp_11_FailedToCancelAutoParkingTryAgainOrTakeOver" 12 "AIParkngDsp_12_SystemFailedAutoParkingCancel" 13 "AIParkngDsp_13_NotUseOnPublicRoadTakeOverPlease" 14 "AIParkngDsp_14_WirelessCharginglocationIsSelectedpleaseslowdownandstop" 15 "AIParkngDsp_15_SystemTimeOutAutoParkingCancel" 16 "AIParkngDsp_16_AutoParkingIsSuspendedPressButtonToContiuneOrSelectAPPToContinueParkingIn" 17 "AIParkngDsp_17_SteeringWheelInterveneAutoParkingCancel" 18 "AIParkngDsp_18_PressContinueToPointAtWLC" 19 "AIParkngDsp_19_SheftLevelInterveneAutoParkingCancel" 20 "AIParkngDsp_20_CanntPointAtWLC" 21 "AIParkngDsp_21_ParkingDistanceIsBeyondLimitationAutoParkingCancel" 22 "AIParkngDsp_22_NumberOfAdjustmentsExceedsLimitationAutoParkingCancel" 23 "AIParkngDsp_23_AutoParkingRespondsToAccelerationDecelerateTobelow15kph" 24 "AIParkngDsp_24_VehicleSpeedHighAutoParkingCancel" 25 "AIParkngDsp_25_DoorsOrHoodOrTrunklidIsOpenMapBuildingfailed" 26 "AIParkngDsp_26_TrunkIsOpenAutoParkingCancel" 27 "AIParkngDsp_27_HoodIsOpenAutoParkingCancel" 28 "AIParkngDsp_28_AParkingSpaceIsFoundSelectOneOrStopPlease" 29 "AIParkngDsp_29_PressToStartParkingOrGetOffInPGearToSelectAPPOrKeyToContinueParkingIn" 30 "AIParkngDsp_30_Pleasebackupafterarrivingyourspace" 31 "AIParkngDsp_31_SearchForParkingSpaceSurroundingEnvironmentCarefully" 33 "AIParkngDsp_33_AutoParkingFinish" 34 "AIParkngDsp_34_AutoParkingCancelTakeOverPlease" 35 "AIParkngDsp_35_VehicleSpeedExceedDrivingRangeTakeOverPlease" 36 "AIParkngDsp_36_IntelligentParkingSurroundingEnvironmentCarefully" 37 "AIParkngDsp_37_ReleaseBrakePedalAndAutoParkingContinue" 38 "AIParkngDsp_38_ChargerIschargingAutoParkingCancel" 39 "AIParkngDsp_39_ExteriorMirrorIsAbnormalTakeOverPlease" 40 "AIParkngDsp_40_CameraIsBlockedTakeOverPlease" 41 "AIParkngDsp_41_EnvironmentIsAbnormalTakeOverPlease" 42 "AIParkngDsp_42_EncounteringObstaclesParkingIsSuspended" 43 "AIParkngDsp_43_ReversingtoolongMapBuildingfailed" 44 "AIParkngDsp_44_DoorIsOpen" 45 "AIParkngDsp_45_PowerButtonIsPressedAutoParkingCancel" 46 "AIParkngDsp_46_ObstaclesInParkingSpaceChangeOnePlease" 47 "AIParkngDsp_47_VehicleSpeedHigh" 48 "AIParkngDsp_48_SteeringWheelInterveneAutoParkingPaused" 49 "AIParkngDsp_49_PressToStartParkingOrGetOffToSelectAPPOrKeyToContinueParkingIn" 50 "AIParkngDsp_50_ObstaclesInTheTargetParkingSpaceRemove" 51 "AIParkngDsp_51_NotinspaceMapBuildingfailed" 52 "AIParkngDsp_52_PleaseHangPGear" 53 "AIParkngDsp_53_WaitMapFileUpgradeCompleted" 54 "AIParkngDsp_54_WaitAppUpgradeCompleted" 55 "AIParkngDsp_55_VehicleIsStart" 56 "AIParkngDsp_56_AirbagIsExpandedAutoParkingUnavailable" 57 "AIParkngDsp_57_TirePresureInormalAutoParkingUnavailable" 58 "AIParkngDsp_58_Aboutoparkinthespace" 59 "AIParkngDsp_59_MemoryparkingBeAwareOfSurroundings" 60 "AIParkngDsp_60_LongPressAndSearching" 61 "AIParkngDsp_61_AbnormalEnvironmentFunctionExit" 62 "AIParkngDsp_62_SteeringWheelTurnedArtificiallyTakeOver" 63 "AIParkngDsp_63_VehicleSlowDownAndStopPleaseReleaseAcceleratorPedal" 64 "AIParkngDsp_64_LongPressButtonToContinueParkIn" 65 "AIParkngDsp_65_APFunctionPausingPressTheButtonToContinue" 66 "AIParkngDsp_66_APFunctionPausingPressContinueButtonToContinue" 67 "AIParkngDsp_67_ExecutingRemoteCarMovingPleaseSetWheelAngleAndMovingDirecitonThenLongPressTheButton" 68 "AIParkngDsp_68_PassTheCrossingBeAwareOfSurroundings" 69 "AIParkngDsp_69_RemoteCarMovingPausingLongPressTheButtonToContinue" 70 "AIParkngDsp_70_Thedecelerationbeltisbumpy" 71 "AIParkngDsp_71_ParkingInFailedDoUWantToContinueSearchParkingSpace" 72 "AIParkngDsp_72_ThereAreXXXLeftPathLearningDistance" 73 "AIParkngDsp_73_NoLeftPathLearningDistanceAndOutOfLimitLearningFailed" 74 "AIParkngDsp_74_Turnleftahead" 75 "AIParkngDsp_75_Turnrightahead" 76 "AIParkngDsp_76_IntelligentMapEstablishing" 77 "AIParkngDsp_77_IntelligentMapEstablished" 78 "AIParkngDsp_78_LocalizationInitialized" 79 "AIParkngDsp_79_LocationInitializingPleaseDriveTheCarToStartPointOfEstablishedPath" 80 "AIParkngDsp_80_ParkingToThatDirectionIsDifficultPleaseChangeAnotherDirection" 81 "AIParkngDsp_81_CarDeviatingThePlanningPathPleaseSetCarStraight" 82 "AIParkngDsp_82_AvoidingBeAwareOfSurroundings" 83 "AIParkngDsp_83_FunctionDegradedToManulDrivingBecauseOfSystemTimeOut" 84 "AIParkngDsp_84_AVPParkingLotExistingAroundTheDestination" 85 "AIParkngDsp_85_PleaseDriveTheCarToSpecifiedLocation" 86 "AIParkngDsp_86_SloplargeMapBuildingfailed" 87 "AIParkngDsp_87_CarHasArrivedAtTheMeetingSpotPleaseTakeOver" 88 "AIParkngDsp_88_UnableToPassPleaseTakeOver" 89 "AIParkngDsp_89_MapVersionMismatchingPleaseUpdateMapVersion" 90 "AIParkngDsp_90_PathLocationLostPleaseTakeOver" 91 "AIParkngDsp_91_VideoChannelOccupiedCannotOpen360SorroundedView" 92 "AIParkngDsp_92_ConnectionDisconnectPleaseTakeOver" 93 "AIParkngDsp_93_IfSettingCarSpotFirstStopTheCarAndThenSettingTheSpot" 94 "AIParkngDsp_94_MapDownloading" 95 "AIParkngDsp_95_PositioningInitializationFailed" 96 "AIParkngDsp_96_PleasePutIntoGearPAndGetDownWithTheMobilePhoneToConnectTheVehicle" 97 "AIParkngDsp_97_PleasePutIntoGearPAndGetDownWithTheMobilePhoneToConnectTheVehicle" 98 "AIParkngDsp_98_AVPFunctionFinished" 99 "AIParkngDsp_99_AVPFunctionFailed" 100 "AIParkngDsp_100_SystemFailedMapBuildingfailed" 101 "AIParkngDsp_101_TheInternetDisable" 102 "AIParkngDsp_102_TimeOut" 103 "AIParkngDsp_103_MapDownloadingfailed" 104 "AIParkngDsp_104_Pleasemakesurethatyouhaveparkedinthestoragespaceandkeepthevehiclestationaryfor3seconds" 105 "AIParkngDsp_105_IntelligentMapBuildingfailed" 106 "AIParkngDsp_106_SpeedistoohighMapBuildingfailed" 107 "AIParkngDsp_107_DistancetooshortMapBuildingfailed" 108 "AIParkngDsp_108_DrivingonrampBeAwareOfSurroundings" 109 "AIParkngDsp_109_Theparkinginmaphasfailledandtheparkingoutmaphassucceed" 110 "AIParkngDsp_110_Themapisbeinggeneratedtheusercanleavenormallyandthepowerwillbeautomaticallypoweredoffaftercompletion" 111 "AIParkngDsp_111_PlschangeOthSpc" 113 "AIParkngDsp_113_ThereAre50LeftPathLearningDistance" 114 "AIParkngDsp_114_ThereAre10LeftPathLearningDistance" 115 "AIParkngDsp_115_SlowdowntobelowXXXPlease" 116 "AIParkngDsp_116_SloplargePleaseTakeOver" 117 "AIParkngDsp_117_BrakesteponPleaseTakeOver" 118 "AIParkngDsp_118_BeltRleasePleaseTakeOver" 119 "AIParkngDsp_119_TargetspacenotavailableOtherspaceforyou" 120 "AIParkngDsp_120_PayattentiontoenvironmentPlease" 121 "AIParkngDsp_121_PayattentiontoThecollisionriskPlease" 122 "AIParkngDsp_122_Reserved" 123 "AIParkngDsp_123_Reserved" 124 "AIParkngDsp_124_Reserved" 125 "AIParkngDsp_125_Reserved" 126 "AIParkngDsp_126_Reserved" 127 "AIParkngDsp_127_Reserved" 128 "AIParkngDsp_128_ParkoutByourselfPlease" 129 "AIParkngDsp_129_DistanceTooShort" 130 "AIParkngDsp_130_ExcessiveSlop" 131 "AIParkngDsp_131_LackOfFeatures" 132 "AIParkngDsp_132_DistanceTooLong" 133 "AIParkngDsp_133_TimeTooLong" 134 "AIParkngDsp_134_VerificationTooLong" 135 "AIParkngDsp_135_WriteInFailure" 136 "AIParkngDsp_136_Reserved" 137 "AIParkngDsp_137_Reserved" 138 "AIParkngDsp_138_Reserved" 139 "AIParkngDsp_139_Reserved" 140 "AIParkngDsp_140_Reserved" 141 "AIParkngDsp_141_Reserved" 142 "AIParkngDsp_142_Reserved" 143 "AIParkngDsp_143_Reserved" 144 "AIParkngDsp_144_DnagerTakeoverPlease" 145 "AIParkngDsp_145_DnagerTakeoverPlease" 146 "AIParkngDsp_146_ReverseParkingPayattentiontoenvironmentPlease" 147 "AIParkngDsp_147_ApplybrakeClickstartreversing" 148 "AIParkngDsp_148_trailisabouttoendTakeoverPlease" 149 "AIParkngDsp_149_trailisendTakeoverPlease" 150 "AIParkngDsp_150_FunctionexitTakeoverPlease" 151 "AIParkngDsp_151_PayattentiontoenvironmentPlease" 152 "AIParkngDsp_152_Completedhorizontaledging" 153 "AIParkngDsp_153_PleasePushPedel" 154 "AIParkngDsp_154_UnexpectedOperationInsideVehicle" 155 "AIParkngDsp_155_Reserved" 156 "AIParkngDsp_156_Reserved" 157 "AIParkngDsp_157_Reserved" 158 "AIParkngDsp_158_Reserved" 159 "AIParkngDsp_159_Reserved" 160 "AIParkngDsp_160_Reserved" 161 "AIParkngDsp_161_Reserved" 162 "AIParkngDsp_162_Reserved" 163 "AIParkngDsp_163_Reserved" 164 "AIParkngDsp_164_Reserved" 165 "AIParkngDsp_165_Reserved" 166 "AIParkngDsp_166_Reserved" 167 "AIParkngDsp_167_Reserved" 168 "AIParkngDsp_168_Reserved" 169 "AIParkngDsp_169_Reserved" 170 "AIParkngDsp_170_Reserved" 171 "AIParkngDsp_171_Reserved" 172 "AIParkngDsp_172_Reserved" 173 "AIParkngDsp_173_Reserved" 174 "AIParkngDsp_174_Reserved" 175 "AIParkngDsp_175_Reserved" 176 "AIParkngDsp_176_Reserved" 177 "AIParkngDsp_177_Reserved" 178 "AIParkngDsp_178_Reserved" 179 "AIParkngDsp_179_Reserved" 180 "AIParkngDsp_180_Reserved" 181 "AIParkngDsp_181_Reserved" 182 "AIParkngDsp_182_Reserved" 183 "AIParkngDsp_183_Reserved" 184 "AIParkngDsp_184_Reserved" 185 "AIParkngDsp_185_Reserved" 186 "AIParkngDsp_186_Reserved" 187 "AIParkngDsp_187_Reserved" 188 "AIParkngDsp_188_Reserved" 189 "AIParkngDsp_189_Reserved" 190 "AIParkngDsp_190_Reserved" 191 "AIParkngDsp_191_Reserved" 192 "AIParkngDsp_192_Reserved" 193 "AIParkngDsp_193_Reserved" 194 "AIParkngDsp_194_Reserved" 195 "AIParkngDsp_195_Reserved" 196 "AIParkngDsp_196_Reserved" 197 "AIParkngDsp_197_Reserved" 198 "AIParkngDsp_198_Reserved" 199 "AIParkngDsp_199_Reserved" 200 "AIParkngDsp_200_Reserved" 201 "AIParkngDsp_201_Reserved" 202 "AIParkngDsp_202_Reserved" 203 "AIParkngDsp_203_Reserved" 204 "AIParkngDsp_204_Reserved" 205 "AIParkngDsp_205_Reserved" 206 "AIParkngDsp_206_Reserved" 207 "AIParkngDsp_207_Reserved" 208 "AIParkngDsp_208_Reserved" 209 "AIParkngDsp_209_Reserved" 210 "AIParkngDsp_210_Reserved" 211 "AIParkngDsp_211_Reserved" 212 "AIParkngDsp_212_Reserved" 213 "AIParkngDsp_213_Reserved" 214 "AIParkngDsp_214_Reserved" 215 "AIParkngDsp_215_Reserved" 216 "AIParkngDsp_216_Reserved" 217 "AIParkngDsp_217_Reserved" 218 "AIParkngDsp_218_Reserved" 219 "AIParkngDsp_219_Reserved" 220 "AIParkngDsp_220_Reserved" 221 "AIParkngDsp_221_Reserved" 222 "AIParkngDsp_222_Reserved" 223 "AIParkngDsp_223_Reserved" 224 "AIParkngDsp_224_Reserved" 225 "AIParkngDsp_225_Reserved" 226 "AIParkngDsp_226_Reserved" 227 "AIParkngDsp_227_Reserved" 228 "AIParkngDsp_228_Reserved" 229 "AIParkngDsp_229_Reserved" 230 "AIParkngDsp_230_Reserved" 231 "AIParkngDsp_231_Reserved" 232 "AIParkngDsp_232_Reserved" 233 "AIParkngDsp_233_Reserved" 234 "AIParkngDsp_234_Reserved" 235 "AIParkngDsp_235_Reserved" 236 "AIParkngDsp_236_Reserved" 237 "AIParkngDsp_237_Reserved" 238 "AIParkngDsp_238_Reserved" 239 "AIParkngDsp_239_Reserved" 240 "AIParkngDsp_240_Reserved" 241 "AIParkngDsp_241_Reserved" 242 "AIParkngDsp_242_Reserved" 243 "AIParkngDsp_243_Reserved" 244 "AIParkngDsp_244_Reserved" 245 "AIParkngDsp_245_Reserved" 246 "AIParkngDsp_246_Reserved" 247 "AIParkngDsp_247_Reserved" 248 "AIParkngDsp_248_Reserved" 249 "AIParkngDsp_249_Reserved" 250 "AIParkngDsp_250_Reserved" 251 "AIParkngDsp_251_Reserved" 252 "AIParkngDsp_252_Reserved" 253 "AIParkngDsp_253_Reserved" 254 "AIParkngDsp_254_Reserved" 255 "AIParkngDsp_255_Reserved";
VAL_ 917 IAIParkngSts 0 "AIParkngSts_0_Off" 1 "AIParkngSts_1_ParkingDisable" 2 "AIParkngSts_2_ParkingJudging" 3 "AIParkngSts_3_SummonDisable" 4 "AIParkngSts_4_SummonJudging" 5 "AIParkngSts_5_MapBuilding" 6 "AIParkngSts_6_MapBuilding_APA_DrivingConfirming" 7 "AIParkngSts_7_LineMoving" 8 "AIParkngSts_8_LineMovePausing" 9 "AIParkngSts_9_MapBuilding_APA_ParkingInParking_ficm" 10 "AIParkngSts_10_ManualParkingInScanningParking_ficm" 11 "AIParkngSts_11_ManualParkingInScanningParking_ipk" 12 "AIParkngSts_12_LineMoveActive" 13 "AIParkngSts_13_SummonPausing" 14 "AIParkngSts_14_LVP_APA_Pausing" 15 "AIParkngSts_15_RememberParkingOut" 16 "AIParkngSts_16_Reserved" 17 "AIParkngSts_17_RememberParkOutPausing" 18 "AIParkngSts_18_LVP_ParkingInScanning_ficm" 19 "AIParkngSts_19_ParkingInScanning_app" 20 "AIParkngSts_20_ParkingInScanPausing" 21 "AIParkngSts_21_ParkingInSpaceConfirming" 22 "AIParkngSts_22_ParkingInParking_ficm" 23 "AIParkngSts_23_ParkingInParking_app" 24 "AIParkngSts_24_ParkingInParkPausing" 25 "AIParkngSts_25_ParkingOutParking_ficm" 26 "AIParkngSts_26_ParkingOutParking_app" 27 "AIParkngSts_27_ParkingOutPausing" 28 "AIParkngSts_28_ParkingOutParking_key" 29 "AIParkngSts_29_ParkingInParking_key" 30 "AIParkngSts_30_LVP_RemenberParkInSpaceConfirming" 31 "AIParkngSts_31_OtherFunctionConflictg" 32 "AIParkngSts_33_Reserved" 33 "AIParkngSts_33_AVPMapLoading" 34 "AIParkngSts_34_AVPCrusing" 35 "AIParkngSts_35_AVParkNaving" 36 "AIParkngSts_36_AVParkNavPausing" 37 "AIParkngSts_37_AVParking" 38 "AIParkngSts_38_AVParkPausing" 39 "AIParkngSts_39_AVParkingout" 40 "AIParkngSts_40_AVParkoutPausing" 41 "AIParkngSts_41_APAParkoutPreactive" 42 "AIParkngSts_42_Suspend" 43 "AIParkngSts_43_ManualDrivingConfirming" 44 "AIParkngSts_44_ConfirmingMobile" 45 "AIParkngSts_45_ParkingStandby" 46 "AIParkngSts_46_LVPStandby_confirming" 47 "AIParkngSts_47_MapBuilding_APA_ParkingDisable" 48 "AIParkngSts_48_Reserved" 49 "AIParkngSts_49_ManualParkingInScanningParking_wlc" 50 "AIParkngSts_50_MapBuilding_APA_Suspend" 51 "AIParkngSts_51_MapSuspend" 52 "AIParkngSts_52_MapBuilding_APA_ParkingJudging" 53 "AIParkngSts_53_LVPStandby" 54 "AIParkngSts_54_LVPPreactive" 55 "AIParkngSts_55_LVPParkingPreactive" 56 "AIParkngSts_56_LVPCruising" 57 "AIParkngSts_57_LVP_APA_Suspend" 58 "AIParkngSts_58_LVPComplete" 59 "AIParkngSts_59_MapBuildingComplete" 60 "AIParkngSts_60_MapBuildingFailure" 61 "AIParkngSts_61_MapCheck" 62 "AIParkngSts_62_MapBuilding_APA_ParkingInParkPausing" 63 "AIParkngSts_63_ParkoutMapBuildingComplete" 64 "AIParkngSts_64_ParkoutMapBuilding" 65 "AIParkngSts_65_LineMoveFailure" 66 "AIParkngSts_66_LVPFailure" 67 "AIParkngSts_67_AVP_Park_in_Preactive" 68 "AIParkngSts_68_AVP_Park_out_Preactive" 69 "AIParkngSts_69_LVP_APA_ParkingIN" 70 "AIParkngSts_70_RPAParkingoutPreactive" 71 "AIParkngSts_71_ParkingoutPausing_RPA" 72 "AIParkngSts_72_ManualConfirming_Key" 73 "AIParkngSts_73_ParkingInParkPausing_key" 74 "AIParkngSts_74_Suspend_key" 75 "AIParkngSts_75_OneClickAdjust" 76 "AIParkngSts_76_OneClickAdjustPausing" 77 "AIParkngSts_77_FunctionFailed" 78 "AIParkngSts_78_Reserved" 79 "AIParkngSts_79_Reserved" 80 "AIParkngSts_80_Reserved" 81 "AIParkngSts_81_Reserved" 82 "AIParkngSts_82_Reserved" 83 "AIParkngSts_83_Reserved" 84 "AIParkngSts_84_Reserved" 85 "AIParkngSts_85_Reserved" 86 "AIParkngSts_86_Reserved" 87 "AIParkngSts_87_Reserved" 88 "AIParkngSts_88_Reserved" 89 "AIParkngSts_89_Reserved" 90 "AIParkngSts_90_Reserved" 91 "AIParkngSts_91_Reserved" 92 "AIParkngSts_92_Reserved" 93 "AIParkngSts_93_Reserved" 94 "AIParkngSts_94_Reserved" 95 "AIParkngSts_95_Reserved" 96 "AIParkngSts_96_Reserved" 97 "AIParkngSts_97_Reserved" 98 "AIParkngSts_98_Reserved" 99 "AIParkngSts_99_Reserved" 100 "AIParkngSts_100_Reserved" 101 "AIParkngSts_101_Reserved" 102 "AIParkngSts_102_Reserved" 103 "AIParkngSts_103_Reserved" 104 "AIParkngSts_104_Reserved" 105 "AIParkngSts_105_Reserved" 106 "AIParkngSts_106_Reserved" 107 "AIParkngSts_107_Reserved" 108 "AIParkngSts_108_Reserved" 109 "AIParkngSts_109_Reserved" 110 "AIParkngSts_110_Reserved" 111 "AIParkngSts_111_Reserved" 112 "AIParkngSts_112_Reserved" 113 "AIParkngSts_113_Reserved" 114 "AIParkngSts_114_Reserved" 115 "AIParkngSts_115_Reserved" 116 "AIParkngSts_116_Reserved" 117 "AIParkngSts_117_Reserved" 118 "AIParkngSts_118_Reserved" 119 "AIParkngSts_119_Reserved" 120 "AIParkngSts_120_Reserved" 121 "AIParkngSts_121_Reserved" 122 "AIParkngSts_122_Reserved" 123 "AIParkngSts_123_Reserved" 124 "AIParkngSts_124_Reserved" 125 "AIParkngSts_125_Reserved" 126 "AIParkngSts_126_Reserved" 127 "AIParkngSts_127_Reserved" 128 "AIParkngSts_128_Reserved" 129 "AIParkngSts_129_Reserved" 130 "AIParkngSts_130_Reserved" 131 "AIParkngSts_131_Reserved" 132 "AIParkngSts_132_Reserved" 133 "AIParkngSts_133_Reserved" 134 "AIParkngSts_134_Reserved" 135 "AIParkngSts_135_Reserved" 136 "AIParkngSts_136_Reserved" 137 "AIParkngSts_137_Reserved" 138 "AIParkngSts_138_Reserved" 139 "AIParkngSts_139_Reserved" 140 "AIParkngSts_140_Reserved" 141 "AIParkngSts_141_Reserved" 142 "AIParkngSts_142_Reserved" 143 "AIParkngSts_143_Reserved" 144 "AIParkngSts_144_Reserved" 145 "AIParkngSts_145_Reserved" 146 "AIParkngSts_146_Reserved" 147 "AIParkngSts_147_Reserved" 148 "AIParkngSts_148_Reserved" 149 "AIParkngSts_149_Reserved" 150 "AIParkngSts_150_Reserved" 151 "AIParkngSts_151_Reserved" 152 "AIParkngSts_152_Reserved" 153 "AIParkngSts_153_Reserved" 154 "AIParkngSts_154_Reserved" 155 "AIParkngSts_155_Reserved" 156 "AIParkngSts_156_Reserved" 157 "AIParkngSts_157_Reserved" 158 "AIParkngSts_158_Reserved" 159 "AIParkngSts_159_Reserved" 160 "AIParkngSts_160_Reserved" 161 "AIParkngSts_161_Reserved" 162 "AIParkngSts_162_Reserved" 163 "AIParkngSts_163_Reserved" 164 "AIParkngSts_164_Reserved" 165 "AIParkngSts_165_Reserved" 166 "AIParkngSts_166_Reserved" 167 "AIParkngSts_167_Reserved" 168 "AIParkngSts_168_Reserved" 169 "AIParkngSts_169_Reserved" 170 "AIParkngSts_170_Reserved" 171 "AIParkngSts_171_Reserved" 172 "AIParkngSts_172_Reserved" 173 "AIParkngSts_173_Reserved" 174 "AIParkngSts_174_Reserved" 175 "AIParkngSts_175_Reserved" 176 "AIParkngSts_176_Reserved" 177 "AIParkngSts_177_Reserved" 178 "AIParkngSts_178_Reserved" 179 "AIParkngSts_179_Reserved" 180 "AIParkngSts_180_Reserved" 181 "AIParkngSts_181_Reserved" 182 "AIParkngSts_182_Reserved" 183 "AIParkngSts_183_Reserved" 184 "AIParkngSts_184_Reserved" 185 "AIParkngSts_185_Reserved" 186 "AIParkngSts_186_Reserved" 187 "AIParkngSts_187_Reserved" 188 "AIParkngSts_188_Reserved" 189 "AIParkngSts_189_Reserved" 190 "AIParkngSts_190_Reserved" 191 "AIParkngSts_191_Reserved" 192 "AIParkngSts_192_Reserved" 193 "AIParkngSts_193_Reserved" 194 "AIParkngSts_194_Reserved" 195 "AIParkngSts_195_Reserved" 196 "AIParkngSts_196_Reserved" 197 "AIParkngSts_197_Reserved" 198 "AIParkngSts_198_Reserved" 199 "AIParkngSts_199_Reserved" 200 "AIParkngSts_200_Reserved" 201 "AIParkngSts_201_Reserved" 202 "AIParkngSts_202_Reserved" 203 "AIParkngSts_203_Reserved" 204 "AIParkngSts_204_Reserved" 205 "AIParkngSts_205_Reserved" 206 "AIParkngSts_206_Reserved" 207 "AIParkngSts_207_Reserved" 208 "AIParkngSts_208_Reserved" 209 "AIParkngSts_209_Reserved" 210 "AIParkngSts_210_Reserved" 211 "AIParkngSts_211_Reserved" 212 "AIParkngSts_212_Reserved" 213 "AIParkngSts_213_Reserved" 214 "AIParkngSts_214_Reserved" 215 "AIParkngSts_215_Reserved" 216 "AIParkngSts_216_Reserved" 217 "AIParkngSts_217_Reserved" 218 "AIParkngSts_218_Reserved" 219 "AIParkngSts_219_Reserved" 220 "AIParkngSts_220_Reserved" 221 "AIParkngSts_221_Reserved" 222 "AIParkngSts_222_Reserved" 223 "AIParkngSts_223_Reserved" 224 "AIParkngSts_224_Reserved" 225 "AIParkngSts_225_Reserved" 226 "AIParkngSts_226_Reserved" 227 "AIParkngSts_227_Reserved" 228 "AIParkngSts_228_Reserved" 229 "AIParkngSts_229_Reserved" 230 "AIParkngSts_230_Reserved" 231 "AIParkngSts_231_Reserved" 232 "AIParkngSts_232_Reserved" 233 "AIParkngSts_233_Reserved" 234 "AIParkngSts_234_Reserved" 235 "AIParkngSts_235_Reserved" 236 "AIParkngSts_236_Reserved" 237 "AIParkngSts_237_Reserved" 238 "AIParkngSts_238_Reserved" 239 "AIParkngSts_239_Reserved" 240 "AIParkngSts_240_Reserved" 241 "AIParkngSts_241_Reserved" 242 "AIParkngSts_242_Reserved" 243 "AIParkngSts_243_Reserved" 244 "AIParkngSts_244_Reserved" 245 "AIParkngSts_245_Reserved" 246 "AIParkngSts_246_Reserved" 247 "AIParkngSts_247_Reserved" 248 "AIParkngSts_248_Reserved" 249 "AIParkngSts_249_Reserved" 250 "AIParkngSts_250_Reserved" 251 "AIParkngSts_251_Reserved" 252 "AIParkngSts_252_Reserved" 253 "AIParkngSts_253_Reserved" 254 "AIParkngSts_254_Reserved" 255 "AIParkngSts_255_Reserved";
VAL_ 382 IACCSdslReq 0 "ACCSdslReq_0_No_Request" 1 "ACCSdslReq_1_Request";
VAL_ 382 IACCGoReq 0 "ACCGoReq_0_NoRequest" 1 "ACCGoReq_1_Request";
VAL_ 382 IACCAccReqSts_CH 0 "ACCAccReqSts_CH_0_No_Request" 1 "ACCAccReqSts_CH_1_ACC_Acceleration_Request";
VAL_ 382 IACCSysFltSts 0 "ACCSysFltSts_0_NoError" 1 "ACCSysFltSts_1_PerformanceDegradation" 2 "ACCSysFltSts_2_SystemTemporaryUnvailable" 3 "ACCSysFltSts_3_ServiceRequired" 4 "ACCSysFltSts_4_Reserved" 5 "ACCSysFltSts_5_Reserved" 6 "ACCSysFltSts_6_Reserved" 7 "ACCSysFltSts_7_Reserved";
VAL_ 382 IACCSysSts 0 "ACCSysSts_0_Off" 1 "ACCSysSts_1_StandBy" 2 "ACCSysSts_2_Active" 3 "ACCSysSts_3_Override" 4 "ACCSysSts_4_BrakeOnly" 5 "ACCSysSts_5_StandstillActive" 6 "ACCSysSts_6_StandstillWait" 7 "ACCSysSts_7_Reserved";
VAL_ 385 INSAReqAVMDis 0 "NSAReqAVMDis_0_NoRequest" 1 "NSAReqAVMDis_1_Request";
VAL_ 385 INSADisFucSts 0 "NSADisFucSts_0_Off" 1 "NSADisFucSts_1_Standby" 2 "NSADisFucSts_2_Active" 3 "NSADisFucSts_3_Fault";
VAL_ 385 INSABacSysSts 0 "NSABacSysSts_0_Off" 1 "NSABacSysSts_1_Standby" 2 "NSABacSysSts_2_BackwardActive" 3 "NSABacSysSts_3_Quit" 4 "NSABacSysSts_4_Error";
VAL_ 385 INSAForSysSts 0 "NSAForSysSts_0_Off" 1 "NSAForSysSts_1_Standby" 2 "NSAForSysSts_2_ForwardActive" 3 "NSAForSysSts_3_Quit" 4 "NSAForSysSts_4_Error" 5 "NSAForSysSts_5_Pause" 6 "NSAForSysSts_6_Reserve" 7 "NSAForSysSts_7_Reserve";
VAL_ 385 IILDP_ELKWrnng 0 "ILDP_ELKWrnng_0_Not_Active" 1 "ILDP_ELKWrnng_1_Take_Over_Warning" 2 "ILDP_ELKWrnng_2_Take_Over_Safety" 3 "ILDP_ELKWrnng_3_Suppressed" 4 "ILDP_ELKWrnng_4_Reserved" 5 "ILDP_ELKWrnng_5_Reserved" 6 "ILDP_ELKWrnng_6__Reserved" 7 "ILDP_ELKWrnng_7__Reserved";
VAL_ 343 IAEBPrflReq 0 "AEBPrflReq_0_False" 1 "AEBPrflReq_1_True";
VAL_ 343 IAEBSysSts 0 "AEBSysSts_0_Off" 1 "AEBSysSts_1_Standby" 2 "AEBSysSts_2_Disable" 3 "AEBSysSts_3_Override" 4 "AEBSysSts_4_Active" 5 "AEBSysSts_5_Reserved" 6 "AEBSysSts_6_Reserved" 7 "AEBSysSts_7_Reserved";
VAL_ 343 IAEBDclReqSts 0 "AEBDclReqSts_0_NoRequest" 1 "AEBDclReqSts_1_AebDecelerationRequest";
VAL_ 343 IAEBBrkJerkLvlReq 0 "AEBBrkJerkLvlReq_0_NoRequest" 1 "AEBBrkJerkLvlReq_1_Level1_low" 2 "AEBBrkJerkLvlReq_2_Level2_middle" 3 "AEBBrkJerkLvlReq_3_Level3_high";
VAL_ 343 IAEBHydBrkAstLvlReq 0 "AEBHydBrkAstLvlReq_0_NoRequest" 1 "AEBHydBrkAstLvlReq_1_Level1_low" 2 "AEBHydBrkAstLvlReq_2_Level2_middle" 3 "AEBHydBrkAstLvlReq_3_Level3_high" 4 "AEBHydBrkAstLvlReq_4_Reserved" 5 "AEBHydBrkAstLvlReq_5_Reserved" 6 "AEBHydBrkAstLvlReq_6_Reserved" 7 "AEBHydBrkAstLvlReq_7_Reserved";
VAL_ 343 IEBASysSts 0 "EBASysSts_0_Off" 1 "EBASysSts_1_Standby" 2 "EBASysSts_2_Disable" 3 "EBASysSts_3_Override" 4 "EBASysSts_4_Active" 5 "EBASysSts_5_Reserved" 6 "EBASysSts_6_Reserved" 7 "EBASysSts_7_Reserved";
VAL_ 343 IAEBSysFltSts 0 "AEBSysFltSts_0_NoError" 1 "AEBSysFltSts_1_PerformanceDegradation" 2 "AEBSysFltSts_2_SystemTemporaryUnvailable" 3 "AEBSysFltSts_3_ServiceRequired" 4 "AEBSysFltSts_4_Reserved" 5 "AEBSysFltSts_5_Reserved" 6 "AEBSysFltSts_6_Reserved" 7 "AEBSysFltSts_7_Reserved";
VAL_ 893 IAutodDrvngSysStsV 0 "AutodDrvngSysStsV_0_Valid" 1 "AutodDrvngSysStsV_1_Invalid";
VAL_ 360 IAPAShifterPosReqd 0 "APAShifterPosReqd_0_ScuInitialization" 1 "APAShifterPosReqd_1_S" 2 "APAShifterPosReqd_2_W" 3 "APAShifterPosReqd_3_M" 5 "APAShifterPosReqd_5_D" 6 "APAShifterPosReqd_6_N" 7 "APAShifterPosReqd_7_R" 8 "APAShifterPosReqd_8_P" 9 "APAShifterPosReqd_9_Reserved" 10 "APAShifterPosReqd_10_Error";
VAL_ 360 IAPASCUReqSts 0 "APASCUReqSts_0_No_Request" 1 "APASCUReqSts_1_Request" 2 "APASCUReqSts_2_Active" 3 "APASCUReqSts_3_Reversed";
VAL_ 360 IAPACmdEPSSts 0 "APACmdEPSSts_0_No_request" 1 "APACmdEPSSts_1_Control_EPS_request" 2 "APACmdEPSSts_2_EPS_control";
VAL_ 360 IAPAShifterPosReqdV 0 "APAShifterPosReqdV_0_Valid" 1 "APAShifterPosReqdV_1_Invalid";
VAL_ 360 IAPASCUReqStsV 0 "APASCUReqStsV_0_Valid" 1 "APASCUReqStsV_1_Invalid";
VAL_ 360 IAPAF 0 "APAF_0_Normal" 1 "APAF_1_APA_failure";
VAL_ 1122 IACCStsForEdr 0 "ACCStsForEdr_0_Off" 1 "ACCStsForEdr_1_OnbutNotControlling" 2 "ACCStsForEdr_2_ActivelyControlling" 3 "ACCStsForEdr_3_Faulted" 4 "ACCStsForEdr_4_Reserved" 5 "ACCStsForEdr_5_Reserved" 6 "ACCStsForEdr_6_Reserved" 7 "ACCStsForEdr_7_Non_Function";
VAL_ 1122 ILDWStsForEdr 0 "LDWStsForEdr_0_Deactivated" 1 "LDWStsForEdr_1_OnbutNotWarning" 2 "LDWStsForEdr_2_WarningLeft" 3 "LDWStsForEdr_3_WarningRight" 4 "LDWStsForEdr_4_Faulted" 5 "LDWStsForEdr_5_Reserved" 6 "LDWStsForEdr_6_Reserved" 7 "LDWStsForEdr_7_Non_Function";
VAL_ 1122 IAEBStsForEdr 0 "AEBStsForEdr_0_Deactivated" 1 "AEBStsForEdr_1_OnbutNotIntervening" 2 "AEBStsForEdr_2_WarningbutNotIntervening" 3 "AEBStsForEdr_3_Intervening" 4 "AEBStsForEdr_4_Faulted" 5 "AEBStsForEdr_5_Reserved" 6 "AEBStsForEdr_6_Reserved" 7 "AEBStsForEdr_7_Non_Function";
VAL_ 1122 IESFStsForEdr 0 "ESFStsForEdr_0_Off" 1 "ESFStsForEdr_1_On_but_Not_Intervening" 2 "ESFStsForEdr_2_Intervening" 3 "ESFStsForEdr_3_Faulted" 4 "ESFStsForEdr_4_Reserved" 5 "ESFStsForEdr_5_Reserved" 6 "ESFStsForEdr_6_Reserved" 7 "ESFStsForEdr_7_Non_Function";
VAL_ 1122 ICSFStsForEdr 0 "CSFStsForEdr_0_Off" 1 "CSFStsForEdr_1_OnbutNotIntervening" 2 "CSFStsForEdr_2_Intervening" 3 "CSFStsForEdr_3_Faulted" 4 "CSFStsForEdr_4_Reserved" 5 "CSFStsForEdr_5_Reserved" 6 "CSFStsForEdr_6_Reserved" 7 "CSFStsForEdr_7_Non_Function";
VAL_ 1122 IACSFCatgrB1StsForEdr 0 "ACSFCatgrB1StsForEdr_0_Off" 1 "ACSFCatgrB1StsForEdr_1_Standby" 2 "ACSFCatgrB1StsForEdr_2_Active" 3 "ACSFCatgrB1StsForEdr_3_Faulted" 4 "ACSFCatgrB1StsForEdr_4_Reserved" 5 "ACSFCatgrB1StsForEdr_5_Reserved" 6 "ACSFCatgrB1StsForEdr_6_Reserved" 7 "ACSFCatgrB1StsForEdr_7_Non_Function";
VAL_ 1122 IACSFCatgrAStsForEdr 0 "ACSFCatgrAStsForEdr_0_Off" 1 "ACSFCatgrAStsForEdr_1_Standby" 2 "ACSFCatgrAStsForEdr_2_Active" 3 "ACSFCatgrAStsForEdr_3_Faulted" 4 "ACSFCatgrAStsForEdr_4_Reserved" 5 "ACSFCatgrAStsForEdr_5_Reserved" 6 "ACSFCatgrAStsForEdr_6_Reserved" 7 "ACSFCatgrB1StsForEdr_7_Non_Function";
VAL_ 1122 IACSFCatgrCStsForEdr 0 "ACSFCatgrCStsForEdr_0_Off" 1 "ACSFCatgrCStsForEdr_1_Standby" 2 "ACSFCatgrCStsForEdr_2_Active" 3 "ACSFCatgrCStsForEdr_3_Faulted" 4 "ACSFCatgrCStsForEdr_4_Reserved" 5 "ACSFCatgrCStsForEdr_5_Reserved" 6 "ACSFCatgrCStsForEdr_6_Reserved" 7 "ACSFCatgrCStsForEdr_7_Non_Function";
VAL_ 1122 IACSFCatgrB2StsForEdr 0 "ACSFCatgrB2StsForEdr_0_Off" 1 "ACSFCatgrB2StsForEdr_1_Standby" 2 "ACSFCatgrB2StsForEdr_2_Active" 3 "ACSFCatgrB2StsForEdr_3_Faulted" 4 "ACSFCatgrB2StsForEdr_4_Reserved" 5 "ACSFCatgrB2StsForEdr_5_Reserved" 6 "ACSFCatgrB2StsForEdr_6_Reserved" 7 "ACSFCatgrB2StsForEdr_7_Non_Function";
VAL_ 1122 IACSFCatgrEStsForEdr 0 "ACSFCatgrEStsForEdr_0_Off" 1 "ACSFCatgrEStsForEdr_1_Standby" 2 "ACSFCatgrEStsForEdr_2_Active" 3 "ACSFCatgrEStsForEdr_3_Faulted" 4 "ACSFCatgrEStsForEdr_4_Reserved" 5 "ACSFCatgrEStsForEdr_5_Reserved" 6 "ACSFCatgrEStsForEdr_6_Reserved" 7 "ACSFCatgrEStsForEdr_7_Non_Function";
VAL_ 1122 IACSFCatgrDStsForEdr 0 "ACSFCatgrDStsForEdr_0_Off" 1 "ACSFCatgrDStsForEdr_1_Standby" 2 "ACSFCatgrDStsForEdr_2_Active" 3 "ACSFCatgrDStsForEdr_3_Faulted" 4 "ACSFCatgrDStsForEdr_4_Reserved" 5 "ACSFCatgrDStsForEdr_5_Reserved" 6 "ACSFCatgrDStsForEdr_6_Reserved" 7 "ACSFCatgrDStsForEdr_7_Non_Function";
VAL_ 474 ILDWLKARVsulznReq 0 "LDWLKARVsulznReq_0_no_display" 1 "LDWLKARVsulznReq_1_line_tracking" 2 "LDWLKARVsulznReq_2_intervention" 3 "LDWLKARVsulznReq_3_warning" 4 "LDWLKARVsulznReq_4_intervention_and_warning" 5 "LDWLKARVsulznReq_5_Reserved" 6 "LDWLKARVsulznReq_6_Reserved" 7 "LDWLKARVsulznReq_7_Reserved";
VAL_ 474 ILDWLKAVbnLvlReq 0 "LDWLKAVbnLvlReq_0_LDWLKAVbnLvlReq_0_no_request" 1 "LDWLKAVbnLvlReq_1_LDWLKAVbnLvlReq_1_Level_1" 2 "LDWLKAVbnLvlReq_2_LDWLKAVbnLvlReq_2_Level_2" 3 "LDWLKAVbnLvlReq_3_LDWLKAVbnLvlReq_3_Level_3";
VAL_ 474 ILDWSysFltSts 0 "LDWSysFltSts_0_no_error" 1 "LDWSysFltSts_1_performance_degradation" 2 "LDWSysFltSts_2_system_temporary_unavailable" 3 "LDWSysFltSts_3_service_required" 4 "LDWSysFltSts_4_Reserved" 5 "LDWSysFltSts_5_Reserved" 6 "LDWSysFltSts_6_Reserved" 7 "LDWSysFltSts_7_Reserved";
VAL_ 474 ILDWSysSts 0 "LDWSysSts_0_Off" 1 "LDWSysSts_1_Stand_by" 2 "LDWSysSts_2_Active" 3 "LDWSysSts_3_Override" 4 "LDWSysSts_4_service_required" 5 "LDWSysSts_5_system_temporary_unavailable" 6 "LDWSysSts_6_eserved" 7 "LDWSysSts_7_reserved";
VAL_ 474 ILDWLKALVsulznReq 0 "LDWLKALVsulznReq_0_no_display" 1 "LDWLKALVsulznReq_1_line_tracking" 2 "LDWLKALVsulznReq_2_intervention" 3 "LDWLKALVsulznReq_3_warning" 4 "LDWLKALVsulznReq_4_intervention_and_warning" 5 "LDWLKALVsulznReq_5_Reserved" 6 "LDWLKALVsulznReq_6_Reserved" 7 "LDWLKALVsulznReq_7_Reserved";
VAL_ 520 IRoadProfileShockLevelL 0 "RoadProfileShockLevelL_0_NotDefined" 1 "RoadProfileShockLevelL_1_level1" 2 "RoadProfileShockLevelL_2_level2" 3 "RoadProfileShockLevelL_3_level3" 4 "RoadProfileShockLevelL_4_level4" 5 "RoadProfileShockLevelL_5_level5" 6 "RoadProfileShockLevelL_6_level6" 7 "RoadProfileShockLevelL_7_level7" 8 "RoadProfileShockLevelL_8_level8";
VAL_ 520 IRoadProfileShockLevelR 0 "RoadProfileShockLevelR_0_NotDefined" 1 "RoadProfileShockLevelR_1_level1" 2 "RoadProfileShockLevelR_2_level2" 3 "RoadProfileShockLevelR_3_level3" 4 "RoadProfileShockLevelR_4_level4" 5 "RoadProfileShockLevelR_5_level5" 6 "RoadProfileShockLevelR_6_level6" 7 "RoadProfileShockLevelR_7_level7" 8 "RoadProfileShockLevelR_8_level8";
VAL_ 520 IRoadProfileShockDetectedL 0 "RoadProfileShockDetectedL_0_NotDetected" 1 "RoadProfileShockDetectedL_1_Detected";
VAL_ 520 IRoadProfileShockDetectedR 0 "RoadProfileShockDetectedR_0_NotDetected" 1 "RoadProfileShockDetectedR_1_Detected";
VAL_ 502 ICldBdyAdjReq 0 "CldBdyAdjSts_0_Noaction" 1 "CldBdyAdjSts_1_LeftLiftOReightLower" 2 "CldBdyAdjSts_2_LeftLowerOReightLift" 3 "CldBdyAdjSts_3_Holding" 4 "CldBdyAdjReq_4_Reserved" 5 "CldBdyAdjReq_5_Reserved" 6 "CldBdyAdjReq_6_Reserved" 7 "CldBdyAdjReq_7_Reserved" 8 "CldBdyAdjReq_8_Reserved" 9 "CldBdyAdjReq_9_Reserved" 10 "CldBdyAdjReq_10_Reserved" 11 "CldBdyAdjReq_11_Reserved" 12 "CldBdyAdjReq_12_Reserved" 13 "CldBdyAdjReq_13_Reserved" 14 "CldBdyAdjReq_14_Reserved" 15 "CldBdyAdjReq_15_Reserved";
VAL_ 502 IVMCExtrmOutSts 0 "VMCExtrmOutSts_0_off" 1 "VMCExtrmOutSts_1_standby" 2 "VMCExtrmOutSts_2_Active" 3 "VMCExtrmOutSts_3_Finish";
VAL_ 502 IVMCSusHghtLvlReqFA 0 "VMCSusHghtLvlReqFA_0_Not_Requested" 1 "VMCSusHghtLvlReqFA_1_High_Level_2" 2 "VMCSusHghtLvlReqFA_2_High_Level_1" 3 "VMCSusHghtLvlReqFA_3_Normal_Level" 4 "VMCSusHghtLvlReqFA_4_Low_Level_1" 5 "VMCSusHghtLvlReqFA_5_Low_Level_2" 6 "VMCSusHghtLvlReqFA_6_Low_Level_3" 7 "VMCSusHghtLvlReqFA_7_Reserved";
VAL_ 502 IVMCASCActvnReq 0 "VMCASCActvnReq_0_Control_Not_Requested" 1 "VMCASCActvnReq_1_Control_Requested" 2 "VMCASCActvnReq_2_Reserved" 3 "VMCASCActvnReq_3_Reserved" 4 "VMCASCActvnReq_4_Reserved" 5 "VMCASCActvnReq_5_Reserved" 6 "VMCASCActvnReq_6_Reserved" 7 "VMCASCActvnReq_7_Reserved";
VAL_ 502 IVMCSusHghtLvlReqLSide 0 "VMCSusHghtLvlReqLSide_0_Not_Requested" 1 "VMCSusHghtLvlReqLSide_1_HighLevel" 2 "VMCSusHghtLvlReqLSide_2_NormalLevel" 3 "VMCSusHghtLvlReqLSide_3_LowLevel1" 4 "VMCSusHghtLvlReqLSide_4_LowLevel2" 5 "VMCSusHghtLvlReqLSide_5_LowLevel3" 6 "VMCSusHghtLvlReqLSide_6_lauchmodelevel" 7 "VMCSusHghtLvlReqLSide_7_DLPProjectionLevel" 8 "VMCSusHghtLvlReqLSide_8_Easyloading" 9 "VMCSusHghtLvlReqLSide_9_Reserved" 10 "VMCSusHghtLvlReqLSide_10_Reserved" 11 "VMCSusHghtLvlReqLSide_11_Reserved" 12 "VMCSusHghtLvlReqLSide_12_Reserved" 13 "VMCSusHghtLvlReqLSide_13_Reserved" 14 "VMCSusHghtLvlReqLSide_14_Reserved" 15 "VMCSusHghtLvlReqLSide_15_Reserved";
VAL_ 502 IVMCSusHghtLvlReqRA 0 "VMCSusHghtLvlReqRA_0_Not_Requested" 1 "VMCSusHghtLvlReqRA_1_High_Level_2" 2 "VMCSusHghtLvlReqRA_2_High_Level_1" 3 "VMCSusHghtLvlReqRA_3_Normal_Level" 4 "VMCSusHghtLvlReqRA_4_Low_Level_1" 5 "VMCSusHghtLvlReqRA_5_Low_Level_2" 6 "VMCSusHghtLvlReqRA_6_Low_Level_3" 7 "VMCSusHghtLvlReqRA_7_Reserved";
VAL_ 502 IVMCLvlCtrlReqdTrgtLvl 0 "VMCLvlCtrlReqdTrgtLvl_0_HighLevel" 1 "VMCLvlCtrlReqdTrgtLvl_1_NormalLevel" 2 "VMCLvlCtrlReqdTrgtLvl_2_LowLevel1" 3 "VMCLvlCtrlReqdTrgtLvl_3_LowLevel2" 4 "VMCLvlCtrlReqdTrgtLvl_4_LowLevel3" 5 "VMCLvlCtrlReqdTrgtLvl_5_lauchmodelevel" 6 "VMCLvlCtrlReqdTrgtLvl_6_DLPProjectionLevel" 7 "VMCLvlCtrlReqdTrgtLvl_7_Easyloading" 8 "VMCLvlCtrlReqdTrgtLvl_8_ExtrePss" 9 "VMCLvlCtrlReqdTrgtLvl_9_Reserved" 10 "VMCLvlCtrlReqdTrgtLvl_10_Reserved" 11 "VMCLvlCtrlReqdTrgtLvl_11_Reserved" 12 "VMCLvlCtrlReqdTrgtLvl_12_Reserved" 13 "VMCLvlCtrlReqdTrgtLvl_13_Reserved" 14 "VMCLvlCtrlReqdTrgtLvl_14_Reserved" 15 "VMCLvlCtrlReqdTrgtLvl_15_Reserved";
VAL_ 502 IVMCSusHghtLvlReqRSide 0 "VMCSusHghtLvlReqRSide_0_Not_Requested" 1 "VMCSusHghtLvlReqRSide_1_HighLevel" 2 "VMCSusHghtLvlReqRSide_2_NormalLevel" 3 "VMCSusHghtLvlReqRSide_3_LowLevel1" 4 "VMCSusHghtLvlReqRSide_4_LowLevel2" 5 "VMCSusHghtLvlReqRSide_5_LowLevel3" 6 "VMCSusHghtLvlReqRSide_6_lauchmodelevel" 7 "VMCSusHghtLvlReqRSide_7_DLPProjectionLevel" 8 "VMCSusHghtLvlReqRSide_8_Easyloading" 9 "VMCSusHghtLvlReqRSide_9_Reserved" 10 "VMCSusHghtLvlReqRSide_10_Reserved" 11 "VMCSusHghtLvlReqRSide_11_Reserved" 12 "VMCSusHghtLvlReqRSide_12_Reserved" 13 "VMCSusHghtLvlReqRSide_13_Reserved" 14 "VMCSusHghtLvlReqRSide_14_Reserved" 15 "VMCSusHghtLvlReqRSide_15_Reserved";
VAL_ 502 IAddlVolmVlvReq 0 "AddlVolmVlvReq_0_AllOpen" 1 "AddlVolmVlvReq_1_FLClose" 2 "AddlVolmVlvReq_2_FRClose" 4 "AddlVolmVlvReq_4_RLClose" 8 "AddlVolmVlvReq_8_RRClose";
SIG_GROUP_ 430 IEPS_20ms_Group03 1 : IEPSAPAInh IEPSAPASts IEPS_20ms_Group03_CRC IEPS_20ms_Group03_RC IEPS_20ms_Group03_Reserved1 IEPS_20ms_Group03_Reserved2 IEPS_20ms_Group03_Reserved3 IEPS_20ms_Group03_Reserved4 IEPS_20ms_Group03_Reserved5;
SIG_GROUP_ 163 IFVCM_10ms_Group01 1 : IFVCM_10ms_Group01_CRC IFVCM_10ms_Group01_RC IFVCM_10ms_Group01_Reserved1 IFVCM_10ms_Group01_Reserved2 IFVCM_10ms_Group01_Reserved3 IFVCM_10ms_Group01_Reserved4 IFVCM_10ms_Group01_Reserved5 IFVCM_10ms_Group01_Reserved6 IFVCM_10ms_Group01_Reserved7 ILKAReqAng ILKAReqAngSts ILKAReqToq ILKAReqToqSts;
SIG_GROUP_ 318 IIBS_10ms_Group01 1 : ILDrvnWhlRotlDistPlsCtr ILDrvnWhlRotlDistTRC ILDrvnWhlRotlDistTmsp ILDrvnWhlRotlDistV ILDrvnWhlRotlRstOcd ILDrvnWhlRotlSeqNum IRDrvnWhlRotlDistPlsCtr IRDrvnWhlRotlDistTRC IRDrvnWhlRotlDistTmsp IRDrvnWhlRotlDistV IRDrvnWhlRotlRstOcd IRDrvnWhlRotlSeqNum;
SIG_GROUP_ 319 IIBS_10ms_Group02 1 : ILNonDrvnWhlRotlDistPC ILNonDrvnWhlRotlDistT ILNonDrvnWhlRotlDistTRC ILNonDrvnWhlRotlDistV ILNonDrvnWhlRotlRstOcd ILNonDrvnWhlRotlSeqNum IRNonDrvnWhlRotlDistPC IRNonDrvnWhlRotlDistT IRNonDrvnWhlRotlDistTRC IRNonDrvnWhlRotlDistV IRNonDrvnWhlRotlRstOcd IRNonDrvnWhlRotlSeqNum;
SIG_GROUP_ 423 IIBS_20ms_Group07 1 : IABSA IABSF IABSIO IAVHSigPdlSts IAutoHoldMdSts IAutoHoldMsg IAutoHoldSysSts IBrkSysHillStAstAvlbl IBrkSysHillStAstSts IBrkSysRedBrkTlltReq IBrkSysYlwBrkTlltReq IEBDA IEBDFaultSt IEmgcBrkA IEmgcBrkAV IEnDragToqRducnA IHBAActiveSt IHBAValidSt IHDCSysSts IIBS_20ms_Group07_CRC IIBS_20ms_Group07_RC IMSRA IMSRF IMulColBrkA IMulColBrkAvlblySts IMultColBrkEnbA IRgtvBrkFnFltSts IRgtvBrkFnSts ISoftSpSysSts ITCSA ITCSEnbd ITCSOpngMd ITCSOpngSts IVSEMd IVSESts IVSESysA;
SIG_GROUP_ 342 IIBS_20ms_Group08 1 : IChSysSecyBrkAxleToqVal IChSysSecyBrkAxleToqValV IChSysTrBrkAxleToqVal IChSysTrBrkAxleToqValV IEPBAPAAvlbl IEPBAppcnSts IEPBAvlblySts IEPBCCCanclReqd IEPBFlrSts IEPBSts IEPBSwSts IEPBSwStsV IEPBSysAudWrnngReq IEPBSysDspMsgReq IEPBSysStsIndReq IEPBSysWrnngIndReq IIBS_20ms_Group08_CRC IIBS_20ms_Group08_RC;
SIG_GROUP_ 329 IIBS_20ms_Group09 1 : IChSysTotBrkAxleToqVal IChSysTotBrkAxleToqValV IIBS_20ms_Group09_CRC IIBS_20ms_Group09_RC IIBS_20ms_Group09_Reserved1 ILDrvnWhlRotlDircn ILDrvnWhlRotlDircnSdslSts IRDrvnWhlRotlDircn IRDrvnWhlRotlDircnSdslSts IWhlGndVelLDrvn IWhlGndVelLDrvnV IWhlGndVelRDrvn IWhlGndVelRDrvnV;
SIG_GROUP_ 425 IIBS_20ms_Group11 1 : IIBS_20ms_Group11_CRC IIBS_20ms_Group11_RC IIBS_20ms_Group11_Reserved1 IVehSpdAvg IVehSpdAvgDrvn IVehSpdAvgDrvnSrc IVehSpdAvgDrvnV IVehSpdAvgNonDrvn IVehSpdAvgNonDrvnV IVehSpdAvgV;
SIG_GROUP_ 339 IIBS_20ms_Group12 1 : IIBS_20ms_Group12_CRC IIBS_20ms_Group12_RC IIBS_20ms_Group12_Reserved1 IIBS_20ms_Group12_Reserved2 ILNonDrvnWhlRotlDircn ILNonDrvnWhlRotlDircnSdslSts IRNonDrvnWhlRotlDircn IRNonDrvnWhlRotlDircnSdslSts IWhlGndVelLNonDrvn IWhlGndVelLNonDrvnV IWhlGndVelRNonDrvn IWhlGndVelRNonDrvnV;
SIG_GROUP_ 507 IIBS_ZONE_20ms_Group08 1 : IBrkBstFnSts IEPBAppcnSts_M IIBSRespAccToqVal IIBS_ZONE_20ms_Group08_CRC IIBS_ZONE_20ms_Group08_RC IIBS_ZONE_20ms_Group08_Reserved1 IIBS_ZONE_20ms_Group08_Reserved2 IIBS_ZONE_20ms_Group08_Reserved3 IIBS_ZONE_20ms_Group08_Reserved4 IIBS_ZONE_20ms_Group08_Reserved5;
SIG_GROUP_ 382 IICBAD_20ms_Group07 1 : IACCAccReqSts_CH IACCAccReqVal IACCGoReq IACCSdslReq IACCSysFltSts IACCSysSts IICBAD_20ms_Group07_CRC IICBAD_20ms_Group07_RC IICBAD_20ms_Group07_Reserved1 IICBAD_20ms_Group07_Reserved2 IICBAD_20ms_Group07_Reserved3 IICBAD_20ms_Group07_Reserved4 IICBAD_20ms_Group07_Reserved5 IICBAD_20ms_Group07_Reserved6;
SIG_GROUP_ 343 IICBAD_20ms_Group46 1 : IAEBBrkJerkLvlReq IAEBDclReqSts IAEBDclReqToqVal IAEBDclReqVal IAEBHydBrkAstLvlReq IAEBPrflReq IAEBSysFltSts IAEBSysSts IEBASysSts IICBAD_20ms_Group46_CRC IICBAD_20ms_Group46_RC IICBAD_20ms_Group46_Reserved1 IICBAD_20ms_Group46_Reserved2;
SIG_GROUP_ 893 IICBAD_100ms_Group25 1 : IAutodDrvngSysStsV IICBAD_100ms_Group25_CRC IICBAD_100ms_Group25_RC IICBAD_100ms_Group25_Reserved1 IICBAD_100ms_Group25_Reserved2 IICBAD_100ms_Group25_Reserved3 IICBAD_100ms_Group25_Reserved4 IICBAD_100ms_Group25_Reserved5 IICBAD_100ms_Group25_Reserved6 IICBAD_100ms_Group25_Reserved7;
SIG_GROUP_ 360 IICBAD_20ms_Group13 1 : IAPACmdEPSSts IAPAF IAPASCUReqSts IAPASCUReqStsV IAPAShifterPosReqd IAPAShifterPosReqdV IAPATrgtEPSStrgWhlAng IICBAD_20ms_Group13_CRC IICBAD_20ms_Group13_RC IICBAD_20ms_Group13_Reserved1 IICBAD_20ms_Group13_Reserved2 IICBAD_20ms_Group13_Reserved3 IICBAD_20ms_Group13_Reserved4 IICBAD_20ms_Group13_Reserved5;
SIG_GROUP_ 474 IICBAD_20ms_Group48 1 : IICBAD_20ms_Group48_CRC IICBAD_20ms_Group48_RC IICBAD_20ms_Group48_Reserved1 IICBAD_20ms_Group48_Reserved2 IICBAD_20ms_Group48_Reserved3 IICBAD_20ms_Group48_Reserved4 IICBAD_20ms_Group48_Reserved5 IICBAD_20ms_Group48_Reserved6 ILDWLKALVsulznReq ILDWLKARVsulznReq ILDWLKAVbnLvlReq ILDWSysFltSts ILDWSysSts;
SIG_GROUP_ 98 IICBAD_ZONE_10ms_Group20 1 : IICBAD_ZONE_10ms_Group20_CRC IICBAD_ZONE_10ms_Group20_RC IICBAD_ZONE_10ms_Group20_Reserve0 IICBAD_ZONE_10ms_Group20_Reserve1 IICBAD_ZONE_10ms_Group20_Reserve2 IICBAD_ZONE_10ms_Group20_Reserve3 IICBAD_ZONE_10ms_Group20_Reserve4 IICBAD_ZONE_10ms_Group20_Reserve5 ILKAToqReqValMax ILKAToqReqValMin;
SIG_GROUP_ 502 IIMCU_20ms_Group58 1 : IAddlVolmVlvReq ICldBdyAdjReq IIMCU_20ms_Group58_CRC IIMCU_20ms_Group58_RC IIMCU_20ms_Group58_Reserved1 IIMCU_20ms_Group58_Reserved11 IIMCU_20ms_Group58_Reserved2 IIMCU_20ms_Group58_Reserved4 IIMCU_20ms_Group58_Reserved5 IIMCU_20ms_Group58_Reserved6 IIMCU_20ms_Group58_Reserved7 IIMCU_20ms_Group58_Reserved8 IIMCU_20ms_Group58_Reserved9 IVMCASCActvnReq IVMCExtrmOutSts IVMCLvlCtrlReqdTrgtLvl IVMCSusHghtLvlReqFA IVMCSusHghtLvlReqLSide IVMCSusHghtLvlReqRA IVMCSusHghtLvlReqRSide IVMCSusHghtReqFL IVMCSusHghtReqFR IVMCSusHghtReqRL IVMCSusHghtReqRR;
